VERSION ""

NS_ :

BS_:

BU_: TBox

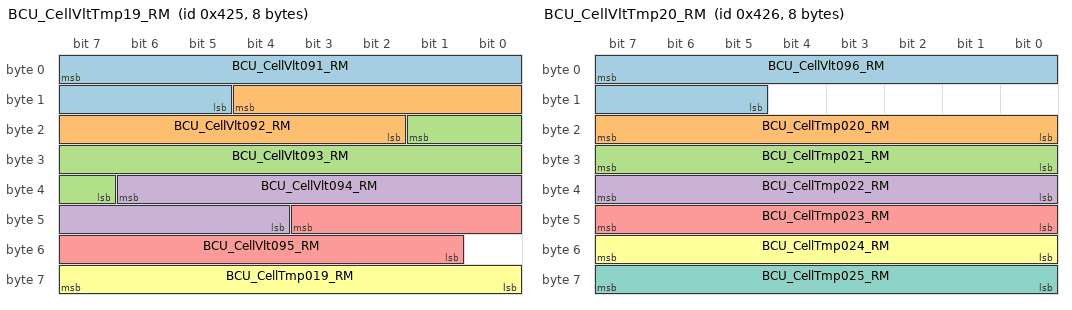
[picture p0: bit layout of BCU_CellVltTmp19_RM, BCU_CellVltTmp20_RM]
BO_ 1061 BCU_CellVltTmp19_RM: 8 CGW
 SG_ BCU_CellVlt091_RM : 7|11@0+ (0.01,0) [0|18] "V" TBox
 SG_ BCU_CellVlt092_RM : 12|11@0+ (0.01,0) [0|18] "V" TBox
 SG_ BCU_CellVlt093_RM : 17|11@0+ (0.01,0) [0|18] "V" TBox
 SG_ BCU_CellVlt094_RM : 38|11@0+ (0.01,0) [0|18] "V" TBox
 SG_ BCU_CellVlt095_RM : 43|11@0+ (0.01,0) [0|18] "V" TBox
 SG_ BCU_CellTmp019_RM : 63|8@0+ (1,-40) [-40|120] "℃" TBox

BO_ 1062 BCU_CellVltTmp20_RM: 8 CGW
 SG_ BCU_CellVlt096_RM : 7|11@0+ (0.01,0) [0|18] "V" TBox
 SG_ BCU_CellTmp020_RM : 23|8@0+ (1,-40) [-40|120] "℃" TBox
 SG_ BCU_CellTmp021_RM : 31|8@0+ (1,-40) [-40|120] "℃" TBox
 SG_ BCU_CellTmp022_RM : 39|8@0+ (1,-40) [-40|120] "℃" TBox
 SG_ BCU_CellTmp023_RM : 47|8@0+ (1,-40) [-40|120] "℃" TBox
 SG_ BCU_CellTmp024_RM : 55|8@0+ (1,-40) [-40|120] "℃" TBox
 SG_ BCU_CellTmp025_RM : 63|8@0+ (1,-40) [-40|120] "℃" TBox

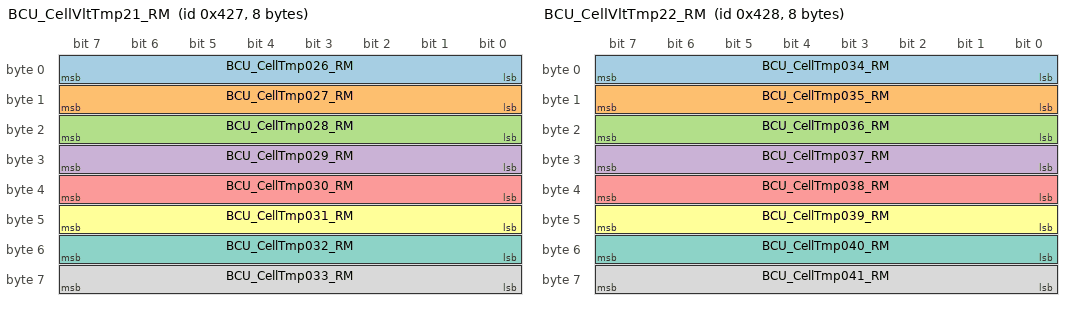
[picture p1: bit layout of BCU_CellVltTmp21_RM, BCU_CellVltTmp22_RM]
BO_ 1063 BCU_CellVltTmp21_RM: 8 CGW
 SG_ BCU_CellTmp026_RM : 7|8@0+ (1,-40) [-40|120] "℃" TBox
 SG_ BCU_CellTmp027_RM : 15|8@0+ (1,-40) [-40|120] "℃" TBox
 SG_ BCU_CellTmp028_RM : 23|8@0+ (1,-40) [-40|120] "℃" TBox
 SG_ BCU_CellTmp029_RM : 31|8@0+ (1,-40) [-40|120] "℃" TBox
 SG_ BCU_CellTmp030_RM : 39|8@0+ (1,-40) [-40|120] "℃" TBox
 SG_ BCU_CellTmp031_RM : 47|8@0+ (1,-40) [-40|120] "℃" TBox
 SG_ BCU_CellTmp032_RM : 55|8@0+ (1,-40) [-40|120] "℃" TBox
 SG_ BCU_CellTmp033_RM : 63|8@0+ (1,-40) [-40|120] "℃" TBox

BO_ 1064 BCU_CellVltTmp22_RM: 8 CGW
 SG_ BCU_CellTmp034_RM : 7|8@0+ (1,-40) [-40|120] "℃" TBox
 SG_ BCU_CellTmp035_RM : 15|8@0+ (1,-40) [-40|120] "℃" TBox
 SG_ BCU_CellTmp036_RM : 23|8@0+ (1,-40) [-40|120] "℃" TBox
 SG_ BCU_CellTmp037_RM : 31|8@0+ (1,-40) [-40|120] "℃" TBox
 SG_ BCU_CellTmp038_RM : 39|8@0+ (1,-40) [-40|120] "℃" TBox
 SG_ BCU_CellTmp039_RM : 47|8@0+ (1,-40) [-40|120] "℃" TBox
 SG_ BCU_CellTmp040_RM : 55|8@0+ (1,-40) [-40|120] "℃" TBox
 SG_ BCU_CellTmp041_RM : 63|8@0+ (1,-40) [-40|120] "℃" TBox

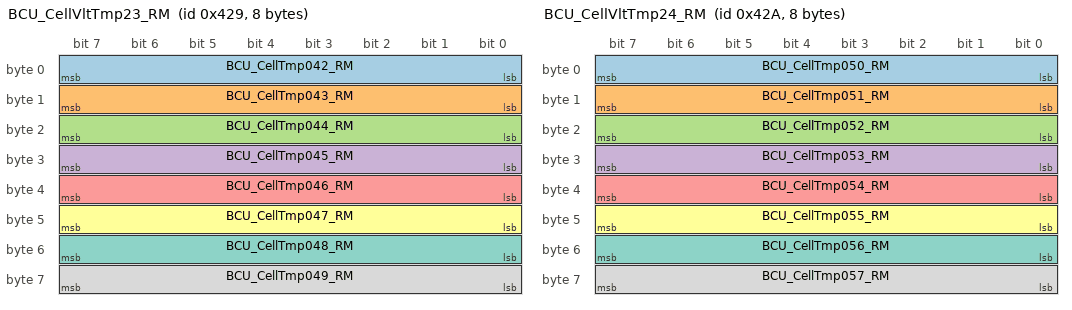
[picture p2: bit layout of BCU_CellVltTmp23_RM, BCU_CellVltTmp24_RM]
BO_ 1065 BCU_CellVltTmp23_RM: 8 CGW
 SG_ BCU_CellTmp042_RM : 7|8@0+ (1,-40) [-40|120] "℃" TBox
 SG_ BCU_CellTmp043_RM : 15|8@0+ (1,-40) [-40|120] "℃" TBox
 SG_ BCU_CellTmp044_RM : 23|8@0+ (1,-40) [-40|120] "℃" TBox
 SG_ BCU_CellTmp045_RM : 31|8@0+ (1,-40) [-40|120] "℃" TBox
 SG_ BCU_CellTmp046_RM : 39|8@0+ (1,-40) [-40|120] "℃" TBox
 SG_ BCU_CellTmp047_RM : 47|8@0+ (1,-40) [-40|120] "℃" TBox
 SG_ BCU_CellTmp048_RM : 55|8@0+ (1,-40) [-40|120] "℃" TBox
 SG_ BCU_CellTmp049_RM : 63|8@0+ (1,-40) [-40|120] "℃" TBox

BO_ 1066 BCU_CellVltTmp24_RM: 8 CGW
 SG_ BCU_CellTmp050_RM : 7|8@0+ (1,-40) [-40|120] "℃" TBox
 SG_ BCU_CellTmp051_RM : 15|8@0+ (1,-40) [-40|120] "℃" TBox
 SG_ BCU_CellTmp052_RM : 23|8@0+ (1,-40) [-40|120] "℃" TBox
 SG_ BCU_CellTmp053_RM : 31|8@0+ (1,-40) [-40|120] "℃" TBox
 SG_ BCU_CellTmp054_RM : 39|8@0+ (1,-40) [-40|120] "℃" TBox
 SG_ BCU_CellTmp055_RM : 47|8@0+ (1,-40) [-40|120] "℃" TBox
 SG_ BCU_CellTmp056_RM : 55|8@0+ (1,-40) [-40|120] "℃" TBox
 SG_ BCU_CellTmp057_RM : 63|8@0+ (1,-40) [-40|120] "℃" TBox

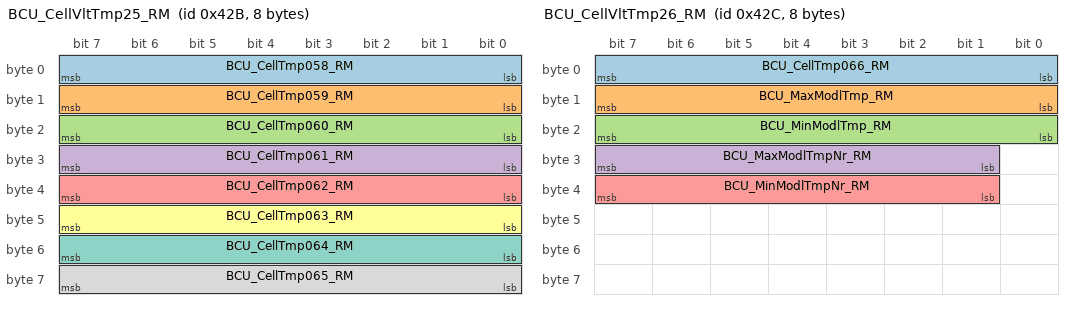
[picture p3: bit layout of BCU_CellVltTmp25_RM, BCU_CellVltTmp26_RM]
BO_ 1067 BCU_CellVltTmp25_RM: 8 CGW
 SG_ BCU_CellTmp058_RM : 7|8@0+ (1,-40) [-40|120] "℃" TBox
 SG_ BCU_CellTmp059_RM : 15|8@0+ (1,-40) [-40|120] "℃" TBox
 SG_ BCU_CellTmp060_RM : 23|8@0+ (1,-40) [-40|120] "℃" TBox
 SG_ BCU_CellTmp061_RM : 31|8@0+ (1,-40) [-40|120] "℃" TBox
 SG_ BCU_CellTmp062_RM : 39|8@0+ (1,-40) [-40|120] "℃" TBox
 SG_ BCU_CellTmp063_RM : 47|8@0+ (1,-40) [-40|120] "℃" TBox
 SG_ BCU_CellTmp064_RM : 55|8@0+ (1,-40) [-40|120] "℃" TBox
 SG_ BCU_CellTmp065_RM : 63|8@0+ (1,-40) [-40|120] "℃" TBox

BO_ 1068 BCU_CellVltTmp26_RM: 8 CGW
 SG_ BCU_CellTmp066_RM : 7|8@0+ (1,-40) [-40|120] "℃" TBox
 SG_ BCU_MaxModlTmp_RM : 15|8@0+ (1,-40) [-40|120] "℃" TBox
 SG_ BCU_MinModlTmp_RM : 23|8@0+ (1,-40) [-40|120] "℃" TBox
 SG_ BCU_MaxModlTmpNr_RM : 31|7@0+ (1,0) [0|120] "℃" TBox
 SG_ BCU_MinModlTmpNr_RM : 39|7@0+ (1,0) [0|120] "℃" TBox

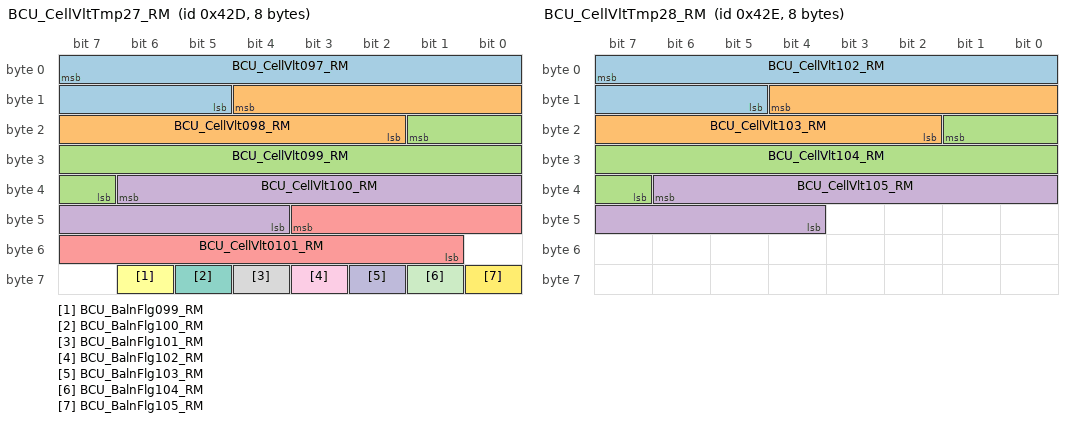
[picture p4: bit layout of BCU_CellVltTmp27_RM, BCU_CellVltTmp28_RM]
BO_ 1069 BCU_CellVltTmp27_RM: 8 CGW
 SG_ BCU_CellVlt097_RM : 7|11@0+ (0.01,0) [0|18] "V" TBox
 SG_ BCU_CellVlt098_RM : 12|11@0+ (0.01,0) [0|18] "V" TBox
 SG_ BCU_CellVlt099_RM : 17|11@0+ (0.01,0) [0|18] "V" TBox
 SG_ BCU_CellVlt100_RM : 38|11@0+ (0.01,0) [0|18] "V" TBox
 SG_ BCU_CellVlt0101_RM : 43|11@0+ (0.01,0) [0|18] "V" TBox
 SG_ BCU_BalnFlg099_RM : 62|1@0+ (1,0) [0|1] "" TBox
 SG_ BCU_BalnFlg100_RM : 61|1@0+ (1,0) [0|1] "" TBox
 SG_ BCU_BalnFlg101_RM : 60|1@0+ (1,0) [0|1] "" TBox
 SG_ BCU_BalnFlg102_RM : 59|1@0+ (1,0) [0|1] "" TBox
 SG_ BCU_BalnFlg103_RM : 58|1@0+ (1,0) [0|1] "" TBox
 SG_ BCU_BalnFlg104_RM : 57|1@0+ (1,0) [0|1] "" TBox
 SG_ BCU_BalnFlg105_RM : 56|1@0+ (1,0) [0|1] "" TBox

BO_ 1070 BCU_CellVltTmp28_RM: 8 CGW
 SG_ BCU_CellVlt102_RM : 7|11@0+ (0.01,0) [0|18] "V" TBox
 SG_ BCU_CellVlt103_RM : 12|11@0+ (0.01,0) [0|18] "V" TBox
 SG_ BCU_CellVlt104_RM : 17|11@0+ (0.01,0) [0|18] "V" TBox
 SG_ BCU_CellVlt105_RM : 38|11@0+ (0.01,0) [0|18] "V" TBox

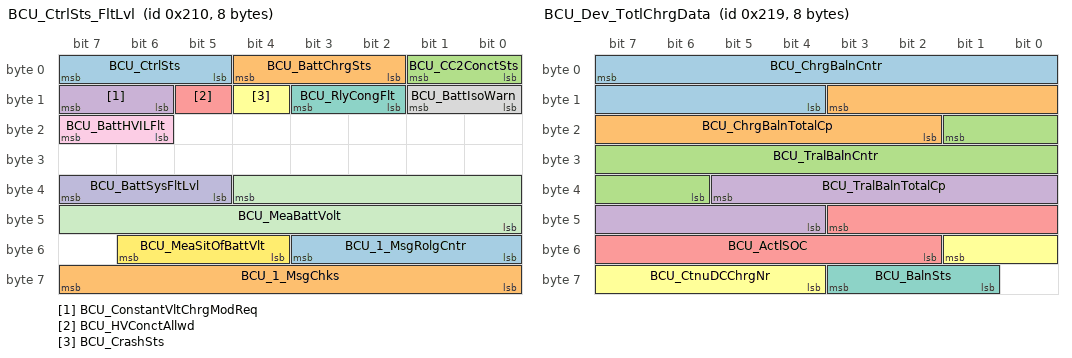
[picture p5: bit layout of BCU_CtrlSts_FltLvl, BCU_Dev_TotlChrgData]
BO_ 528 BCU_CtrlSts_FltLvl: 8 CGW
 SG_ BCU_CtrlSts : 7|3@0+ (1,0) [0|7] "" TBox
 SG_ BCU_BattChrgSts : 4|3@0+ (1,0) [0|7] "" TBox
 SG_ BCU_CC2ConctSts : 1|2@0+ (1,0) [0|3] "" TBox
 SG_ BCU_ConstantVltChrgModReq : 15|2@0+ (1,0) [0|3] "" TBox
 SG_ BCU_HVConctAllwd : 13|1@0+ (1,0) [0|1] "" TBox
 SG_ BCU_CrashSts : 12|1@0+ (1,0) [0|1] "" TBox
 SG_ BCU_RlyCongFlt : 11|2@0+ (1,0) [0|3] "" TBox
 SG_ BCU_BattIsoWarn : 9|2@0+ (1,0) [0|3] "" TBox
 SG_ BCU_BattHVILFlt : 23|2@0+ (1,0) [0|3] "" TBox
 SG_ BCU_BattSysFltLvl : 39|3@0+ (1,0) [0|7] "" TBox
 SG_ BCU_MeaBattVolt : 36|13@0+ (0.1,0) [0|500] "V" TBox
 SG_ BCU_MeaSitOfBattVlt : 54|3@0+ (1,0) [0|7] "" TBox
 SG_ BCU_1_MsgRolgCntr : 51|4@0+ (1,0) [0|15] "" TBox
 SG_ BCU_1_MsgChks : 63|8@0+ (1,0) [0|255] "" TBox

BO_ 537 BCU_Dev_TotlChrgData: 8 CGW
 SG_ BCU_ChrgBalnCntr : 7|12@0+ (1,0) [0|4000] "" TBox
 SG_ BCU_ChrgBalnTotalCp : 11|10@0+ (1,0) [0|1000] "" TBox
 SG_ BCU_TralBalnCntr : 17|12@0+ (1,0) [0|4000] "" TBox
 SG_ BCU_TralBalnTotalCp : 37|10@0+ (1,0) [0|1000] "" TBox
 SG_ BCU_ActlSOC : 43|10@0+ (0.1,0) [0|100] "" TBox
 SG_ BCU_CtnuDCChrgNr : 49|6@0+ (1,0) [0|60] "" TBox
 SG_ BCU_BalnSts : 59|3@0+ (1,0) [0|7] "" TBox

CM_ SG_ 528 BCU_CtrlSts "BCU control status 
BCU电池控制状态";
CM_ SG_ 528 BCU_BattChrgSts "Battery charge status
充电状态";
CM_ SG_ 528 BCU_CC2ConctSts "CC2 connected status
CC2连接状态";
CM_ SG_ 528 BCU_ConstantVltChrgModReq "Constant Voltage Charging Mode Request
充电恒压模式请求";
CM_ SG_ 528 BCU_HVConctAllwd "HV Connection Allowed
高压连接允许";
CM_ SG_ 528 BCU_CrashSts "BCU crash status
碰撞状态";
CM_ SG_ 528 BCU_RlyCongFlt "Relay Conglutite Fault 
继电器粘连故障";
CM_ SG_ 528 BCU_BattIsoWarn "Battery Isolation Warning 
绝缘报警";
CM_ SG_ 528 BCU_BattHVILFlt "Battery high voltage inter lock fault
电池高压互锁故障";
CM_ SG_ 528 BCU_BattSysFltLvl "Battery systerm falut level
电池系统故障等级";
CM_ SG_ 528 BCU_MeaBattVolt "Measure Battery Voltage
直采电池包电压";
CM_ SG_ 528 BCU_MeaSitOfBattVlt "Measure Sit Of Battery Voltage
直采电池包电压位置";
CM_ SG_ 528 BCU_1_MsgRolgCntr "MessageRollingCounter is from 0   
to 15 ,increase one unit on every message transmission
报文计数器";
CM_ SG_ 528 BCU_1_MsgChks "初始值0xFF
异或值0xFF
多项式0x2F
Function : calculate rule
crc = 0xFF;                            // initial value = 0xFF
for( byte_index=0; byte_index<cb_DATA_BYTE_SIZE;    ++byte_index )
{
crc ^= data_byte_array[byte_index];
for( bit_index=0; bit_index<8; ++bit_index )
{
if( (crc & 0x80) != 0 )
crc = (crc << 1) ^ cb_CRC_POLY;
else
crc = (crc << 1);
}
}
return crc= crc ^ 0FF;                            //return inverse value";
CM_ SG_ 537 BCU_ChrgBalnCntr "Charge Balance Counter
外插充电累计均衡次数";
CM_ SG_ 537 BCU_ChrgBalnTotalCp "Charge Balance Total Capacity
外插充电累计均衡容量";
CM_ SG_ 537 BCU_TralBalnCntr "Tral Balance Counter
整车工况累计均衡次数";
CM_ SG_ 537 BCU_TralBalnTotalCp "Tral Balance Total Capacity
整车工况累计均衡容量";
CM_ SG_ 537 BCU_ActlSOC "Actural SOC
电池实际SOC";
CM_ SG_ 537 BCU_CtnuDCChrgNr "Continuous DC Charge Number
连续快充次数";
CM_ SG_ 537 BCU_BalnSts "Battery Balance Status
电池均衡状态";
CM_ SG_ 1061 BCU_CellVlt091_RM "Cell voltage 091
单体电压091";
CM_ SG_ 1061 BCU_CellVlt092_RM "Cell voltage 092
单体电压092";
CM_ SG_ 1061 BCU_CellVlt093_RM "Cell voltage 093
单体电压093";
CM_ SG_ 1061 BCU_CellVlt094_RM "Cell voltage 094
单体电压094";
CM_ SG_ 1061 BCU_CellVlt095_RM "Cell voltage 095
单体电压095";
CM_ SG_ 1061 BCU_CellTmp019_RM "Cell temperature 019
单体温度019";
CM_ SG_ 1062 BCU_CellVlt096_RM "Cell voltage 096
单体电压096";
CM_ SG_ 1062 BCU_CellTmp020_RM "Cell temperature 020
单体温度020";
CM_ SG_ 1062 BCU_CellTmp021_RM "Cell temperature 021
单体温度021";
CM_ SG_ 1062 BCU_CellTmp022_RM "Cell temperature 022
单体温度022";
CM_ SG_ 1062 BCU_CellTmp023_RM "Cell temperature 023
单体温度023";
CM_ SG_ 1062 BCU_CellTmp024_RM "Cell temperature 024
单体温度024";
CM_ SG_ 1062 BCU_CellTmp025_RM "Cell temperature 025
单体温度025";
CM_ SG_ 1063 BCU_CellTmp026_RM "Cell temperature 026
单体温度026";
CM_ SG_ 1063 BCU_CellTmp027_RM "Cell temperature 027
单体温度027";
CM_ SG_ 1063 BCU_CellTmp028_RM "Cell temperature 028
单体温度028";
CM_ SG_ 1063 BCU_CellTmp029_RM "Cell temperature 029
单体温度029";
CM_ SG_ 1063 BCU_CellTmp030_RM "Cell temperature 030
单体温度030";
CM_ SG_ 1063 BCU_CellTmp031_RM "Cell temperature 031
单体温度031";
CM_ SG_ 1063 BCU_CellTmp032_RM "Cell temperature 032
单体温度032";
CM_ SG_ 1063 BCU_CellTmp033_RM "Cell temperature 033
单体温度033";
CM_ SG_ 1064 BCU_CellTmp034_RM "Cell temperature 034
单体温度034";
CM_ SG_ 1064 BCU_CellTmp035_RM "Cell temperature 035
单体温度035";
CM_ SG_ 1064 BCU_CellTmp036_RM "Cell temperature 036
单体温度036";
CM_ SG_ 1064 BCU_CellTmp037_RM "Cell temperature 037
单体温度037";
CM_ SG_ 1064 BCU_CellTmp038_RM "Cell temperature 038
单体温度038";
CM_ SG_ 1064 BCU_CellTmp039_RM "Cell temperature 039
单体温度039";
CM_ SG_ 1064 BCU_CellTmp040_RM "Cell temperature 040
单体温度040";
CM_ SG_ 1064 BCU_CellTmp041_RM "Cell temperature 041
单体温度041";
CM_ SG_ 1065 BCU_CellTmp042_RM "Cell temperature 042
单体温度042";
CM_ SG_ 1065 BCU_CellTmp043_RM "Cell temperature 043
单体温度043";
CM_ SG_ 1065 BCU_CellTmp044_RM "Cell temperature 044
单体温度044";
CM_ SG_ 1065 BCU_CellTmp045_RM "Cell temperature 045
单体温度045";
CM_ SG_ 1065 BCU_CellTmp046_RM "Cell temperature 046
单体温度046";
CM_ SG_ 1065 BCU_CellTmp047_RM "Cell temperature 047
单体温度047";
CM_ SG_ 1065 BCU_CellTmp048_RM "Cell temperature 048
单体温度048";
CM_ SG_ 1065 BCU_CellTmp049_RM "Cell temperature 049
单体温度049";
CM_ SG_ 1066 BCU_CellTmp050_RM "Cell temperature 050
单体温度050";
CM_ SG_ 1066 BCU_CellTmp051_RM "Cell temperature 051
单体温度051";
CM_ SG_ 1066 BCU_CellTmp052_RM "Cell temperature 052
单体温度052";
CM_ SG_ 1066 BCU_CellTmp053_RM "Cell temperature 053
单体温度053";
CM_ SG_ 1066 BCU_CellTmp054_RM "Cell temperature 054
单体温度054";
CM_ SG_ 1066 BCU_CellTmp055_RM "Cell temperature 055
单体温度055";
CM_ SG_ 1066 BCU_CellTmp056_RM "Cell temperature 056
单体温度056";
CM_ SG_ 1066 BCU_CellTmp057_RM "Cell temperature 057
单体温度057";
CM_ SG_ 1067 BCU_CellTmp058_RM "Cell temperature 058
单体温度058";
CM_ SG_ 1067 BCU_CellTmp059_RM "Cell temperature 059
单体温度059";
CM_ SG_ 1067 BCU_CellTmp060_RM "Cell temperature 060
单体温度060";
CM_ SG_ 1067 BCU_CellTmp061_RM "Cell temperature 061
单体温度061";
CM_ SG_ 1067 BCU_CellTmp062_RM "Cell temperature 062
单体温度062";
CM_ SG_ 1067 BCU_CellTmp063_RM "Cell temperature 063
单体温度063";
CM_ SG_ 1067 BCU_CellTmp064_RM "Cell temperature 064
单体温度064";
CM_ SG_ 1067 BCU_CellTmp065_RM "Cell temperature 065
单体温度065";
CM_ SG_ 1068 BCU_CellTmp066_RM "Cell temperature 066
单体温度066";
CM_ SG_ 1068 BCU_MaxModlTmp_RM "Module Max Tempeture_RM
模组最高温度";
CM_ SG_ 1068 BCU_MinModlTmp_RM "Module Min Tempeture_RM
模组最低温度";
CM_ SG_ 1068 BCU_MaxModlTmpNr_RM "Max module tempeture number_RM
模组最高温度对应的编号";
CM_ SG_ 1068 BCU_MinModlTmpNr_RM "Min module tempeture numberr_RM
模组最低温度对应的编号";
CM_ SG_ 1069 BCU_CellVlt097_RM "Cell voltage 097
单体电压097";
CM_ SG_ 1069 BCU_CellVlt098_RM "Cell voltage 098
单体电压098";
CM_ SG_ 1069 BCU_CellVlt099_RM "Cell voltage 099
单体电压099";
CM_ SG_ 1069 BCU_CellVlt100_RM "Cell voltage 100
单体电压100";
CM_ SG_ 1069 BCU_CellVlt0101_RM "Cell voltage 101
单体电压101";
CM_ SG_ 1069 BCU_BalnFlg099_RM "Cell Balance Flag
单体均衡标志位099";
CM_ SG_ 1069 BCU_BalnFlg100_RM "Cell Balance Flag
单体均衡标志位100";
CM_ SG_ 1069 BCU_BalnFlg101_RM "Cell Balance Flag
单体均衡标志位101";
CM_ SG_ 1069 BCU_BalnFlg102_RM "Cell Balance Flag
单体均衡标志位102";
CM_ SG_ 1069 BCU_BalnFlg103_RM "Cell Balance Flag
单体均衡标志位103";
CM_ SG_ 1069 BCU_BalnFlg104_RM "Cell Balance Flag
单体均衡标志位104";
CM_ SG_ 1069 BCU_BalnFlg105_RM "Cell Balance Flag
单体均衡标志位105";
CM_ SG_ 1070 BCU_CellVlt102_RM "Cell voltage 102
单体电压102";
CM_ SG_ 1070 BCU_CellVlt103_RM "Cell voltage 103
单体电压103";
CM_ SG_ 1070 BCU_CellVlt104_RM "Cell voltage 104
单体电压104";
CM_ SG_ 1070 BCU_CellVlt105_RM "Cell voltage 105
单体电压105";

BA_DEF_ BO_  "NmMessage" ENUM "No","Yes";
BA_DEF_ BO_  "GenMsgSendType" ENUM  "Cycle","CA","CE","Event","NotUsed","NotUsed","NotUsed","IfActive","NoMsgSendType","NotUsed";
BA_DEF_ BO_  "GenMsgCycleTime" INT 0 0;
BA_DEF_ SG_  "GenSigSendType" ENUM  "Cycle","OnChange","OnWrite","IfActive","OnChangeWithRepetition","OnWriteWithRepetition","IfActiveWithRepetition";
BA_DEF_ SG_  "GenSigStartValue" INT 0 0;
BA_DEF_ BO_  "GenMsgCycleTimeFast" INT 0 0;
BA_DEF_ BO_  "GenMsgNrOfRepetition" INT 0 0;
BA_DEF_ BO_  "GenMsgDelayTime" INT 0 0;
BA_DEF_ BO_  "VFrameFormat" ENUM  "StandardCAN","ExtendedCAN","reserved","reserved","reserved","reserved","reserved","reserved","reserved","reserved","reserved","reserved","reserved","reserved","StandardCAN_FD","ExtendedCAN_FD";
BA_DEF_ BO_  "GenMsgCycleTimeActive" INT 0 500;
BA_DEF_ BO_  "GenMsgStartDelayTime" INT 0 500;

BA_DEF_DEF_  "NmMessage" "No";
BA_DEF_DEF_  "GenMsgSendType" "Cycle";
BA_DEF_DEF_  "GenMsgCycleTime" 0;
BA_DEF_DEF_  "GenSigSendType" "Cycle";
BA_DEF_DEF_  "GenSigStartValue" 0;
BA_DEF_DEF_  "GenMsgCycleTimeFast" 0;
BA_DEF_DEF_  "GenMsgNrOfRepetition" 0;
BA_DEF_DEF_  "GenMsgDelayTime" 0;
BA_DEF_DEF_  "VFrameFormat" "StandardCAN";
BA_DEF_DEF_  "GenMsgCycleTimeActive" 100;
BA_DEF_DEF_  "GenMsgStartDelayTime" 200;
BA_ "GenMsgCycleTime" BO_ 1061 1000;
BA_ "GenSigStartValue" SG_ 1061 BCU_CellTmp019_RM 40;
BA_ "GenMsgCycleTime" BO_ 1062 1000;
BA_ "GenSigStartValue" SG_ 1062 BCU_CellTmp020_RM 40;
BA_ "GenSigStartValue" SG_ 1062 BCU_CellTmp021_RM 40;
BA_ "GenSigStartValue" SG_ 1062 BCU_CellTmp022_RM 40;
BA_ "GenSigStartValue" SG_ 1062 BCU_CellTmp023_RM 40;
BA_ "GenSigStartValue" SG_ 1062 BCU_CellTmp024_RM 40;
BA_ "GenSigStartValue" SG_ 1062 BCU_CellTmp025_RM 40;
BA_ "GenMsgCycleTime" BO_ 1063 1000;
BA_ "GenSigStartValue" SG_ 1063 BCU_CellTmp026_RM 40;
BA_ "GenSigStartValue" SG_ 1063 BCU_CellTmp027_RM 40;
BA_ "GenSigStartValue" SG_ 1063 BCU_CellTmp028_RM 40;
BA_ "GenSigStartValue" SG_ 1063 BCU_CellTmp029_RM 40;
BA_ "GenSigStartValue" SG_ 1063 BCU_CellTmp030_RM 40;
BA_ "GenSigStartValue" SG_ 1063 BCU_CellTmp031_RM 40;
BA_ "GenSigStartValue" SG_ 1063 BCU_CellTmp032_RM 40;
BA_ "GenSigStartValue" SG_ 1063 BCU_CellTmp033_RM 40;
BA_ "GenMsgCycleTime" BO_ 1064 1000;
BA_ "GenSigStartValue" SG_ 1064 BCU_CellTmp034_RM 40;
BA_ "GenSigStartValue" SG_ 1064 BCU_CellTmp035_RM 40;
BA_ "GenSigStartValue" SG_ 1064 BCU_CellTmp036_RM 40;
BA_ "GenSigStartValue" SG_ 1064 BCU_CellTmp037_RM 40;
BA_ "GenSigStartValue" SG_ 1064 BCU_CellTmp038_RM 40;
BA_ "GenSigStartValue" SG_ 1064 BCU_CellTmp039_RM 40;
BA_ "GenSigStartValue" SG_ 1064 BCU_CellTmp040_RM 40;
BA_ "GenSigStartValue" SG_ 1064 BCU_CellTmp041_RM 40;
BA_ "GenMsgCycleTime" BO_ 1065 1000;
BA_ "GenSigStartValue" SG_ 1065 BCU_CellTmp042_RM 40;
BA_ "GenSigStartValue" SG_ 1065 BCU_CellTmp043_RM 40;
BA_ "GenSigStartValue" SG_ 1065 BCU_CellTmp044_RM 40;
BA_ "GenSigStartValue" SG_ 1065 BCU_CellTmp045_RM 40;
BA_ "GenSigStartValue" SG_ 1065 BCU_CellTmp046_RM 40;
BA_ "GenSigStartValue" SG_ 1065 BCU_CellTmp047_RM 40;
BA_ "GenSigStartValue" SG_ 1065 BCU_CellTmp048_RM 40;
BA_ "GenSigStartValue" SG_ 1065 BCU_CellTmp049_RM 40;
BA_ "GenMsgCycleTime" BO_ 1066 1000;
BA_ "GenSigStartValue" SG_ 1066 BCU_CellTmp050_RM 40;
BA_ "GenSigStartValue" SG_ 1066 BCU_CellTmp051_RM 40;
BA_ "GenSigStartValue" SG_ 1066 BCU_CellTmp052_RM 40;
BA_ "GenSigStartValue" SG_ 1066 BCU_CellTmp053_RM 40;
BA_ "GenSigStartValue" SG_ 1066 BCU_CellTmp054_RM 40;
BA_ "GenSigStartValue" SG_ 1066 BCU_CellTmp055_RM 40;
BA_ "GenSigStartValue" SG_ 1066 BCU_CellTmp056_RM 40;
BA_ "GenSigStartValue" SG_ 1066 BCU_CellTmp057_RM 40;
BA_ "GenMsgCycleTime" BO_ 1067 1000;
BA_ "GenSigStartValue" SG_ 1067 BCU_CellTmp058_RM 40;
BA_ "GenSigStartValue" SG_ 1067 BCU_CellTmp059_RM 40;
BA_ "GenSigStartValue" SG_ 1067 BCU_CellTmp060_RM 40;
BA_ "GenSigStartValue" SG_ 1067 BCU_CellTmp061_RM 40;
BA_ "GenSigStartValue" SG_ 1067 BCU_CellTmp062_RM 40;
BA_ "GenSigStartValue" SG_ 1067 BCU_CellTmp063_RM 40;
BA_ "GenSigStartValue" SG_ 1067 BCU_CellTmp064_RM 40;
BA_ "GenSigStartValue" SG_ 1067 BCU_CellTmp065_RM 40;
BA_ "GenMsgCycleTime" BO_ 1068 1000;
BA_ "GenSigStartValue" SG_ 1068 BCU_CellTmp066_RM 40;
BA_ "GenSigStartValue" SG_ 1068 BCU_MaxModlTmp_RM 40;
BA_ "GenSigStartValue" SG_ 1068 BCU_MinModlTmp_RM 40;
BA_ "GenMsgCycleTime" BO_ 1069 1000;
BA_ "GenMsgCycleTime" BO_ 1070 1000;
BA_ "GenMsgCycleTime" BO_ 528 10;
BA_ "GenMsgCycleTime" BO_ 537 1000;
VAL_ 528 BCU_CtrlSts 7 "Shutdown" 6 "Failure" 5 "Powerdown" 4 "Normal/HVActive" 3 "PreChargeOK" 2 "PreCharge" 1 "Standby" 0 "Initializing" ;
VAL_ 528 BCU_BattChrgSts 7 "Reserved" 6 "Reserved" 5 "Charging normally stop" 4 "Chag stop because charg fault" 3 "Chrg stop because charg full" 2 "DC Charging" 1 "AC Charging" 0 "No Charging" ;
VAL_ 528 BCU_CC2ConctSts 3 "Reserved" 2 "Error" 1 "Connected" 0 "Not Connect" ;
VAL_ 528 BCU_ConstantVltChrgModReq 3 "Reserved" 2 "ReqExit ConstantVltMod" 1 "ReqEnter ConstantVltMod" 0 "No Req" ;
VAL_ 528 BCU_HVConctAllwd 1 "Allowed" 0 "Not Allowed" ;
VAL_ 528 BCU_CrashSts 1 "Crashed" 0 "No crash" ;
VAL_ 528 BCU_RlyCongFlt 3 "Reserved" 2 "Error" 1 "Fault" 0 "No fault" ;
VAL_ 528 BCU_BattIsoWarn 3 "Reserved" 2 "Error" 1 "Fault" 0 "No fault" ;
VAL_ 528 BCU_BattHVILFlt 3 "Reserved" 2 "Error" 1 "Fault" 0 "No fault" ;
VAL_ 528 BCU_BattSysFltLvl 7 "Reserved" 6 "Level VI" 5 "Level V" 4 "Level Ⅳ" 3 "Level III(SecondarySeriousFlt)" 2 "Level II(Normal fault)" 1 "Level I(Mirro fault, no action)" 0 "Not Fault" ;
VAL_ 528 BCU_MeaBattVolt 8191 "Invalid" 8190 "Invalid" 8189 "Invalid" 8188 "Invalid" 8187 "Invalid" 8186 "Invalid" 8185 "Invalid" 8184 "Invalid" 8183 "Invalid" 8182 "Invalid" 8181 "Invalid" 8180 "Invalid" 8179 "Invalid" 8178 "Invalid" 8177 "Invalid" 8176 "Invalid" 8175 "Invalid" 8174 "Invalid" 8173 "Invalid" 8172 "Invalid" 8171 "Invalid" 8170 "Invalid" 8169 "Invalid" 8168 "Invalid" 8167 "Invalid" 8166 "Invalid" 8165 "Invalid" 8164 "Invalid" 8163 "Invalid" 8162 "Invalid" 8161 "Invalid" 8160 "Invalid" 8159 "Invalid" 8158 "Invalid" 8157 "Invalid" 8156 "Invalid" 8155 "Invalid" 8154 "Invalid" 8153 "Invalid" 8152 "Invalid" 8151 "Invalid" 8150 "Invalid" 8149 "Invalid" 8148 "Invalid" 8147 "Invalid" 8146 "Invalid" 8145 "Invalid" 8144 "Invalid" 8143 "Invalid" 8142 "Invalid" 8141 "Invalid" 8140 "Invalid" 8139 "Invalid" 8138 "Invalid" 8137 "Invalid" 8136 "Invalid" 8135 "Invalid" 8134 "Invalid" 8133 "Invalid" 8132 "Invalid" 8131 "Invalid" 8130 "Invalid" 8129 "Invalid" 8128 "Invalid" 8127 "Invalid" 8126 "Invalid" 8125 "Invalid" 8124 "Invalid" 8123 "Invalid" 8122 "Invalid" 8121 "Invalid" 8120 "Invalid" 8119 "Invalid" 8118 "Invalid" 8117 "Invalid" 8116 "Invalid" 8115 "Invalid" 8114 "Invalid" 8113 "Invalid" 8112 "Invalid" 8111 "Invalid" 8110 "Invalid" 8109 "Invalid" 8108 "Invalid" 8107 "Invalid" 8106 "Invalid" 8105 "Invalid" 8104 "Invalid" 8103 "Invalid" 8102 "Invalid" 8101 "Invalid" 8100 "Invalid" 8099 "Invalid" 8098 "Invalid" 8097 "Invalid" 8096 "Invalid" 8095 "Invalid" 8094 "Invalid" 8093 "Invalid" 8092 "Invalid" 8091 "Invalid" 8090 "Invalid" 8089 "Invalid" 8088 "Invalid" 8087 "Invalid" 8086 "Invalid" 8085 "Invalid" 8084 "Invalid" 8083 "Invalid" 8082 "Invalid" 8081 "Invalid" 8080 "Invalid" 8079 "Invalid" 8078 "Invalid" 8077 "Invalid" 8076 "Invalid" 8075 "Invalid" 8074 "Invalid" 8073 "Invalid" 8072 "Invalid" 8071 "Invalid" 8070 "Invalid" 8069 "Invalid" 8068 "Invalid" 8067 "Invalid" 8066 "Invalid" 8065 "Invalid" 8064 "Invalid" 8063 "Invalid" 8062 "Invalid" 8061 "Invalid" 8060 "Invalid" 8059 "Invalid" 8058 "Invalid" 8057 "Invalid" 8056 "Invalid" 8055 "Invalid" 8054 "Invalid" 8053 "Invalid" 8052 "Invalid" 8051 "Invalid" 8050 "Invalid" 8049 "Invalid" 8048 "Invalid" 8047 "Invalid" 8046 "Invalid" 8045 "Invalid" 8044 "Invalid" 8043 "Invalid" 8042 "Invalid" 8041 "Invalid" 8040 "Invalid" 8039 "Invalid" 8038 "Invalid" 8037 "Invalid" 8036 "Invalid" 8035 "Invalid" 8034 "Invalid" 8033 "Invalid" 8032 "Invalid" 8031 "Invalid" 8030 "Invalid" 8029 "Invalid" 8028 "Invalid" 8027 "Invalid" 8026 "Invalid" 8025 "Invalid" 8024 "Invalid" 8023 "Invalid" 8022 "Invalid" 8021 "Invalid" 8020 "Invalid" 8019 "Invalid" 8018 "Invalid" 8017 "Invalid" 8016 "Invalid" 8015 "Invalid" 8014 "Invalid" 8013 "Invalid" 8012 "Invalid" 8011 "Invalid" 8010 "Invalid" 8009 "Invalid" 8008 "Invalid" 8007 "Invalid" 8006 "Invalid" 8005 "Invalid" 8004 "Invalid" 8003 "Invalid" 8002 "Invalid" 8001 "Invalid" 8000 "Invalid" 7999 "Invalid" 7998 "Invalid" 7997 "Invalid" 7996 "Invalid" 7995 "Invalid" 7994 "Invalid" 7993 "Invalid" 7992 "Invalid" 7991 "Invalid" 7990 "Invalid" 7989 "Invalid" 7988 "Invalid" 7987 "Invalid" 7986 "Invalid" 7985 "Invalid" 7984 "Invalid" 7983 "Invalid" 7982 "Invalid" 7981 "Invalid" 7980 "Invalid" 7979 "Invalid" 7978 "Invalid" 7977 "Invalid" 7976 "Invalid" 7975 "Invalid" 7974 "Invalid" 7973 "Invalid" 7972 "Invalid" 7971 "Invalid" 7970 "Invalid" 7969 "Invalid" 7968 "Invalid" 7967 "Invalid" 7966 "Invalid" 7965 "Invalid" 7964 "Invalid" 7963 "Invalid" 7962 "Invalid" 7961 "Invalid" 7960 "Invalid" 7959 "Invalid" 7958 "Invalid" 7957 "Invalid" 7956 "Invalid" 7955 "Invalid" 7954 "Invalid" 7953 "Invalid" 7952 "Invalid" 7951 "Invalid" 7950 "Invalid" 7949 "Invalid" 7948 "Invalid" 7947 "Invalid" 7946 "Invalid" 7945 "Invalid" 7944 "Invalid" 7943 "Invalid" 7942 "Invalid" 7941 "Invalid" 7940 "Invalid" 7939 "Invalid" 7938 "Invalid" 7937 "Invalid" 7936 "Invalid" 7935 "Invalid" 7934 "Invalid" 7933 "Invalid" 7932 "Invalid" 7931 "Invalid" 7930 "Invalid" 7929 "Invalid" 7928 "Invalid" 7927 "Invalid" 7926 "Invalid" 7925 "Invalid" 7924 "Invalid" 7923 "Invalid" 7922 "Invalid" 7921 "Invalid" 7920 "Invalid" 7919 "Invalid" 7918 "Invalid" 7917 "Invalid" 7916 "Invalid" 7915 "Invalid" 7914 "Invalid" 7913 "Invalid" 7912 "Invalid" 7911 "Invalid" 7910 "Invalid" 7909 "Invalid" 7908 "Invalid" 7907 "Invalid" 7906 "Invalid" 7905 "Invalid" 7904 "Invalid" 7903 "Invalid" 7902 "Invalid" 7901 "Invalid" 7900 "Invalid" 7899 "Invalid" 7898 "Invalid" 7897 "Invalid" 7896 "Invalid" 7895 "Invalid" 7894 "Invalid" 7893 "Invalid" 7892 "Invalid" 7891 "Invalid" 7890 "Invalid" 7889 "Invalid" 7888 "Invalid" 7887 "Invalid" 7886 "Invalid" 7885 "Invalid" 7884 "Invalid" 7883 "Invalid" 7882 "Invalid" 7881 "Invalid" 7880 "Invalid" 7879 "Invalid" 7878 "Invalid" 7877 "Invalid" 7876 "Invalid" 7875 "Invalid" 7874 "Invalid" 7873 "Invalid" 7872 "Invalid" 7871 "Invalid" 7870 "Invalid" 7869 "Invalid" 7868 "Invalid" 7867 "Invalid" 7866 "Invalid" 7865 "Invalid" 7864 "Invalid" 7863 "Invalid" 7862 "Invalid" 7861 "Invalid" 7860 "Invalid" 7859 "Invalid" 7858 "Invalid" 7857 "Invalid" 7856 "Invalid" 7855 "Invalid" 7854 "Invalid" 7853 "Invalid" 7852 "Invalid" 7851 "Invalid" 7850 "Invalid" 7849 "Invalid" 7848 "Invalid" 7847 "Invalid" 7846 "Invalid" 7845 "Invalid" 7844 "Invalid" 7843 "Invalid" 7842 "Invalid" 7841 "Invalid" 7840 "Invalid" 7839 "Invalid" 7838 "Invalid" 7837 "Invalid" 7836 "Invalid" 7835 "Invalid" 7834 "Invalid" 7833 "Invalid" 7832 "Invalid" 7831 "Invalid" 7830 "Invalid" 7829 "Invalid" 7828 "Invalid" 7827 "Invalid" 7826 "Invalid" 7825 "Invalid" 7824 "Invalid" 7823 "Invalid" 7822 "Invalid" 7821 "Invalid" 7820 "Invalid" 7819 "Invalid" 7818 "Invalid" 7817 "Invalid" 7816 "Invalid" 7815 "Invalid" 7814 "Invalid" 7813 "Invalid" 7812 "Invalid" 7811 "Invalid" 7810 "Invalid" 7809 "Invalid" 7808 "Invalid" 7807 "Invalid" 7806 "Invalid" 7805 "Invalid" 7804 "Invalid" 7803 "Invalid" 7802 "Invalid" 7801 "Invalid" 7800 "Invalid" 7799 "Invalid" 7798 "Invalid" 7797 "Invalid" 7796 "Invalid" 7795 "Invalid" 7794 "Invalid" 7793 "Invalid" 7792 "Invalid" 7791 "Invalid" 7790 "Invalid" 7789 "Invalid" 7788 "Invalid" 7787 "Invalid" 7786 "Invalid" 7785 "Invalid" 7784 "Invalid" 7783 "Invalid" 7782 "Invalid" 7781 "Invalid" 7780 "Invalid" 7779 "Invalid" 7778 "Invalid" 7777 "Invalid" 7776 "Invalid" 7775 "Invalid" 7774 "Invalid" 7773 "Invalid" 7772 "Invalid" 7771 "Invalid" 7770 "Invalid" 7769 "Invalid" 7768 "Invalid" 7767 "Invalid" 7766 "Invalid" 7765 "Invalid" 7764 "Invalid" 7763 "Invalid" 7762 "Invalid" 7761 "Invalid" 7760 "Invalid" 7759 "Invalid" 7758 "Invalid" 7757 "Invalid" 7756 "Invalid" 7755 "Invalid" 7754 "Invalid" 7753 "Invalid" 7752 "Invalid" 7751 "Invalid" 7750 "Invalid" 7749 "Invalid" 7748 "Invalid" 7747 "Invalid" 7746 "Invalid" 7745 "Invalid" 7744 "Invalid" 7743 "Invalid" 7742 "Invalid" 7741 "Invalid" 7740 "Invalid" 7739 "Invalid" 7738 "Invalid" 7737 "Invalid" 7736 "Invalid" 7735 "Invalid" 7734 "Invalid" 7733 "Invalid" 7732 "Invalid" 7731 "Invalid" 7730 "Invalid" 7729 "Invalid" 7728 "Invalid" 7727 "Invalid" 7726 "Invalid" 7725 "Invalid" 7724 "Invalid" 7723 "Invalid" 7722 "Invalid" 7721 "Invalid" 7720 "Invalid" 7719 "Invalid" 7718 "Invalid" 7717 "Invalid" 7716 "Invalid" 7715 "Invalid" 7714 "Invalid" 7713 "Invalid" 7712 "Invalid" 7711 "Invalid" 7710 "Invalid" 7709 "Invalid" 7708 "Invalid" 7707 "Invalid" 7706 "Invalid" 7705 "Invalid" 7704 "Invalid" 7703 "Invalid" 7702 "Invalid" 7701 "Invalid" 7700 "Invalid" 7699 "Invalid" 7698 "Invalid" 7697 "Invalid" 7696 "Invalid" 7695 "Invalid" 7694 "Invalid" 7693 "Invalid" 7692 "Invalid" 7691 "Invalid" 7690 "Invalid" 7689 "Invalid" 7688 "Invalid" 7687 "Invalid" 7686 "Invalid" 7685 "Invalid" 7684 "Invalid" 7683 "Invalid" 7682 "Invalid" 7681 "Invalid" 7680 "Invalid" 7679 "Invalid" 7678 "Invalid" 7677 "Invalid" 7676 "Invalid" 7675 "Invalid" 7674 "Invalid" 7673 "Invalid" 7672 "Invalid" 7671 "Invalid" 7670 "Invalid" 7669 "Invalid" 7668 "Invalid" 7667 "Invalid" 7666 "Invalid" 7665 "Invalid" 7664 "Invalid" 7663 "Invalid" 7662 "Invalid" 7661 "Invalid" 7660 "Invalid" 7659 "Invalid" 7658 "Invalid" 7657 "Invalid" 7656 "Invalid" 7655 "Invalid" 7654 "Invalid" 7653 "Invalid" 7652 "Invalid" 7651 "Invalid" 7650 "Invalid" 7649 "Invalid" 7648 "Invalid" 7647 "Invalid" 7646 "Invalid" 7645 "Invalid" 7644 "Invalid" 7643 "Invalid" 7642 "Invalid" 7641 "Invalid" 7640 "Invalid" 7639 "Invalid" 7638 "Invalid" 7637 "Invalid" 7636 "Invalid" 7635 "Invalid" 7634 "Invalid" 7633 "Invalid" 7632 "Invalid" 7631 "Invalid" 7630 "Invalid" 7629 "Invalid" 7628 "Invalid" 7627 "Invalid" 7626 "Invalid" 7625 "Invalid" 7624 "Invalid" 7623 "Invalid" 7622 "Invalid" 7621 "Invalid" 7620 "Invalid" 7619 "Invalid" 7618 "Invalid" 7617 "Invalid" 7616 "Invalid" 7615 "Invalid" 7614 "Invalid" 7613 "Invalid" 7612 "Invalid" 7611 "Invalid" 7610 "Invalid" 7609 "Invalid" 7608 "Invalid" 7607 "Invalid" 7606 "Invalid" 7605 "Invalid" 7604 "Invalid" 7603 "Invalid" 7602 "Invalid" 7601 "Invalid" 7600 "Invalid" 7599 "Invalid" 7598 "Invalid" 7597 "Invalid" 7596 "Invalid" 7595 "Invalid" 7594 "Invalid" 7593 "Invalid" 7592 "Invalid" 7591 "Invalid" 7590 "Invalid" 7589 "Invalid" 7588 "Invalid" 7587 "Invalid" 7586 "Invalid" 7585 "Invalid" 7584 "Invalid" 7583 "Invalid" 7582 "Invalid" 7581 "Invalid" 7580 "Invalid" 7579 "Invalid" 7578 "Invalid" 7577 "Invalid" 7576 "Invalid" 7575 "Invalid" 7574 "Invalid" 7573 "Invalid" 7572 "Invalid" 7571 "Invalid" 7570 "Invalid" 7569 "Invalid" 7568 "Invalid" 7567 "Invalid" 7566 "Invalid" 7565 "Invalid" 7564 "Invalid" 7563 "Invalid" 7562 "Invalid" 7561 "Invalid" 7560 "Invalid" 7559 "Invalid" 7558 "Invalid" 7557 "Invalid" 7556 "Invalid" 7555 "Invalid" 7554 "Invalid" 7553 "Invalid" 7552 "Invalid" 7551 "Invalid" 7550 "Invalid" 7549 "Invalid" 7548 "Invalid" 7547 "Invalid" 7546 "Invalid" 7545 "Invalid" 7544 "Invalid" 7543 "Invalid" 7542 "Invalid" 7541 "Invalid" 7540 "Invalid" 7539 "Invalid" 7538 "Invalid" 7537 "Invalid" 7536 "Invalid" 7535 "Invalid" 7534 "Invalid" 7533 "Invalid" 7532 "Invalid" 7531 "Invalid" 7530 "Invalid" 7529 "Invalid" 7528 "Invalid" 7527 "Invalid" 7526 "Invalid" 7525 "Invalid" 7524 "Invalid" 7523 "Invalid" 7522 "Invalid" 7521 "Invalid" 7520 "Invalid" 7519 "Invalid" 7518 "Invalid" 7517 "Invalid" 7516 "Invalid" 7515 "Invalid" 7514 "Invalid" 7513 "Invalid" 7512 "Invalid" 7511 "Invalid" 7510 "Invalid" 7509 "Invalid" 7508 "Invalid" 7507 "Invalid" 7506 "Invalid" 7505 "Invalid" 7504 "Invalid" 7503 "Invalid" 7502 "Invalid" 7501 "Invalid" 7500 "Invalid" 7499 "Invalid" 7498 "Invalid" 7497 "Invalid" 7496 "Invalid" 7495 "Invalid" 7494 "Invalid" 7493 "Invalid" 7492 "Invalid" 7491 "Invalid" 7490 "Invalid" 7489 "Invalid" 7488 "Invalid" 7487 "Invalid" 7486 "Invalid" 7485 "Invalid" 7484 "Invalid" 7483 "Invalid" 7482 "Invalid" 7481 "Invalid" 7480 "Invalid" 7479 "Invalid" 7478 "Invalid" 7477 "Invalid" 7476 "Invalid" 7475 "Invalid" 7474 "Invalid" 7473 "Invalid" 7472 "Invalid" 7471 "Invalid" 7470 "Invalid" 7469 "Invalid" 7468 "Invalid" 7467 "Invalid" 7466 "Invalid" 7465 "Invalid" 7464 "Invalid" 7463 "Invalid" 7462 "Invalid" 7461 "Invalid" 7460 "Invalid" 7459 "Invalid" 7458 "Invalid" 7457 "Invalid" 7456 "Invalid" 7455 "Invalid" 7454 "Invalid" 7453 "Invalid" 7452 "Invalid" 7451 "Invalid" 7450 "Invalid" 7449 "Invalid" 7448 "Invalid" 7447 "Invalid" 7446 "Invalid" 7445 "Invalid" 7444 "Invalid" 7443 "Invalid" 7442 "Invalid" 7441 "Invalid" 7440 "Invalid" 7439 "Invalid" 7438 "Invalid" 7437 "Invalid" 7436 "Invalid" 7435 "Invalid" 7434 "Invalid" 7433 "Invalid" 7432 "Invalid" 7431 "Invalid" 7430 "Invalid" 7429 "Invalid" 7428 "Invalid" 7427 "Invalid" 7426 "Invalid" 7425 "Invalid" 7424 "Invalid" 7423 "Invalid" 7422 "Invalid" 7421 "Invalid" 7420 "Invalid" 7419 "Invalid" 7418 "Invalid" 7417 "Invalid" 7416 "Invalid" 7415 "Invalid" 7414 "Invalid" 7413 "Invalid" 7412 "Invalid" 7411 "Invalid" 7410 "Invalid" 7409 "Invalid" 7408 "Invalid" 7407 "Invalid" 7406 "Invalid" 7405 "Invalid" 7404 "Invalid" 7403 "Invalid" 7402 "Invalid" 7401 "Invalid" 7400 "Invalid" 7399 "Invalid" 7398 "Invalid" 7397 "Invalid" 7396 "Invalid" 7395 "Invalid" 7394 "Invalid" 7393 "Invalid" 7392 "Invalid" 7391 "Invalid" 7390 "Invalid" 7389 "Invalid" 7388 "Invalid" 7387 "Invalid" 7386 "Invalid" 7385 "Invalid" 7384 "Invalid" 7383 "Invalid" 7382 "Invalid" 7381 "Invalid" 7380 "Invalid" 7379 "Invalid" 7378 "Invalid" 7377 "Invalid" 7376 "Invalid" 7375 "Invalid" 7374 "Invalid" 7373 "Invalid" 7372 "Invalid" 7371 "Invalid" 7370 "Invalid" 7369 "Invalid" 7368 "Invalid" 7367 "Invalid" 7366 "Invalid" 7365 "Invalid" 7364 "Invalid" 7363 "Invalid" 7362 "Invalid" 7361 "Invalid" 7360 "Invalid" 7359 "Invalid" 7358 "Invalid" 7357 "Invalid" 7356 "Invalid" 7355 "Invalid" 7354 "Invalid" 7353 "Invalid" 7352 "Invalid" 7351 "Invalid" 7350 "Invalid" 7349 "Invalid" 7348 "Invalid" 7347 "Invalid" 7346 "Invalid" 7345 "Invalid" 7344 "Invalid" 7343 "Invalid" 7342 "Invalid" 7341 "Invalid" 7340 "Invalid" 7339 "Invalid" 7338 "Invalid" 7337 "Invalid" 7336 "Invalid" 7335 "Invalid" 7334 "Invalid" 7333 "Invalid" 7332 "Invalid" 7331 "Invalid" 7330 "Invalid" 7329 "Invalid" 7328 "Invalid" 7327 "Invalid" 7326 "Invalid" 7325 "Invalid" 7324 "Invalid" 7323 "Invalid" 7322 "Invalid" 7321 "Invalid" 7320 "Invalid" 7319 "Invalid" 7318 "Invalid" 7317 "Invalid" 7316 "Invalid" 7315 "Invalid" 7314 "Invalid" 7313 "Invalid" 7312 "Invalid" 7311 "Invalid" 7310 "Invalid" 7309 "Invalid" 7308 "Invalid" 7307 "Invalid" 7306 "Invalid" 7305 "Invalid" 7304 "Invalid" 7303 "Invalid" 7302 "Invalid" 7301 "Invalid" 7300 "Invalid" 7299 "Invalid" 7298 "Invalid" 7297 "Invalid" 7296 "Invalid" 7295 "Invalid" 7294 "Invalid" 7293 "Invalid" 7292 "Invalid" 7291 "Invalid" 7290 "Invalid" 7289 "Invalid" 7288 "Invalid" 7287 "Invalid" 7286 "Invalid" 7285 "Invalid" 7284 "Invalid" 7283 "Invalid" 7282 "Invalid" 7281 "Invalid" 7280 "Invalid" 7279 "Invalid" 7278 "Invalid" 7277 "Invalid" 7276 "Invalid" 7275 "Invalid" 7274 "Invalid" 7273 "Invalid" 7272 "Invalid" 7271 "Invalid" 7270 "Invalid" 7269 "Invalid" 7268 "Invalid" 7267 "Invalid" 7266 "Invalid" 7265 "Invalid" 7264 "Invalid" 7263 "Invalid" 7262 "Invalid" 7261 "Invalid" 7260 "Invalid" 7259 "Invalid" 7258 "Invalid" 7257 "Invalid" 7256 "Invalid" 7255 "Invalid" 7254 "Invalid" 7253 "Invalid" 7252 "Invalid" 7251 "Invalid" 7250 "Invalid" 7249 "Invalid" 7248 "Invalid" 7247 "Invalid" 7246 "Invalid" 7245 "Invalid" 7244 "Invalid" 7243 "Invalid" 7242 "Invalid" 7241 "Invalid" 7240 "Invalid" 7239 "Invalid" 7238 "Invalid" 7237 "Invalid" 7236 "Invalid" 7235 "Invalid" 7234 "Invalid" 7233 "Invalid" 7232 "Invalid" 7231 "Invalid" 7230 "Invalid" 7229 "Invalid" 7228 "Invalid" 7227 "Invalid" 7226 "Invalid" 7225 "Invalid" 7224 "Invalid" 7223 "Invalid" 7222 "Invalid" 7221 "Invalid" 7220 "Invalid" 7219 "Invalid" 7218 "Invalid" 7217 "Invalid" 7216 "Invalid" 7215 "Invalid" 7214 "Invalid" 7213 "Invalid" 7212 "Invalid" 7211 "Invalid" 7210 "Invalid" 7209 "Invalid" 7208 "Invalid" 7207 "Invalid" 7206 "Invalid" 7205 "Invalid" 7204 "Invalid" 7203 "Invalid" 7202 "Invalid" 7201 "Invalid" 7200 "Invalid" 7199 "Invalid" 7198 "Invalid" 7197 "Invalid" 7196 "Invalid" 7195 "Invalid" 7194 "Invalid" 7193 "Invalid" 7192 "Invalid" 7191 "Invalid" 7190 "Invalid" 7189 "Invalid" 7188 "Invalid" 7187 "Invalid" 7186 "Invalid" 7185 "Invalid" 7184 "Invalid" 7183 "Invalid" 7182 "Invalid" 7181 "Invalid" 7180 "Invalid" 7179 "Invalid" 7178 "Invalid" 7177 "Invalid" 7176 "Invalid" 7175 "Invalid" 7174 "Invalid" 7173 "Invalid" 7172 "Invalid" 7171 "Invalid" 7170 "Invalid" 7169 "Invalid" 7168 "Invalid" 7167 "Invalid" 7166 "Invalid" 7165 "Invalid" 7164 "Invalid" 7163 "Invalid" 7162 "Invalid" 7161 "Invalid" 7160 "Invalid" 7159 "Invalid" 7158 "Invalid" 7157 "Invalid" 7156 "Invalid" 7155 "Invalid" 7154 "Invalid" 7153 "Invalid" 7152 "Invalid" 7151 "Invalid" 7150 "Invalid" 7149 "Invalid" 7148 "Invalid" 7147 "Invalid" 7146 "Invalid" 7145 "Invalid" 7144 "Invalid" 7143 "Invalid" 7142 "Invalid" 7141 "Invalid" 7140 "Invalid" 7139 "Invalid" 7138 "Invalid" 7137 "Invalid" 7136 "Invalid" 7135 "Invalid" 7134 "Invalid" 7133 "Invalid" 7132 "Invalid" 7131 "Invalid" 7130 "Invalid" 7129 "Invalid" 7128 "Invalid" 7127 "Invalid" 7126 "Invalid" 7125 "Invalid" 7124 "Invalid" 7123 "Invalid" 7122 "Invalid" 7121 "Invalid" 7120 "Invalid" 7119 "Invalid" 7118 "Invalid" 7117 "Invalid" 7116 "Invalid" 7115 "Invalid" 7114 "Invalid" 7113 "Invalid" 7112 "Invalid" 7111 "Invalid" 7110 "Invalid" 7109 "Invalid" 7108 "Invalid" 7107 "Invalid" 7106 "Invalid" 7105 "Invalid" 7104 "Invalid" 7103 "Invalid" 7102 "Invalid" 7101 "Invalid" 7100 "Invalid" 7099 "Invalid" 7098 "Invalid" 7097 "Invalid" 7096 "Invalid" 7095 "Invalid" 7094 "Invalid" 7093 "Invalid" 7092 "Invalid" 7091 "Invalid" 7090 "Invalid" 7089 "Invalid" 7088 "Invalid" 7087 "Invalid" 7086 "Invalid" 7085 "Invalid" 7084 "Invalid" 7083 "Invalid" 7082 "Invalid" 7081 "Invalid" 7080 "Invalid" 7079 "Invalid" 7078 "Invalid" 7077 "Invalid" 7076 "Invalid" 7075 "Invalid" 7074 "Invalid" 7073 "Invalid" 7072 "Invalid" 7071 "Invalid" 7070 "Invalid" 7069 "Invalid" 7068 "Invalid" 7067 "Invalid" 7066 "Invalid" 7065 "Invalid" 7064 "Invalid" 7063 "Invalid" 7062 "Invalid" 7061 "Invalid" 7060 "Invalid" 7059 "Invalid" 7058 "Invalid" 7057 "Invalid" 7056 "Invalid" 7055 "Invalid" 7054 "Invalid" 7053 "Invalid" 7052 "Invalid" 7051 "Invalid" 7050 "Invalid" 7049 "Invalid" 7048 "Invalid" 7047 "Invalid" 7046 "Invalid" 7045 "Invalid" 7044 "Invalid" 7043 "Invalid" 7042 "Invalid" 7041 "Invalid" 7040 "Invalid" 7039 "Invalid" 7038 "Invalid" 7037 "Invalid" 7036 "Invalid" 7035 "Invalid" 7034 "Invalid" 7033 "Invalid" 7032 "Invalid" 7031 "Invalid" 7030 "Invalid" 7029 "Invalid" 7028 "Invalid" 7027 "Invalid" 7026 "Invalid" 7025 "Invalid" 7024 "Invalid" 7023 "Invalid" 7022 "Invalid" 7021 "Invalid" 7020 "Invalid" 7019 "Invalid" 7018 "Invalid" 7017 "Invalid" 7016 "Invalid" 7015 "Invalid" 7014 "Invalid" 7013 "Invalid" 7012 "Invalid" 7011 "Invalid" 7010 "Invalid" 7009 "Invalid" 7008 "Invalid" 7007 "Invalid" 7006 "Invalid" 7005 "Invalid" 7004 "Invalid" 7003 "Invalid" 7002 "Invalid" 7001 "Invalid" 7000 "Invalid" 6999 "Invalid" 6998 "Invalid" 6997 "Invalid" 6996 "Invalid" 6995 "Invalid" 6994 "Invalid" 6993 "Invalid" 6992 "Invalid" 6991 "Invalid" 6990 "Invalid" 6989 "Invalid" 6988 "Invalid" 6987 "Invalid" 6986 "Invalid" 6985 "Invalid" 6984 "Invalid" 6983 "Invalid" 6982 "Invalid" 6981 "Invalid" 6980 "Invalid" 6979 "Invalid" 6978 "Invalid" 6977 "Invalid" 6976 "Invalid" 6975 "Invalid" 6974 "Invalid" 6973 "Invalid" 6972 "Invalid" 6971 "Invalid" 6970 "Invalid" 6969 "Invalid" 6968 "Invalid" 6967 "Invalid" 6966 "Invalid" 6965 "Invalid" 6964 "Invalid" 6963 "Invalid" 6962 "Invalid" 6961 "Invalid" 6960 "Invalid" 6959 "Invalid" 6958 "Invalid" 6957 "Invalid" 6956 "Invalid" 6955 "Invalid" 6954 "Invalid" 6953 "Invalid" 6952 "Invalid" 6951 "Invalid" 6950 "Invalid" 6949 "Invalid" 6948 "Invalid" 6947 "Invalid" 6946 "Invalid" 6945 "Invalid" 6944 "Invalid" 6943 "Invalid" 6942 "Invalid" 6941 "Invalid" 6940 "Invalid" 6939 "Invalid" 6938 "Invalid" 6937 "Invalid" 6936 "Invalid" 6935 "Invalid" 6934 "Invalid" 6933 "Invalid" 6932 "Invalid" 6931 "Invalid" 6930 "Invalid" 6929 "Invalid" 6928 "Invalid" 6927 "Invalid" 6926 "Invalid" 6925 "Invalid" 6924 "Invalid" 6923 "Invalid" 6922 "Invalid" 6921 "Invalid" 6920 "Invalid" 6919 "Invalid" 6918 "Invalid" 6917 "Invalid" 6916 "Invalid" 6915 "Invalid" 6914 "Invalid" 6913 "Invalid" 6912 "Invalid" 6911 "Invalid" 6910 "Invalid" 6909 "Invalid" 6908 "Invalid" 6907 "Invalid" 6906 "Invalid" 6905 "Invalid" 6904 "Invalid" 6903 "Invalid" 6902 "Invalid" 6901 "Invalid" 6900 "Invalid" 6899 "Invalid" 6898 "Invalid" 6897 "Invalid" 6896 "Invalid" 6895 "Invalid" 6894 "Invalid" 6893 "Invalid" 6892 "Invalid" 6891 "Invalid" 6890 "Invalid" 6889 "Invalid" 6888 "Invalid" 6887 "Invalid" 6886 "Invalid" 6885 "Invalid" 6884 "Invalid" 6883 "Invalid" 6882 "Invalid" 6881 "Invalid" 6880 "Invalid" 6879 "Invalid" 6878 "Invalid" 6877 "Invalid" 6876 "Invalid" 6875 "Invalid" 6874 "Invalid" 6873 "Invalid" 6872 "Invalid" 6871 "Invalid" 6870 "Invalid" 6869 "Invalid" 6868 "Invalid" 6867 "Invalid" 6866 "Invalid" 6865 "Invalid" 6864 "Invalid" 6863 "Invalid" 6862 "Invalid" 6861 "Invalid" 6860 "Invalid" 6859 "Invalid" 6858 "Invalid" 6857 "Invalid" 6856 "Invalid" 6855 "Invalid" 6854 "Invalid" 6853 "Invalid" 6852 "Invalid" 6851 "Invalid" 6850 "Invalid" 6849 "Invalid" 6848 "Invalid" 6847 "Invalid" 6846 "Invalid" 6845 "Invalid" 6844 "Invalid" 6843 "Invalid" 6842 "Invalid" 6841 "Invalid" 6840 "Invalid" 6839 "Invalid" 6838 "Invalid" 6837 "Invalid" 6836 "Invalid" 6835 "Invalid" 6834 "Invalid" 6833 "Invalid" 6832 "Invalid" 6831 "Invalid" 6830 "Invalid" 6829 "Invalid" 6828 "Invalid" 6827 "Invalid" 6826 "Invalid" 6825 "Invalid" 6824 "Invalid" 6823 "Invalid" 6822 "Invalid" 6821 "Invalid" 6820 "Invalid" 6819 "Invalid" 6818 "Invalid" 6817 "Invalid" 6816 "Invalid" 6815 "Invalid" 6814 "Invalid" 6813 "Invalid" 6812 "Invalid" 6811 "Invalid" 6810 "Invalid" 6809 "Invalid" 6808 "Invalid" 6807 "Invalid" 6806 "Invalid" 6805 "Invalid" 6804 "Invalid" 6803 "Invalid" 6802 "Invalid" 6801 "Invalid" 6800 "Invalid" 6799 "Invalid" 6798 "Invalid" 6797 "Invalid" 6796 "Invalid" 6795 "Invalid" 6794 "Invalid" 6793 "Invalid" 6792 "Invalid" 6791 "Invalid" 6790 "Invalid" 6789 "Invalid" 6788 "Invalid" 6787 "Invalid" 6786 "Invalid" 6785 "Invalid" 6784 "Invalid" 6783 "Invalid" 6782 "Invalid" 6781 "Invalid" 6780 "Invalid" 6779 "Invalid" 6778 "Invalid" 6777 "Invalid" 6776 "Invalid" 6775 "Invalid" 6774 "Invalid" 6773 "Invalid" 6772 "Invalid" 6771 "Invalid" 6770 "Invalid" 6769 "Invalid" 6768 "Invalid" 6767 "Invalid" 6766 "Invalid" 6765 "Invalid" 6764 "Invalid" 6763 "Invalid" 6762 "Invalid" 6761 "Invalid" 6760 "Invalid" 6759 "Invalid" 6758 "Invalid" 6757 "Invalid" 6756 "Invalid" 6755 "Invalid" 6754 "Invalid" 6753 "Invalid" 6752 "Invalid" 6751 "Invalid" 6750 "Invalid" 6749 "Invalid" 6748 "Invalid" 6747 "Invalid" 6746 "Invalid" 6745 "Invalid" 6744 "Invalid" 6743 "Invalid" 6742 "Invalid" 6741 "Invalid" 6740 "Invalid" 6739 "Invalid" 6738 "Invalid" 6737 "Invalid" 6736 "Invalid" 6735 "Invalid" 6734 "Invalid" 6733 "Invalid" 6732 "Invalid" 6731 "Invalid" 6730 "Invalid" 6729 "Invalid" 6728 "Invalid" 6727 "Invalid" 6726 "Invalid" 6725 "Invalid" 6724 "Invalid" 6723 "Invalid" 6722 "Invalid" 6721 "Invalid" 6720 "Invalid" 6719 "Invalid" 6718 "Invalid" 6717 "Invalid" 6716 "Invalid" 6715 "Invalid" 6714 "Invalid" 6713 "Invalid" 6712 "Invalid" 6711 "Invalid" 6710 "Invalid" 6709 "Invalid" 6708 "Invalid" 6707 "Invalid" 6706 "Invalid" 6705 "Invalid" 6704 "Invalid" 6703 "Invalid" 6702 "Invalid" 6701 "Invalid" 6700 "Invalid" 6699 "Invalid" 6698 "Invalid" 6697 "Invalid" 6696 "Invalid" 6695 "Invalid" 6694 "Invalid" 6693 "Invalid" 6692 "Invalid" 6691 "Invalid" 6690 "Invalid" 6689 "Invalid" 6688 "Invalid" 6687 "Invalid" 6686 "Invalid" 6685 "Invalid" 6684 "Invalid" 6683 "Invalid" 6682 "Invalid" 6681 "Invalid" 6680 "Invalid" 6679 "Invalid" 6678 "Invalid" 6677 "Invalid" 6676 "Invalid" 6675 "Invalid" 6674 "Invalid" 6673 "Invalid" 6672 "Invalid" 6671 "Invalid" 6670 "Invalid" 6669 "Invalid" 6668 "Invalid" 6667 "Invalid" 6666 "Invalid" 6665 "Invalid" 6664 "Invalid" 6663 "Invalid" 6662 "Invalid" 6661 "Invalid" 6660 "Invalid" 6659 "Invalid" 6658 "Invalid" 6657 "Invalid" 6656 "Invalid" 6655 "Invalid" 6654 "Invalid" 6653 "Invalid" 6652 "Invalid" 6651 "Invalid" 6650 "Invalid" 6649 "Invalid" 6648 "Invalid" 6647 "Invalid" 6646 "Invalid" 6645 "Invalid" 6644 "Invalid" 6643 "Invalid" 6642 "Invalid" 6641 "Invalid" 6640 "Invalid" 6639 "Invalid" 6638 "Invalid" 6637 "Invalid" 6636 "Invalid" 6635 "Invalid" 6634 "Invalid" 6633 "Invalid" 6632 "Invalid" 6631 "Invalid" 6630 "Invalid" 6629 "Invalid" 6628 "Invalid" 6627 "Invalid" 6626 "Invalid" 6625 "Invalid" 6624 "Invalid" 6623 "Invalid" 6622 "Invalid" 6621 "Invalid" 6620 "Invalid" 6619 "Invalid" 6618 "Invalid" 6617 "Invalid" 6616 "Invalid" 6615 "Invalid" 6614 "Invalid" 6613 "Invalid" 6612 "Invalid" 6611 "Invalid" 6610 "Invalid" 6609 "Invalid" 6608 "Invalid" 6607 "Invalid" 6606 "Invalid" 6605 "Invalid" 6604 "Invalid" 6603 "Invalid" 6602 "Invalid" 6601 "Invalid" 6600 "Invalid" 6599 "Invalid" 6598 "Invalid" 6597 "Invalid" 6596 "Invalid" 6595 "Invalid" 6594 "Invalid" 6593 "Invalid" 6592 "Invalid" 6591 "Invalid" 6590 "Invalid" 6589 "Invalid" 6588 "Invalid" 6587 "Invalid" 6586 "Invalid" 6585 "Invalid" 6584 "Invalid" 6583 "Invalid" 6582 "Invalid" 6581 "Invalid" 6580 "Invalid" 6579 "Invalid" 6578 "Invalid" 6577 "Invalid" 6576 "Invalid" 6575 "Invalid" 6574 "Invalid" 6573 "Invalid" 6572 "Invalid" 6571 "Invalid" 6570 "Invalid" 6569 "Invalid" 6568 "Invalid" 6567 "Invalid" 6566 "Invalid" 6565 "Invalid" 6564 "Invalid" 6563 "Invalid" 6562 "Invalid" 6561 "Invalid" 6560 "Invalid" 6559 "Invalid" 6558 "Invalid" 6557 "Invalid" 6556 "Invalid" 6555 "Invalid" 6554 "Invalid" 6553 "Invalid" 6552 "Invalid" 6551 "Invalid" 6550 "Invalid" 6549 "Invalid" 6548 "Invalid" 6547 "Invalid" 6546 "Invalid" 6545 "Invalid" 6544 "Invalid" 6543 "Invalid" 6542 "Invalid" 6541 "Invalid" 6540 "Invalid" 6539 "Invalid" 6538 "Invalid" 6537 "Invalid" 6536 "Invalid" 6535 "Invalid" 6534 "Invalid" 6533 "Invalid" 6532 "Invalid" 6531 "Invalid" 6530 "Invalid" 6529 "Invalid" 6528 "Invalid" 6527 "Invalid" 6526 "Invalid" 6525 "Invalid" 6524 "Invalid" 6523 "Invalid" 6522 "Invalid" 6521 "Invalid" 6520 "Invalid" 6519 "Invalid" 6518 "Invalid" 6517 "Invalid" 6516 "Invalid" 6515 "Invalid" 6514 "Invalid" 6513 "Invalid" 6512 "Invalid" 6511 "Invalid" 6510 "Invalid" 6509 "Invalid" 6508 "Invalid" 6507 "Invalid" 6506 "Invalid" 6505 "Invalid" 6504 "Invalid" 6503 "Invalid" 6502 "Invalid" 6501 "Invalid" 6500 "Invalid" 6499 "Invalid" 6498 "Invalid" 6497 "Invalid" 6496 "Invalid" 6495 "Invalid" 6494 "Invalid" 6493 "Invalid" 6492 "Invalid" 6491 "Invalid" 6490 "Invalid" 6489 "Invalid" 6488 "Invalid" 6487 "Invalid" 6486 "Invalid" 6485 "Invalid" 6484 "Invalid" 6483 "Invalid" 6482 "Invalid" 6481 "Invalid" 6480 "Invalid" 6479 "Invalid" 6478 "Invalid" 6477 "Invalid" 6476 "Invalid" 6475 "Invalid" 6474 "Invalid" 6473 "Invalid" 6472 "Invalid" 6471 "Invalid" 6470 "Invalid" 6469 "Invalid" 6468 "Invalid" 6467 "Invalid" 6466 "Invalid" 6465 "Invalid" 6464 "Invalid" 6463 "Invalid" 6462 "Invalid" 6461 "Invalid" 6460 "Invalid" 6459 "Invalid" 6458 "Invalid" 6457 "Invalid" 6456 "Invalid" 6455 "Invalid" 6454 "Invalid" 6453 "Invalid" 6452 "Invalid" 6451 "Invalid" 6450 "Invalid" 6449 "Invalid" 6448 "Invalid" 6447 "Invalid" 6446 "Invalid" 6445 "Invalid" 6444 "Invalid" 6443 "Invalid" 6442 "Invalid" 6441 "Invalid" 6440 "Invalid" 6439 "Invalid" 6438 "Invalid" 6437 "Invalid" 6436 "Invalid" 6435 "Invalid" 6434 "Invalid" 6433 "Invalid" 6432 "Invalid" 6431 "Invalid" 6430 "Invalid" 6429 "Invalid" 6428 "Invalid" 6427 "Invalid" 6426 "Invalid" 6425 "Invalid" 6424 "Invalid" 6423 "Invalid" 6422 "Invalid" 6421 "Invalid" 6420 "Invalid" 6419 "Invalid" 6418 "Invalid" 6417 "Invalid" 6416 "Invalid" 6415 "Invalid" 6414 "Invalid" 6413 "Invalid" 6412 "Invalid" 6411 "Invalid" 6410 "Invalid" 6409 "Invalid" 6408 "Invalid" 6407 "Invalid" 6406 "Invalid" 6405 "Invalid" 6404 "Invalid" 6403 "Invalid" 6402 "Invalid" 6401 "Invalid" 6400 "Invalid" 6399 "Invalid" 6398 "Invalid" 6397 "Invalid" 6396 "Invalid" 6395 "Invalid" 6394 "Invalid" 6393 "Invalid" 6392 "Invalid" 6391 "Invalid" 6390 "Invalid" 6389 "Invalid" 6388 "Invalid" 6387 "Invalid" 6386 "Invalid" 6385 "Invalid" 6384 "Invalid" 6383 "Invalid" 6382 "Invalid" 6381 "Invalid" 6380 "Invalid" 6379 "Invalid" 6378 "Invalid" 6377 "Invalid" 6376 "Invalid" 6375 "Invalid" 6374 "Invalid" 6373 "Invalid" 6372 "Invalid" 6371 "Invalid" 6370 "Invalid" 6369 "Invalid" 6368 "Invalid" 6367 "Invalid" 6366 "Invalid" 6365 "Invalid" 6364 "Invalid" 6363 "Invalid" 6362 "Invalid" 6361 "Invalid" 6360 "Invalid" 6359 "Invalid" 6358 "Invalid" 6357 "Invalid" 6356 "Invalid" 6355 "Invalid" 6354 "Invalid" 6353 "Invalid" 6352 "Invalid" 6351 "Invalid" 6350 "Invalid" 6349 "Invalid" 6348 "Invalid" 6347 "Invalid" 6346 "Invalid" 6345 "Invalid" 6344 "Invalid" 6343 "Invalid" 6342 "Invalid" 6341 "Invalid" 6340 "Invalid" 6339 "Invalid" 6338 "Invalid" 6337 "Invalid" 6336 "Invalid" 6335 "Invalid" 6334 "Invalid" 6333 "Invalid" 6332 "Invalid" 6331 "Invalid" 6330 "Invalid" 6329 "Invalid" 6328 "Invalid" 6327 "Invalid" 6326 "Invalid" 6325 "Invalid" 6324 "Invalid" 6323 "Invalid" 6322 "Invalid" 6321 "Invalid" 6320 "Invalid" 6319 "Invalid" 6318 "Invalid" 6317 "Invalid" 6316 "Invalid" 6315 "Invalid" 6314 "Invalid" 6313 "Invalid" 6312 "Invalid" 6311 "Invalid" 6310 "Invalid" 6309 "Invalid" 6308 "Invalid" 6307 "Invalid" 6306 "Invalid" 6305 "Invalid" 6304 "Invalid" 6303 "Invalid" 6302 "Invalid" 6301 "Invalid" 6300 "Invalid" 6299 "Invalid" 6298 "Invalid" 6297 "Invalid" 6296 "Invalid" 6295 "Invalid" 6294 "Invalid" 6293 "Invalid" 6292 "Invalid" 6291 "Invalid" 6290 "Invalid" 6289 "Invalid" 6288 "Invalid" 6287 "Invalid" 6286 "Invalid" 6285 "Invalid" 6284 "Invalid" 6283 "Invalid" 6282 "Invalid" 6281 "Invalid" 6280 "Invalid" 6279 "Invalid" 6278 "Invalid" 6277 "Invalid" 6276 "Invalid" 6275 "Invalid" 6274 "Invalid" 6273 "Invalid" 6272 "Invalid" 6271 "Invalid" 6270 "Invalid" 6269 "Invalid" 6268 "Invalid" 6267 "Invalid" 6266 "Invalid" 6265 "Invalid" 6264 "Invalid" 6263 "Invalid" 6262 "Invalid" 6261 "Invalid" 6260 "Invalid" 6259 "Invalid" 6258 "Invalid" 6257 "Invalid" 6256 "Invalid" 6255 "Invalid" 6254 "Invalid" 6253 "Invalid" 6252 "Invalid" 6251 "Invalid" 6250 "Invalid" 6249 "Invalid" 6248 "Invalid" 6247 "Invalid" 6246 "Invalid" 6245 "Invalid" 6244 "Invalid" 6243 "Invalid" 6242 "Invalid" 6241 "Invalid" 6240 "Invalid" 6239 "Invalid" 6238 "Invalid" 6237 "Invalid" 6236 "Invalid" 6235 "Invalid" 6234 "Invalid" 6233 "Invalid" 6232 "Invalid" 6231 "Invalid" 6230 "Invalid" 6229 "Invalid" 6228 "Invalid" 6227 "Invalid" 6226 "Invalid" 6225 "Invalid" 6224 "Invalid" 6223 "Invalid" 6222 "Invalid" 6221 "Invalid" 6220 "Invalid" 6219 "Invalid" 6218 "Invalid" 6217 "Invalid" 6216 "Invalid" 6215 "Invalid" 6214 "Invalid" 6213 "Invalid" 6212 "Invalid" 6211 "Invalid" 6210 "Invalid" 6209 "Invalid" 6208 "Invalid" 6207 "Invalid" 6206 "Invalid" 6205 "Invalid" 6204 "Invalid" 6203 "Invalid" 6202 "Invalid" 6201 "Invalid" 6200 "Invalid" 6199 "Invalid" 6198 "Invalid" 6197 "Invalid" 6196 "Invalid" 6195 "Invalid" 6194 "Invalid" 6193 "Invalid" 6192 "Invalid" 6191 "Invalid" 6190 "Invalid" 6189 "Invalid" 6188 "Invalid" 6187 "Invalid" 6186 "Invalid" 6185 "Invalid" 6184 "Invalid" 6183 "Invalid" 6182 "Invalid" 6181 "Invalid" 6180 "Invalid" 6179 "Invalid" 6178 "Invalid" 6177 "Invalid" 6176 "Invalid" 6175 "Invalid" 6174 "Invalid" 6173 "Invalid" 6172 "Invalid" 6171 "Invalid" 6170 "Invalid" 6169 "Invalid" 6168 "Invalid" 6167 "Invalid" 6166 "Invalid" 6165 "Invalid" 6164 "Invalid" 6163 "Invalid" 6162 "Invalid" 6161 "Invalid" 6160 "Invalid" 6159 "Invalid" 6158 "Invalid" 6157 "Invalid" 6156 "Invalid" 6155 "Invalid" 6154 "Invalid" 6153 "Invalid" 6152 "Invalid" 6151 "Invalid" 6150 "Invalid" 6149 "Invalid" 6148 "Invalid" 6147 "Invalid" 6146 "Invalid" 6145 "Invalid" 6144 "Invalid" 6143 "Invalid" 6142 "Invalid" 6141 "Invalid" 6140 "Invalid" 6139 "Invalid" 6138 "Invalid" 6137 "Invalid" 6136 "Invalid" 6135 "Invalid" 6134 "Invalid" 6133 "Invalid" 6132 "Invalid" 6131 "Invalid" 6130 "Invalid" 6129 "Invalid" 6128 "Invalid" 6127 "Invalid" 6126 "Invalid" 6125 "Invalid" 6124 "Invalid" 6123 "Invalid" 6122 "Invalid" 6121 "Invalid" 6120 "Invalid" 6119 "Invalid" 6118 "Invalid" 6117 "Invalid" 6116 "Invalid" 6115 "Invalid" 6114 "Invalid" 6113 "Invalid" 6112 "Invalid" 6111 "Invalid" 6110 "Invalid" 6109 "Invalid" 6108 "Invalid" 6107 "Invalid" 6106 "Invalid" 6105 "Invalid" 6104 "Invalid" 6103 "Invalid" 6102 "Invalid" 6101 "Invalid" 6100 "Invalid" 6099 "Invalid" 6098 "Invalid" 6097 "Invalid" 6096 "Invalid" 6095 "Invalid" 6094 "Invalid" 6093 "Invalid" 6092 "Invalid" 6091 "Invalid" 6090 "Invalid" 6089 "Invalid" 6088 "Invalid" 6087 "Invalid" 6086 "Invalid" 6085 "Invalid" 6084 "Invalid" 6083 "Invalid" 6082 "Invalid" 6081 "Invalid" 6080 "Invalid" 6079 "Invalid" 6078 "Invalid" 6077 "Invalid" 6076 "Invalid" 6075 "Invalid" 6074 "Invalid" 6073 "Invalid" 6072 "Invalid" 6071 "Invalid" 6070 "Invalid" 6069 "Invalid" 6068 "Invalid" 6067 "Invalid" 6066 "Invalid" 6065 "Invalid" 6064 "Invalid" 6063 "Invalid" 6062 "Invalid" 6061 "Invalid" 6060 "Invalid" 6059 "Invalid" 6058 "Invalid" 6057 "Invalid" 6056 "Invalid" 6055 "Invalid" 6054 "Invalid" 6053 "Invalid" 6052 "Invalid" 6051 "Invalid" 6050 "Invalid" 6049 "Invalid" 6048 "Invalid" 6047 "Invalid" 6046 "Invalid" 6045 "Invalid" 6044 "Invalid" 6043 "Invalid" 6042 "Invalid" 6041 "Invalid" 6040 "Invalid" 6039 "Invalid" 6038 "Invalid" 6037 "Invalid" 6036 "Invalid" 6035 "Invalid" 6034 "Invalid" 6033 "Invalid" 6032 "Invalid" 6031 "Invalid" 6030 "Invalid" 6029 "Invalid" 6028 "Invalid" 6027 "Invalid" 6026 "Invalid" 6025 "Invalid" 6024 "Invalid" 6023 "Invalid" 6022 "Invalid" 6021 "Invalid" 6020 "Invalid" 6019 "Invalid" 6018 "Invalid" 6017 "Invalid" 6016 "Invalid" 6015 "Invalid" 6014 "Invalid" 6013 "Invalid" 6012 "Invalid" 6011 "Invalid" 6010 "Invalid" 6009 "Invalid" 6008 "Invalid" 6007 "Invalid" 6006 "Invalid" 6005 "Invalid" 6004 "Invalid" 6003 "Invalid" 6002 "Invalid" 6001 "Invalid" 6000 "Invalid" 5999 "Invalid" 5998 "Invalid" 5997 "Invalid" 5996 "Invalid" 5995 "Invalid" 5994 "Invalid" 5993 "Invalid" 5992 "Invalid" 5991 "Invalid" 5990 "Invalid" 5989 "Invalid" 5988 "Invalid" 5987 "Invalid" 5986 "Invalid" 5985 "Invalid" 5984 "Invalid" 5983 "Invalid" 5982 "Invalid" 5981 "Invalid" 5980 "Invalid" 5979 "Invalid" 5978 "Invalid" 5977 "Invalid" 5976 "Invalid" 5975 "Invalid" 5974 "Invalid" 5973 "Invalid" 5972 "Invalid" 5971 "Invalid" 5970 "Invalid" 5969 "Invalid" 5968 "Invalid" 5967 "Invalid" 5966 "Invalid" 5965 "Invalid" 5964 "Invalid" 5963 "Invalid" 5962 "Invalid" 5961 "Invalid" 5960 "Invalid" 5959 "Invalid" 5958 "Invalid" 5957 "Invalid" 5956 "Invalid" 5955 "Invalid" 5954 "Invalid" 5953 "Invalid" 5952 "Invalid" 5951 "Invalid" 5950 "Invalid" 5949 "Invalid" 5948 "Invalid" 5947 "Invalid" 5946 "Invalid" 5945 "Invalid" 5944 "Invalid" 5943 "Invalid" 5942 "Invalid" 5941 "Invalid" 5940 "Invalid" 5939 "Invalid" 5938 "Invalid" 5937 "Invalid" 5936 "Invalid" 5935 "Invalid" 5934 "Invalid" 5933 "Invalid" 5932 "Invalid" 5931 "Invalid" 5930 "Invalid" 5929 "Invalid" 5928 "Invalid" 5927 "Invalid" 5926 "Invalid" 5925 "Invalid" 5924 "Invalid" 5923 "Invalid" 5922 "Invalid" 5921 "Invalid" 5920 "Invalid" 5919 "Invalid" 5918 "Invalid" 5917 "Invalid" 5916 "Invalid" 5915 "Invalid" 5914 "Invalid" 5913 "Invalid" 5912 "Invalid" 5911 "Invalid" 5910 "Invalid" 5909 "Invalid" 5908 "Invalid" 5907 "Invalid" 5906 "Invalid" 5905 "Invalid" 5904 "Invalid" 5903 "Invalid" 5902 "Invalid" 5901 "Invalid" 5900 "Invalid" 5899 "Invalid" 5898 "Invalid" 5897 "Invalid" 5896 "Invalid" 5895 "Invalid" 5894 "Invalid" 5893 "Invalid" 5892 "Invalid" 5891 "Invalid" 5890 "Invalid" 5889 "Invalid" 5888 "Invalid" 5887 "Invalid" 5886 "Invalid" 5885 "Invalid" 5884 "Invalid" 5883 "Invalid" 5882 "Invalid" 5881 "Invalid" 5880 "Invalid" 5879 "Invalid" 5878 "Invalid" 5877 "Invalid" 5876 "Invalid" 5875 "Invalid" 5874 "Invalid" 5873 "Invalid" 5872 "Invalid" 5871 "Invalid" 5870 "Invalid" 5869 "Invalid" 5868 "Invalid" 5867 "Invalid" 5866 "Invalid" 5865 "Invalid" 5864 "Invalid" 5863 "Invalid" 5862 "Invalid" 5861 "Invalid" 5860 "Invalid" 5859 "Invalid" 5858 "Invalid" 5857 "Invalid" 5856 "Invalid" 5855 "Invalid" 5854 "Invalid" 5853 "Invalid" 5852 "Invalid" 5851 "Invalid" 5850 "Invalid" 5849 "Invalid" 5848 "Invalid" 5847 "Invalid" 5846 "Invalid" 5845 "Invalid" 5844 "Invalid" 5843 "Invalid" 5842 "Invalid" 5841 "Invalid" 5840 "Invalid" 5839 "Invalid" 5838 "Invalid" 5837 "Invalid" 5836 "Invalid" 5835 "Invalid" 5834 "Invalid" 5833 "Invalid" 5832 "Invalid" 5831 "Invalid" 5830 "Invalid" 5829 "Invalid" 5828 "Invalid" 5827 "Invalid" 5826 "Invalid" 5825 "Invalid" 5824 "Invalid" 5823 "Invalid" 5822 "Invalid" 5821 "Invalid" 5820 "Invalid" 5819 "Invalid" 5818 "Invalid" 5817 "Invalid" 5816 "Invalid" 5815 "Invalid" 5814 "Invalid" 5813 "Invalid" 5812 "Invalid" 5811 "Invalid" 5810 "Invalid" 5809 "Invalid" 5808 "Invalid" 5807 "Invalid" 5806 "Invalid" 5805 "Invalid" 5804 "Invalid" 5803 "Invalid" 5802 "Invalid" 5801 "Invalid" 5800 "Invalid" 5799 "Invalid" 5798 "Invalid" 5797 "Invalid" 5796 "Invalid" 5795 "Invalid" 5794 "Invalid" 5793 "Invalid" 5792 "Invalid" 5791 "Invalid" 5790 "Invalid" 5789 "Invalid" 5788 "Invalid" 5787 "Invalid" 5786 "Invalid" 5785 "Invalid" 5784 "Invalid" 5783 "Invalid" 5782 "Invalid" 5781 "Invalid" 5780 "Invalid" 5779 "Invalid" 5778 "Invalid" 5777 "Invalid" 5776 "Invalid" 5775 "Invalid" 5774 "Invalid" 5773 "Invalid" 5772 "Invalid" 5771 "Invalid" 5770 "Invalid" 5769 "Invalid" 5768 "Invalid" 5767 "Invalid" 5766 "Invalid" 5765 "Invalid" 5764 "Invalid" 5763 "Invalid" 5762 "Invalid" 5761 "Invalid" 5760 "Invalid" 5759 "Invalid" 5758 "Invalid" 5757 "Invalid" 5756 "Invalid" 5755 "Invalid" 5754 "Invalid" 5753 "Invalid" 5752 "Invalid" 5751 "Invalid" 5750 "Invalid" 5749 "Invalid" 5748 "Invalid" 5747 "Invalid" 5746 "Invalid" 5745 "Invalid" 5744 "Invalid" 5743 "Invalid" 5742 "Invalid" 5741 "Invalid" 5740 "Invalid" 5739 "Invalid" 5738 "Invalid" 5737 "Invalid" 5736 "Invalid" 5735 "Invalid" 5734 "Invalid" 5733 "Invalid" 5732 "Invalid" 5731 "Invalid" 5730 "Invalid" 5729 "Invalid" 5728 "Invalid" 5727 "Invalid" 5726 "Invalid" 5725 "Invalid" 5724 "Invalid" 5723 "Invalid" 5722 "Invalid" 5721 "Invalid" 5720 "Invalid" 5719 "Invalid" 5718 "Invalid" 5717 "Invalid" 5716 "Invalid" 5715 "Invalid" 5714 "Invalid" 5713 "Invalid" 5712 "Invalid" 5711 "Invalid" 5710 "Invalid" 5709 "Invalid" 5708 "Invalid" 5707 "Invalid" 5706 "Invalid" 5705 "Invalid" 5704 "Invalid" 5703 "Invalid" 5702 "Invalid" 5701 "Invalid" 5700 "Invalid" 5699 "Invalid" 5698 "Invalid" 5697 "Invalid" 5696 "Invalid" 5695 "Invalid" 5694 "Invalid" 5693 "Invalid" 5692 "Invalid" 5691 "Invalid" 5690 "Invalid" 5689 "Invalid" 5688 "Invalid" 5687 "Invalid" 5686 "Invalid" 5685 "Invalid" 5684 "Invalid" 5683 "Invalid" 5682 "Invalid" 5681 "Invalid" 5680 "Invalid" 5679 "Invalid" 5678 "Invalid" 5677 "Invalid" 5676 "Invalid" 5675 "Invalid" 5674 "Invalid" 5673 "Invalid" 5672 "Invalid" 5671 "Invalid" 5670 "Invalid" 5669 "Invalid" 5668 "Invalid" 5667 "Invalid" 5666 "Invalid" 5665 "Invalid" 5664 "Invalid" 5663 "Invalid" 5662 "Invalid" 5661 "Invalid" 5660 "Invalid" 5659 "Invalid" 5658 "Invalid" 5657 "Invalid" 5656 "Invalid" 5655 "Invalid" 5654 "Invalid" 5653 "Invalid" 5652 "Invalid" 5651 "Invalid" 5650 "Invalid" 5649 "Invalid" 5648 "Invalid" 5647 "Invalid" 5646 "Invalid" 5645 "Invalid" 5644 "Invalid" 5643 "Invalid" 5642 "Invalid" 5641 "Invalid" 5640 "Invalid" 5639 "Invalid" 5638 "Invalid" 5637 "Invalid" 5636 "Invalid" 5635 "Invalid" 5634 "Invalid" 5633 "Invalid" 5632 "Invalid" 5631 "Invalid" 5630 "Invalid" 5629 "Invalid" 5628 "Invalid" 5627 "Invalid" 5626 "Invalid" 5625 "Invalid" 5624 "Invalid" 5623 "Invalid" 5622 "Invalid" 5621 "Invalid" 5620 "Invalid" 5619 "Invalid" 5618 "Invalid" 5617 "Invalid" 5616 "Invalid" 5615 "Invalid" 5614 "Invalid" 5613 "Invalid" 5612 "Invalid" 5611 "Invalid" 5610 "Invalid" 5609 "Invalid" 5608 "Invalid" 5607 "Invalid" 5606 "Invalid" 5605 "Invalid" 5604 "Invalid" 5603 "Invalid" 5602 "Invalid" 5601 "Invalid" 5600 "Invalid" 5599 "Invalid" 5598 "Invalid" 5597 "Invalid" 5596 "Invalid" 5595 "Invalid" 5594 "Invalid" 5593 "Invalid" 5592 "Invalid" 5591 "Invalid" 5590 "Invalid" 5589 "Invalid" 5588 "Invalid" 5587 "Invalid" 5586 "Invalid" 5585 "Invalid" 5584 "Invalid" 5583 "Invalid" 5582 "Invalid" 5581 "Invalid" 5580 "Invalid" 5579 "Invalid" 5578 "Invalid" 5577 "Invalid" 5576 "Invalid" 5575 "Invalid" 5574 "Invalid" 5573 "Invalid" 5572 "Invalid" 5571 "Invalid" 5570 "Invalid" 5569 "Invalid" 5568 "Invalid" 5567 "Invalid" 5566 "Invalid" 5565 "Invalid" 5564 "Invalid" 5563 "Invalid" 5562 "Invalid" 5561 "Invalid" 5560 "Invalid" 5559 "Invalid" 5558 "Invalid" 5557 "Invalid" 5556 "Invalid" 5555 "Invalid" 5554 "Invalid" 5553 "Invalid" 5552 "Invalid" 5551 "Invalid" 5550 "Invalid" 5549 "Invalid" 5548 "Invalid" 5547 "Invalid" 5546 "Invalid" 5545 "Invalid" 5544 "Invalid" 5543 "Invalid" 5542 "Invalid" 5541 "Invalid" 5540 "Invalid" 5539 "Invalid" 5538 "Invalid" 5537 "Invalid" 5536 "Invalid" 5535 "Invalid" 5534 "Invalid" 5533 "Invalid" 5532 "Invalid" 5531 "Invalid" 5530 "Invalid" 5529 "Invalid" 5528 "Invalid" 5527 "Invalid" 5526 "Invalid" 5525 "Invalid" 5524 "Invalid" 5523 "Invalid" 5522 "Invalid" 5521 "Invalid" 5520 "Invalid" 5519 "Invalid" 5518 "Invalid" 5517 "Invalid" 5516 "Invalid" 5515 "Invalid" 5514 "Invalid" 5513 "Invalid" 5512 "Invalid" 5511 "Invalid" 5510 "Invalid" 5509 "Invalid" 5508 "Invalid" 5507 "Invalid" 5506 "Invalid" 5505 "Invalid" 5504 "Invalid" 5503 "Invalid" 5502 "Invalid" 5501 "Invalid" 5500 "Invalid" 5499 "Invalid" 5498 "Invalid" 5497 "Invalid" 5496 "Invalid" 5495 "Invalid" 5494 "Invalid" 5493 "Invalid" 5492 "Invalid" 5491 "Invalid" 5490 "Invalid" 5489 "Invalid" 5488 "Invalid" 5487 "Invalid" 5486 "Invalid" 5485 "Invalid" 5484 "Invalid" 5483 "Invalid" 5482 "Invalid" 5481 "Invalid" 5480 "Invalid" 5479 "Invalid" 5478 "Invalid" 5477 "Invalid" 5476 "Invalid" 5475 "Invalid" 5474 "Invalid" 5473 "Invalid" 5472 "Invalid" 5471 "Invalid" 5470 "Invalid" 5469 "Invalid" 5468 "Invalid" 5467 "Invalid" 5466 "Invalid" 5465 "Invalid" 5464 "Invalid" 5463 "Invalid" 5462 "Invalid" 5461 "Invalid" 5460 "Invalid" 5459 "Invalid" 5458 "Invalid" 5457 "Invalid" 5456 "Invalid" 5455 "Invalid" 5454 "Invalid" 5453 "Invalid" 5452 "Invalid" 5451 "Invalid" 5450 "Invalid" 5449 "Invalid" 5448 "Invalid" 5447 "Invalid" 5446 "Invalid" 5445 "Invalid" 5444 "Invalid" 5443 "Invalid" 5442 "Invalid" 5441 "Invalid" 5440 "Invalid" 5439 "Invalid" 5438 "Invalid" 5437 "Invalid" 5436 "Invalid" 5435 "Invalid" 5434 "Invalid" 5433 "Invalid" 5432 "Invalid" 5431 "Invalid" 5430 "Invalid" 5429 "Invalid" 5428 "Invalid" 5427 "Invalid" 5426 "Invalid" 5425 "Invalid" 5424 "Invalid" 5423 "Invalid" 5422 "Invalid" 5421 "Invalid" 5420 "Invalid" 5419 "Invalid" 5418 "Invalid" 5417 "Invalid" 5416 "Invalid" 5415 "Invalid" 5414 "Invalid" 5413 "Invalid" 5412 "Invalid" 5411 "Invalid" 5410 "Invalid" 5409 "Invalid" 5408 "Invalid" 5407 "Invalid" 5406 "Invalid" 5405 "Invalid" 5404 "Invalid" 5403 "Invalid" 5402 "Invalid" 5401 "Invalid" 5400 "Invalid" 5399 "Invalid" 5398 "Invalid" 5397 "Invalid" 5396 "Invalid" 5395 "Invalid" 5394 "Invalid" 5393 "Invalid" 5392 "Invalid" 5391 "Invalid" 5390 "Invalid" 5389 "Invalid" 5388 "Invalid" 5387 "Invalid" 5386 "Invalid" 5385 "Invalid" 5384 "Invalid" 5383 "Invalid" 5382 "Invalid" 5381 "Invalid" 5380 "Invalid" 5379 "Invalid" 5378 "Invalid" 5377 "Invalid" 5376 "Invalid" 5375 "Invalid" 5374 "Invalid" 5373 "Invalid" 5372 "Invalid" 5371 "Invalid" 5370 "Invalid" 5369 "Invalid" 5368 "Invalid" 5367 "Invalid" 5366 "Invalid" 5365 "Invalid" 5364 "Invalid" 5363 "Invalid" 5362 "Invalid" 5361 "Invalid" 5360 "Invalid" 5359 "Invalid" 5358 "Invalid" 5357 "Invalid" 5356 "Invalid" 5355 "Invalid" 5354 "Invalid" 5353 "Invalid" 5352 "Invalid" 5351 "Invalid" 5350 "Invalid" 5349 "Invalid" 5348 "Invalid" 5347 "Invalid" 5346 "Invalid" 5345 "Invalid" 5344 "Invalid" 5343 "Invalid" 5342 "Invalid" 5341 "Invalid" 5340 "Invalid" 5339 "Invalid" 5338 "Invalid" 5337 "Invalid" 5336 "Invalid" 5335 "Invalid" 5334 "Invalid" 5333 "Invalid" 5332 "Invalid" 5331 "Invalid" 5330 "Invalid" 5329 "Invalid" 5328 "Invalid" 5327 "Invalid" 5326 "Invalid" 5325 "Invalid" 5324 "Invalid" 5323 "Invalid" 5322 "Invalid" 5321 "Invalid" 5320 "Invalid" 5319 "Invalid" 5318 "Invalid" 5317 "Invalid" 5316 "Invalid" 5315 "Invalid" 5314 "Invalid" 5313 "Invalid" 5312 "Invalid" 5311 "Invalid" 5310 "Invalid" 5309 "Invalid" 5308 "Invalid" 5307 "Invalid" 5306 "Invalid" 5305 "Invalid" 5304 "Invalid" 5303 "Invalid" 5302 "Invalid" 5301 "Invalid" 5300 "Invalid" 5299 "Invalid" 5298 "Invalid" 5297 "Invalid" 5296 "Invalid" 5295 "Invalid" 5294 "Invalid" 5293 "Invalid" 5292 "Invalid" 5291 "Invalid" 5290 "Invalid" 5289 "Invalid" 5288 "Invalid" 5287 "Invalid" 5286 "Invalid" 5285 "Invalid" 5284 "Invalid" 5283 "Invalid" 5282 "Invalid" 5281 "Invalid" 5280 "Invalid" 5279 "Invalid" 5278 "Invalid" 5277 "Invalid" 5276 "Invalid" 5275 "Invalid" 5274 "Invalid" 5273 "Invalid" 5272 "Invalid" 5271 "Invalid" 5270 "Invalid" 5269 "Invalid" 5268 "Invalid" 5267 "Invalid" 5266 "Invalid" 5265 "Invalid" 5264 "Invalid" 5263 "Invalid" 5262 "Invalid" 5261 "Invalid" 5260 "Invalid" 5259 "Invalid" 5258 "Invalid" 5257 "Invalid" 5256 "Invalid" 5255 "Invalid" 5254 "Invalid" 5253 "Invalid" 5252 "Invalid" 5251 "Invalid" 5250 "Invalid" 5249 "Invalid" 5248 "Invalid" 5247 "Invalid" 5246 "Invalid" 5245 "Invalid" 5244 "Invalid" 5243 "Invalid" 5242 "Invalid" 5241 "Invalid" 5240 "Invalid" 5239 "Invalid" 5238 "Invalid" 5237 "Invalid" 5236 "Invalid" 5235 "Invalid" 5234 "Invalid" 5233 "Invalid" 5232 "Invalid" 5231 "Invalid" 5230 "Invalid" 5229 "Invalid" 5228 "Invalid" 5227 "Invalid" 5226 "Invalid" 5225 "Invalid" 5224 "Invalid" 5223 "Invalid" 5222 "Invalid" 5221 "Invalid" 5220 "Invalid" 5219 "Invalid" 5218 "Invalid" 5217 "Invalid" 5216 "Invalid" 5215 "Invalid" 5214 "Invalid" 5213 "Invalid" 5212 "Invalid" 5211 "Invalid" 5210 "Invalid" 5209 "Invalid" 5208 "Invalid" 5207 "Invalid" 5206 "Invalid" 5205 "Invalid" 5204 "Invalid" 5203 "Invalid" 5202 "Invalid" 5201 "Invalid" 5200 "Invalid" 5199 "Invalid" 5198 "Invalid" 5197 "Invalid" 5196 "Invalid" 5195 "Invalid" 5194 "Invalid" 5193 "Invalid" 5192 "Invalid" 5191 "Invalid" 5190 "Invalid" 5189 "Invalid" 5188 "Invalid" 5187 "Invalid" 5186 "Invalid" 5185 "Invalid" 5184 "Invalid" 5183 "Invalid" 5182 "Invalid" 5181 "Invalid" 5180 "Invalid" 5179 "Invalid" 5178 "Invalid" 5177 "Invalid" 5176 "Invalid" 5175 "Invalid" 5174 "Invalid" 5173 "Invalid" 5172 "Invalid" 5171 "Invalid" 5170 "Invalid" 5169 "Invalid" 5168 "Invalid" 5167 "Invalid" 5166 "Invalid" 5165 "Invalid" 5164 "Invalid" 5163 "Invalid" 5162 "Invalid" 5161 "Invalid" 5160 "Invalid" 5159 "Invalid" 5158 "Invalid" 5157 "Invalid" 5156 "Invalid" 5155 "Invalid" 5154 "Invalid" 5153 "Invalid" 5152 "Invalid" 5151 "Invalid" 5150 "Invalid" 5149 "Invalid" 5148 "Invalid" 5147 "Invalid" 5146 "Invalid" 5145 "Invalid" 5144 "Invalid" 5143 "Invalid" 5142 "Invalid" 5141 "Invalid" 5140 "Invalid" 5139 "Invalid" 5138 "Invalid" 5137 "Invalid" 5136 "Invalid" 5135 "Invalid" 5134 "Invalid" 5133 "Invalid" 5132 "Invalid" 5131 "Invalid" 5130 "Invalid" 5129 "Invalid" 5128 "Invalid" 5127 "Invalid" 5126 "Invalid" 5125 "Invalid" 5124 "Invalid" 5123 "Invalid" 5122 "Invalid" 5121 "Invalid" 5120 "Invalid" 5119 "Invalid" 5118 "Invalid" 5117 "Invalid" 5116 "Invalid" 5115 "Invalid" 5114 "Invalid" 5113 "Invalid" 5112 "Invalid" 5111 "Invalid" 5110 "Invalid" 5109 "Invalid" 5108 "Invalid" 5107 "Invalid" 5106 "Invalid" 5105 "Invalid" 5104 "Invalid" 5103 "Invalid" 5102 "Invalid" 5101 "Invalid" 5100 "Invalid" 5099 "Invalid" 5098 "Invalid" 5097 "Invalid" 5096 "Invalid" 5095 "Invalid" 5094 "Invalid" 5093 "Invalid" 5092 "Invalid" 5091 "Invalid" 5090 "Invalid" 5089 "Invalid" 5088 "Invalid" 5087 "Invalid" 5086 "Invalid" 5085 "Invalid" 5084 "Invalid" 5083 "Invalid" 5082 "Invalid" 5081 "Invalid" 5080 "Invalid" 5079 "Invalid" 5078 "Invalid" 5077 "Invalid" 5076 "Invalid" 5075 "Invalid" 5074 "Invalid" 5073 "Invalid" 5072 "Invalid" 5071 "Invalid" 5070 "Invalid" 5069 "Invalid" 5068 "Invalid" 5067 "Invalid" 5066 "Invalid" 5065 "Invalid" 5064 "Invalid" 5063 "Invalid" 5062 "Invalid" 5061 "Invalid" 5060 "Invalid" 5059 "Invalid" 5058 "Invalid" 5057 "Invalid" 5056 "Invalid" 5055 "Invalid" 5054 "Invalid" 5053 "Invalid" 5052 "Invalid" 5051 "Invalid" 5050 "Invalid" 5049 "Invalid" 5048 "Invalid" 5047 "Invalid" 5046 "Invalid" 5045 "Invalid" 5044 "Invalid" 5043 "Invalid" 5042 "Invalid" 5041 "Invalid" 5040 "Invalid" 5039 "Invalid" 5038 "Invalid" 5037 "Invalid" 5036 "Invalid" 5035 "Invalid" 5034 "Invalid" 5033 "Invalid" 5032 "Invalid" 5031 "Invalid" 5030 "Invalid" 5029 "Invalid" 5028 "Invalid" 5027 "Invalid" 5026 "Invalid" 5025 "Invalid" 5024 "Invalid" 5023 "Invalid" 5022 "Invalid" 5021 "Invalid" 5020 "Invalid" 5019 "Invalid" 5018 "Invalid" 5017 "Invalid" 5016 "Invalid" 5015 "Invalid" 5014 "Invalid" 5013 "Invalid" 5012 "Invalid" 5011 "Invalid" 5010 "Invalid" 5009 "Invalid" 5008 "Invalid" 5007 "Invalid" 5006 "Invalid" 5005 "Invalid" 5004 "Invalid" 5003 "Invalid" 5002 "Invalid" 5001 "Invalid" ;
VAL_ 528 BCU_MeaSitOfBattVlt 7 "Outside chargerelay" 6 "Outside dischargerelay" 5 "Outside DC negativerelay" 4 "Outside DC positiverelay" 3 "Outside main negativerelay" 2 "Inside main negativerelay" 1 "Outside main positiverelay" 0 "Inside main positive relay" ;
VAL_ 537 BCU_ChrgBalnCntr 4095 "Invalid" 4094 "Invalid" 4093 "Invalid" 4092 "Invalid" 4091 "Invalid" 4090 "Invalid" 4089 "Invalid" 4088 "Invalid" 4087 "Invalid" 4086 "Invalid" 4085 "Invalid" 4084 "Invalid" 4083 "Invalid" 4082 "Invalid" 4081 "Invalid" 4080 "Invalid" 4079 "Invalid" 4078 "Invalid" 4077 "Invalid" 4076 "Invalid" 4075 "Invalid" 4074 "Invalid" 4073 "Invalid" 4072 "Invalid" 4071 "Invalid" 4070 "Invalid" 4069 "Invalid" 4068 "Invalid" 4067 "Invalid" 4066 "Invalid" 4065 "Invalid" 4064 "Invalid" 4063 "Invalid" 4062 "Invalid" 4061 "Invalid" 4060 "Invalid" 4059 "Invalid" 4058 "Invalid" 4057 "Invalid" 4056 "Invalid" 4055 "Invalid" 4054 "Invalid" 4053 "Invalid" 4052 "Invalid" 4051 "Invalid" 4050 "Invalid" 4049 "Invalid" 4048 "Invalid" 4047 "Invalid" 4046 "Invalid" 4045 "Invalid" 4044 "Invalid" 4043 "Invalid" 4042 "Invalid" 4041 "Invalid" 4040 "Invalid" 4039 "Invalid" 4038 "Invalid" 4037 "Invalid" 4036 "Invalid" 4035 "Invalid" 4034 "Invalid" 4033 "Invalid" 4032 "Invalid" 4031 "Invalid" 4030 "Invalid" 4029 "Invalid" 4028 "Invalid" 4027 "Invalid" 4026 "Invalid" 4025 "Invalid" 4024 "Invalid" 4023 "Invalid" 4022 "Invalid" 4021 "Invalid" 4020 "Invalid" 4019 "Invalid" 4018 "Invalid" 4017 "Invalid" 4016 "Invalid" 4015 "Invalid" 4014 "Invalid" 4013 "Invalid" 4012 "Invalid" 4011 "Invalid" 4010 "Invalid" 4009 "Invalid" 4008 "Invalid" 4007 "Invalid" 4006 "Invalid" 4005 "Invalid" 4004 "Invalid" 4003 "Invalid" 4002 "Invalid" 4001 "Invalid" ;
VAL_ 537 BCU_ChrgBalnTotalCp 1023 "Invalid" 1022 "Invalid" 1021 "Invalid" 1020 "Invalid" 1019 "Invalid" 1018 "Invalid" 1017 "Invalid" 1016 "Invalid" 1015 "Invalid" 1014 "Invalid" 1013 "Invalid" 1012 "Invalid" 1011 "Invalid" 1010 "Invalid" 1009 "Invalid" 1008 "Invalid" 1007 "Invalid" 1006 "Invalid" 1005 "Invalid" 1004 "Invalid" 1003 "Invalid" 1002 "Invalid" 1001 "Invalid" ;
VAL_ 537 BCU_TralBalnCntr 4095 "Invalid" 4094 "Invalid" 4093 "Invalid" 4092 "Invalid" 4091 "Invalid" 4090 "Invalid" 4089 "Invalid" 4088 "Invalid" 4087 "Invalid" 4086 "Invalid" 4085 "Invalid" 4084 "Invalid" 4083 "Invalid" 4082 "Invalid" 4081 "Invalid" 4080 "Invalid" 4079 "Invalid" 4078 "Invalid" 4077 "Invalid" 4076 "Invalid" 4075 "Invalid" 4074 "Invalid" 4073 "Invalid" 4072 "Invalid" 4071 "Invalid" 4070 "Invalid" 4069 "Invalid" 4068 "Invalid" 4067 "Invalid" 4066 "Invalid" 4065 "Invalid" 4064 "Invalid" 4063 "Invalid" 4062 "Invalid" 4061 "Invalid" 4060 "Invalid" 4059 "Invalid" 4058 "Invalid" 4057 "Invalid" 4056 "Invalid" 4055 "Invalid" 4054 "Invalid" 4053 "Invalid" 4052 "Invalid" 4051 "Invalid" 4050 "Invalid" 4049 "Invalid" 4048 "Invalid" 4047 "Invalid" 4046 "Invalid" 4045 "Invalid" 4044 "Invalid" 4043 "Invalid" 4042 "Invalid" 4041 "Invalid" 4040 "Invalid" 4039 "Invalid" 4038 "Invalid" 4037 "Invalid" 4036 "Invalid" 4035 "Invalid" 4034 "Invalid" 4033 "Invalid" 4032 "Invalid" 4031 "Invalid" 4030 "Invalid" 4029 "Invalid" 4028 "Invalid" 4027 "Invalid" 4026 "Invalid" 4025 "Invalid" 4024 "Invalid" 4023 "Invalid" 4022 "Invalid" 4021 "Invalid" 4020 "Invalid" 4019 "Invalid" 4018 "Invalid" 4017 "Invalid" 4016 "Invalid" 4015 "Invalid" 4014 "Invalid" 4013 "Invalid" 4012 "Invalid" 4011 "Invalid" 4010 "Invalid" 4009 "Invalid" 4008 "Invalid" 4007 "Invalid" 4006 "Invalid" 4005 "Invalid" 4004 "Invalid" 4003 "Invalid" 4002 "Invalid" 4001 "Invalid" ;
VAL_ 537 BCU_TralBalnTotalCp 1023 "Invalid" 1022 "Invalid" 1021 "Invalid" 1020 "Invalid" 1019 "Invalid" 1018 "Invalid" 1017 "Invalid" 1016 "Invalid" 1015 "Invalid" 1014 "Invalid" 1013 "Invalid" 1012 "Invalid" 1011 "Invalid" 1010 "Invalid" 1009 "Invalid" 1008 "Invalid" 1007 "Invalid" 1006 "Invalid" 1005 "Invalid" 1004 "Invalid" 1003 "Invalid" 1002 "Invalid" 1001 "Invalid" ;
VAL_ 537 BCU_ActlSOC 1023 "Invalid" 1022 "Invalid" 1021 "Invalid" 1020 "Invalid" 1019 "Invalid" 1018 "Invalid" 1017 "Invalid" 1016 "Invalid" 1015 "Invalid" 1014 "Invalid" 1013 "Invalid" 1012 "Invalid" 1011 "Invalid" 1010 "Invalid" 1009 "Invalid" 1008 "Invalid" 1007 "Invalid" 1006 "Invalid" 1005 "Invalid" 1004 "Invalid" 1003 "Invalid" 1002 "Invalid" 1001 "Invalid" ;
VAL_ 537 BCU_CtnuDCChrgNr 63 "Invalid" 62 "Invalid" 61 "Invalid" ;
VAL_ 537 BCU_BalnSts 7 "Reserved" 6 "Reserved" 5 "Reserved" 4 "Reserved" 3 "Reserved" 2 "Stop balance" 1 "Start balance" 0 "No balance" ;
VAL_ 1061 BCU_CellVlt091_RM 2047 "Invalid" 2046 "Invalid" 2045 "Invalid" 2044 "Invalid" 2043 "Invalid" 2042 "Invalid" 2041 "Invalid" 2040 "Invalid" 2039 "Invalid" 2038 "Invalid" 2037 "Invalid" 2036 "Invalid" 2035 "Invalid" 2034 "Invalid" 2033 "Invalid" 2032 "Invalid" 2031 "Invalid" 2030 "Invalid" 2029 "Invalid" 2028 "Invalid" 2027 "Invalid" 2026 "Invalid" 2025 "Invalid" 2024 "Invalid" 2023 "Invalid" 2022 "Invalid" 2021 "Invalid" 2020 "Invalid" 2019 "Invalid" 2018 "Invalid" 2017 "Invalid" 2016 "Invalid" 2015 "Invalid" 2014 "Invalid" 2013 "Invalid" 2012 "Invalid" 2011 "Invalid" 2010 "Invalid" 2009 "Invalid" 2008 "Invalid" 2007 "Invalid" 2006 "Invalid" 2005 "Invalid" 2004 "Invalid" 2003 "Invalid" 2002 "Invalid" 2001 "Invalid" 2000 "Invalid" 1999 "Invalid" 1998 "Invalid" 1997 "Invalid" 1996 "Invalid" 1995 "Invalid" 1994 "Invalid" 1993 "Invalid" 1992 "Invalid" 1991 "Invalid" 1990 "Invalid" 1989 "Invalid" 1988 "Invalid" 1987 "Invalid" 1986 "Invalid" 1985 "Invalid" 1984 "Invalid" 1983 "Invalid" 1982 "Invalid" 1981 "Invalid" 1980 "Invalid" 1979 "Invalid" 1978 "Invalid" 1977 "Invalid" 1976 "Invalid" 1975 "Invalid" 1974 "Invalid" 1973 "Invalid" 1972 "Invalid" 1971 "Invalid" 1970 "Invalid" 1969 "Invalid" 1968 "Invalid" 1967 "Invalid" 1966 "Invalid" 1965 "Invalid" 1964 "Invalid" 1963 "Invalid" 1962 "Invalid" 1961 "Invalid" 1960 "Invalid" 1959 "Invalid" 1958 "Invalid" 1957 "Invalid" 1956 "Invalid" 1955 "Invalid" 1954 "Invalid" 1953 "Invalid" 1952 "Invalid" 1951 "Invalid" 1950 "Invalid" 1949 "Invalid" 1948 "Invalid" 1947 "Invalid" 1946 "Invalid" 1945 "Invalid" 1944 "Invalid" 1943 "Invalid" 1942 "Invalid" 1941 "Invalid" 1940 "Invalid" 1939 "Invalid" 1938 "Invalid" 1937 "Invalid" 1936 "Invalid" 1935 "Invalid" 1934 "Invalid" 1933 "Invalid" 1932 "Invalid" 1931 "Invalid" 1930 "Invalid" 1929 "Invalid" 1928 "Invalid" 1927 "Invalid" 1926 "Invalid" 1925 "Invalid" 1924 "Invalid" 1923 "Invalid" 1922 "Invalid" 1921 "Invalid" 1920 "Invalid" 1919 "Invalid" 1918 "Invalid" 1917 "Invalid" 1916 "Invalid" 1915 "Invalid" 1914 "Invalid" 1913 "Invalid" 1912 "Invalid" 1911 "Invalid" 1910 "Invalid" 1909 "Invalid" 1908 "Invalid" 1907 "Invalid" 1906 "Invalid" 1905 "Invalid" 1904 "Invalid" 1903 "Invalid" 1902 "Invalid" 1901 "Invalid" 1900 "Invalid" 1899 "Invalid" 1898 "Invalid" 1897 "Invalid" 1896 "Invalid" 1895 "Invalid" 1894 "Invalid" 1893 "Invalid" 1892 "Invalid" 1891 "Invalid" 1890 "Invalid" 1889 "Invalid" 1888 "Invalid" 1887 "Invalid" 1886 "Invalid" 1885 "Invalid" 1884 "Invalid" 1883 "Invalid" 1882 "Invalid" 1881 "Invalid" 1880 "Invalid" 1879 "Invalid" 1878 "Invalid" 1877 "Invalid" 1876 "Invalid" 1875 "Invalid" 1874 "Invalid" 1873 "Invalid" 1872 "Invalid" 1871 "Invalid" 1870 "Invalid" 1869 "Invalid" 1868 "Invalid" 1867 "Invalid" 1866 "Invalid" 1865 "Invalid" 1864 "Invalid" 1863 "Invalid" 1862 "Invalid" 1861 "Invalid" 1860 "Invalid" 1859 "Invalid" 1858 "Invalid" 1857 "Invalid" 1856 "Invalid" 1855 "Invalid" 1854 "Invalid" 1853 "Invalid" 1852 "Invalid" 1851 "Invalid" 1850 "Invalid" 1849 "Invalid" 1848 "Invalid" 1847 "Invalid" 1846 "Invalid" 1845 "Invalid" 1844 "Invalid" 1843 "Invalid" 1842 "Invalid" 1841 "Invalid" 1840 "Invalid" 1839 "Invalid" 1838 "Invalid" 1837 "Invalid" 1836 "Invalid" 1835 "Invalid" 1834 "Invalid" 1833 "Invalid" 1832 "Invalid" 1831 "Invalid" 1830 "Invalid" 1829 "Invalid" 1828 "Invalid" 1827 "Invalid" 1826 "Invalid" 1825 "Invalid" 1824 "Invalid" 1823 "Invalid" 1822 "Invalid" 1821 "Invalid" 1820 "Invalid" 1819 "Invalid" 1818 "Invalid" 1817 "Invalid" 1816 "Invalid" 1815 "Invalid" 1814 "Invalid" 1813 "Invalid" 1812 "Invalid" 1811 "Invalid" 1810 "Invalid" 1809 "Invalid" 1808 "Invalid" 1807 "Invalid" 1806 "Invalid" 1805 "Invalid" 1804 "Invalid" 1803 "Invalid" 1802 "Invalid" 1801 "Invalid" ;
VAL_ 1061 BCU_CellVlt092_RM 2047 "Invalid" 2046 "Invalid" 2045 "Invalid" 2044 "Invalid" 2043 "Invalid" 2042 "Invalid" 2041 "Invalid" 2040 "Invalid" 2039 "Invalid" 2038 "Invalid" 2037 "Invalid" 2036 "Invalid" 2035 "Invalid" 2034 "Invalid" 2033 "Invalid" 2032 "Invalid" 2031 "Invalid" 2030 "Invalid" 2029 "Invalid" 2028 "Invalid" 2027 "Invalid" 2026 "Invalid" 2025 "Invalid" 2024 "Invalid" 2023 "Invalid" 2022 "Invalid" 2021 "Invalid" 2020 "Invalid" 2019 "Invalid" 2018 "Invalid" 2017 "Invalid" 2016 "Invalid" 2015 "Invalid" 2014 "Invalid" 2013 "Invalid" 2012 "Invalid" 2011 "Invalid" 2010 "Invalid" 2009 "Invalid" 2008 "Invalid" 2007 "Invalid" 2006 "Invalid" 2005 "Invalid" 2004 "Invalid" 2003 "Invalid" 2002 "Invalid" 2001 "Invalid" 2000 "Invalid" 1999 "Invalid" 1998 "Invalid" 1997 "Invalid" 1996 "Invalid" 1995 "Invalid" 1994 "Invalid" 1993 "Invalid" 1992 "Invalid" 1991 "Invalid" 1990 "Invalid" 1989 "Invalid" 1988 "Invalid" 1987 "Invalid" 1986 "Invalid" 1985 "Invalid" 1984 "Invalid" 1983 "Invalid" 1982 "Invalid" 1981 "Invalid" 1980 "Invalid" 1979 "Invalid" 1978 "Invalid" 1977 "Invalid" 1976 "Invalid" 1975 "Invalid" 1974 "Invalid" 1973 "Invalid" 1972 "Invalid" 1971 "Invalid" 1970 "Invalid" 1969 "Invalid" 1968 "Invalid" 1967 "Invalid" 1966 "Invalid" 1965 "Invalid" 1964 "Invalid" 1963 "Invalid" 1962 "Invalid" 1961 "Invalid" 1960 "Invalid" 1959 "Invalid" 1958 "Invalid" 1957 "Invalid" 1956 "Invalid" 1955 "Invalid" 1954 "Invalid" 1953 "Invalid" 1952 "Invalid" 1951 "Invalid" 1950 "Invalid" 1949 "Invalid" 1948 "Invalid" 1947 "Invalid" 1946 "Invalid" 1945 "Invalid" 1944 "Invalid" 1943 "Invalid" 1942 "Invalid" 1941 "Invalid" 1940 "Invalid" 1939 "Invalid" 1938 "Invalid" 1937 "Invalid" 1936 "Invalid" 1935 "Invalid" 1934 "Invalid" 1933 "Invalid" 1932 "Invalid" 1931 "Invalid" 1930 "Invalid" 1929 "Invalid" 1928 "Invalid" 1927 "Invalid" 1926 "Invalid" 1925 "Invalid" 1924 "Invalid" 1923 "Invalid" 1922 "Invalid" 1921 "Invalid" 1920 "Invalid" 1919 "Invalid" 1918 "Invalid" 1917 "Invalid" 1916 "Invalid" 1915 "Invalid" 1914 "Invalid" 1913 "Invalid" 1912 "Invalid" 1911 "Invalid" 1910 "Invalid" 1909 "Invalid" 1908 "Invalid" 1907 "Invalid" 1906 "Invalid" 1905 "Invalid" 1904 "Invalid" 1903 "Invalid" 1902 "Invalid" 1901 "Invalid" 1900 "Invalid" 1899 "Invalid" 1898 "Invalid" 1897 "Invalid" 1896 "Invalid" 1895 "Invalid" 1894 "Invalid" 1893 "Invalid" 1892 "Invalid" 1891 "Invalid" 1890 "Invalid" 1889 "Invalid" 1888 "Invalid" 1887 "Invalid" 1886 "Invalid" 1885 "Invalid" 1884 "Invalid" 1883 "Invalid" 1882 "Invalid" 1881 "Invalid" 1880 "Invalid" 1879 "Invalid" 1878 "Invalid" 1877 "Invalid" 1876 "Invalid" 1875 "Invalid" 1874 "Invalid" 1873 "Invalid" 1872 "Invalid" 1871 "Invalid" 1870 "Invalid" 1869 "Invalid" 1868 "Invalid" 1867 "Invalid" 1866 "Invalid" 1865 "Invalid" 1864 "Invalid" 1863 "Invalid" 1862 "Invalid" 1861 "Invalid" 1860 "Invalid" 1859 "Invalid" 1858 "Invalid" 1857 "Invalid" 1856 "Invalid" 1855 "Invalid" 1854 "Invalid" 1853 "Invalid" 1852 "Invalid" 1851 "Invalid" 1850 "Invalid" 1849 "Invalid" 1848 "Invalid" 1847 "Invalid" 1846 "Invalid" 1845 "Invalid" 1844 "Invalid" 1843 "Invalid" 1842 "Invalid" 1841 "Invalid" 1840 "Invalid" 1839 "Invalid" 1838 "Invalid" 1837 "Invalid" 1836 "Invalid" 1835 "Invalid" 1834 "Invalid" 1833 "Invalid" 1832 "Invalid" 1831 "Invalid" 1830 "Invalid" 1829 "Invalid" 1828 "Invalid" 1827 "Invalid" 1826 "Invalid" 1825 "Invalid" 1824 "Invalid" 1823 "Invalid" 1822 "Invalid" 1821 "Invalid" 1820 "Invalid" 1819 "Invalid" 1818 "Invalid" 1817 "Invalid" 1816 "Invalid" 1815 "Invalid" 1814 "Invalid" 1813 "Invalid" 1812 "Invalid" 1811 "Invalid" 1810 "Invalid" 1809 "Invalid" 1808 "Invalid" 1807 "Invalid" 1806 "Invalid" 1805 "Invalid" 1804 "Invalid" 1803 "Invalid" 1802 "Invalid" 1801 "Invalid" ;
VAL_ 1061 BCU_CellVlt093_RM 2047 "Invalid" 2046 "Invalid" 2045 "Invalid" 2044 "Invalid" 2043 "Invalid" 2042 "Invalid" 2041 "Invalid" 2040 "Invalid" 2039 "Invalid" 2038 "Invalid" 2037 "Invalid" 2036 "Invalid" 2035 "Invalid" 2034 "Invalid" 2033 "Invalid" 2032 "Invalid" 2031 "Invalid" 2030 "Invalid" 2029 "Invalid" 2028 "Invalid" 2027 "Invalid" 2026 "Invalid" 2025 "Invalid" 2024 "Invalid" 2023 "Invalid" 2022 "Invalid" 2021 "Invalid" 2020 "Invalid" 2019 "Invalid" 2018 "Invalid" 2017 "Invalid" 2016 "Invalid" 2015 "Invalid" 2014 "Invalid" 2013 "Invalid" 2012 "Invalid" 2011 "Invalid" 2010 "Invalid" 2009 "Invalid" 2008 "Invalid" 2007 "Invalid" 2006 "Invalid" 2005 "Invalid" 2004 "Invalid" 2003 "Invalid" 2002 "Invalid" 2001 "Invalid" 2000 "Invalid" 1999 "Invalid" 1998 "Invalid" 1997 "Invalid" 1996 "Invalid" 1995 "Invalid" 1994 "Invalid" 1993 "Invalid" 1992 "Invalid" 1991 "Invalid" 1990 "Invalid" 1989 "Invalid" 1988 "Invalid" 1987 "Invalid" 1986 "Invalid" 1985 "Invalid" 1984 "Invalid" 1983 "Invalid" 1982 "Invalid" 1981 "Invalid" 1980 "Invalid" 1979 "Invalid" 1978 "Invalid" 1977 "Invalid" 1976 "Invalid" 1975 "Invalid" 1974 "Invalid" 1973 "Invalid" 1972 "Invalid" 1971 "Invalid" 1970 "Invalid" 1969 "Invalid" 1968 "Invalid" 1967 "Invalid" 1966 "Invalid" 1965 "Invalid" 1964 "Invalid" 1963 "Invalid" 1962 "Invalid" 1961 "Invalid" 1960 "Invalid" 1959 "Invalid" 1958 "Invalid" 1957 "Invalid" 1956 "Invalid" 1955 "Invalid" 1954 "Invalid" 1953 "Invalid" 1952 "Invalid" 1951 "Invalid" 1950 "Invalid" 1949 "Invalid" 1948 "Invalid" 1947 "Invalid" 1946 "Invalid" 1945 "Invalid" 1944 "Invalid" 1943 "Invalid" 1942 "Invalid" 1941 "Invalid" 1940 "Invalid" 1939 "Invalid" 1938 "Invalid" 1937 "Invalid" 1936 "Invalid" 1935 "Invalid" 1934 "Invalid" 1933 "Invalid" 1932 "Invalid" 1931 "Invalid" 1930 "Invalid" 1929 "Invalid" 1928 "Invalid" 1927 "Invalid" 1926 "Invalid" 1925 "Invalid" 1924 "Invalid" 1923 "Invalid" 1922 "Invalid" 1921 "Invalid" 1920 "Invalid" 1919 "Invalid" 1918 "Invalid" 1917 "Invalid" 1916 "Invalid" 1915 "Invalid" 1914 "Invalid" 1913 "Invalid" 1912 "Invalid" 1911 "Invalid" 1910 "Invalid" 1909 "Invalid" 1908 "Invalid" 1907 "Invalid" 1906 "Invalid" 1905 "Invalid" 1904 "Invalid" 1903 "Invalid" 1902 "Invalid" 1901 "Invalid" 1900 "Invalid" 1899 "Invalid" 1898 "Invalid" 1897 "Invalid" 1896 "Invalid" 1895 "Invalid" 1894 "Invalid" 1893 "Invalid" 1892 "Invalid" 1891 "Invalid" 1890 "Invalid" 1889 "Invalid" 1888 "Invalid" 1887 "Invalid" 1886 "Invalid" 1885 "Invalid" 1884 "Invalid" 1883 "Invalid" 1882 "Invalid" 1881 "Invalid" 1880 "Invalid" 1879 "Invalid" 1878 "Invalid" 1877 "Invalid" 1876 "Invalid" 1875 "Invalid" 1874 "Invalid" 1873 "Invalid" 1872 "Invalid" 1871 "Invalid" 1870 "Invalid" 1869 "Invalid" 1868 "Invalid" 1867 "Invalid" 1866 "Invalid" 1865 "Invalid" 1864 "Invalid" 1863 "Invalid" 1862 "Invalid" 1861 "Invalid" 1860 "Invalid" 1859 "Invalid" 1858 "Invalid" 1857 "Invalid" 1856 "Invalid" 1855 "Invalid" 1854 "Invalid" 1853 "Invalid" 1852 "Invalid" 1851 "Invalid" 1850 "Invalid" 1849 "Invalid" 1848 "Invalid" 1847 "Invalid" 1846 "Invalid" 1845 "Invalid" 1844 "Invalid" 1843 "Invalid" 1842 "Invalid" 1841 "Invalid" 1840 "Invalid" 1839 "Invalid" 1838 "Invalid" 1837 "Invalid" 1836 "Invalid" 1835 "Invalid" 1834 "Invalid" 1833 "Invalid" 1832 "Invalid" 1831 "Invalid" 1830 "Invalid" 1829 "Invalid" 1828 "Invalid" 1827 "Invalid" 1826 "Invalid" 1825 "Invalid" 1824 "Invalid" 1823 "Invalid" 1822 "Invalid" 1821 "Invalid" 1820 "Invalid" 1819 "Invalid" 1818 "Invalid" 1817 "Invalid" 1816 "Invalid" 1815 "Invalid" 1814 "Invalid" 1813 "Invalid" 1812 "Invalid" 1811 "Invalid" 1810 "Invalid" 1809 "Invalid" 1808 "Invalid" 1807 "Invalid" 1806 "Invalid" 1805 "Invalid" 1804 "Invalid" 1803 "Invalid" 1802 "Invalid" 1801 "Invalid" ;
VAL_ 1061 BCU_CellVlt094_RM 2047 "Invalid" 2046 "Invalid" 2045 "Invalid" 2044 "Invalid" 2043 "Invalid" 2042 "Invalid" 2041 "Invalid" 2040 "Invalid" 2039 "Invalid" 2038 "Invalid" 2037 "Invalid" 2036 "Invalid" 2035 "Invalid" 2034 "Invalid" 2033 "Invalid" 2032 "Invalid" 2031 "Invalid" 2030 "Invalid" 2029 "Invalid" 2028 "Invalid" 2027 "Invalid" 2026 "Invalid" 2025 "Invalid" 2024 "Invalid" 2023 "Invalid" 2022 "Invalid" 2021 "Invalid" 2020 "Invalid" 2019 "Invalid" 2018 "Invalid" 2017 "Invalid" 2016 "Invalid" 2015 "Invalid" 2014 "Invalid" 2013 "Invalid" 2012 "Invalid" 2011 "Invalid" 2010 "Invalid" 2009 "Invalid" 2008 "Invalid" 2007 "Invalid" 2006 "Invalid" 2005 "Invalid" 2004 "Invalid" 2003 "Invalid" 2002 "Invalid" 2001 "Invalid" 2000 "Invalid" 1999 "Invalid" 1998 "Invalid" 1997 "Invalid" 1996 "Invalid" 1995 "Invalid" 1994 "Invalid" 1993 "Invalid" 1992 "Invalid" 1991 "Invalid" 1990 "Invalid" 1989 "Invalid" 1988 "Invalid" 1987 "Invalid" 1986 "Invalid" 1985 "Invalid" 1984 "Invalid" 1983 "Invalid" 1982 "Invalid" 1981 "Invalid" 1980 "Invalid" 1979 "Invalid" 1978 "Invalid" 1977 "Invalid" 1976 "Invalid" 1975 "Invalid" 1974 "Invalid" 1973 "Invalid" 1972 "Invalid" 1971 "Invalid" 1970 "Invalid" 1969 "Invalid" 1968 "Invalid" 1967 "Invalid" 1966 "Invalid" 1965 "Invalid" 1964 "Invalid" 1963 "Invalid" 1962 "Invalid" 1961 "Invalid" 1960 "Invalid" 1959 "Invalid" 1958 "Invalid" 1957 "Invalid" 1956 "Invalid" 1955 "Invalid" 1954 "Invalid" 1953 "Invalid" 1952 "Invalid" 1951 "Invalid" 1950 "Invalid" 1949 "Invalid" 1948 "Invalid" 1947 "Invalid" 1946 "Invalid" 1945 "Invalid" 1944 "Invalid" 1943 "Invalid" 1942 "Invalid" 1941 "Invalid" 1940 "Invalid" 1939 "Invalid" 1938 "Invalid" 1937 "Invalid" 1936 "Invalid" 1935 "Invalid" 1934 "Invalid" 1933 "Invalid" 1932 "Invalid" 1931 "Invalid" 1930 "Invalid" 1929 "Invalid" 1928 "Invalid" 1927 "Invalid" 1926 "Invalid" 1925 "Invalid" 1924 "Invalid" 1923 "Invalid" 1922 "Invalid" 1921 "Invalid" 1920 "Invalid" 1919 "Invalid" 1918 "Invalid" 1917 "Invalid" 1916 "Invalid" 1915 "Invalid" 1914 "Invalid" 1913 "Invalid" 1912 "Invalid" 1911 "Invalid" 1910 "Invalid" 1909 "Invalid" 1908 "Invalid" 1907 "Invalid" 1906 "Invalid" 1905 "Invalid" 1904 "Invalid" 1903 "Invalid" 1902 "Invalid" 1901 "Invalid" 1900 "Invalid" 1899 "Invalid" 1898 "Invalid" 1897 "Invalid" 1896 "Invalid" 1895 "Invalid" 1894 "Invalid" 1893 "Invalid" 1892 "Invalid" 1891 "Invalid" 1890 "Invalid" 1889 "Invalid" 1888 "Invalid" 1887 "Invalid" 1886 "Invalid" 1885 "Invalid" 1884 "Invalid" 1883 "Invalid" 1882 "Invalid" 1881 "Invalid" 1880 "Invalid" 1879 "Invalid" 1878 "Invalid" 1877 "Invalid" 1876 "Invalid" 1875 "Invalid" 1874 "Invalid" 1873 "Invalid" 1872 "Invalid" 1871 "Invalid" 1870 "Invalid" 1869 "Invalid" 1868 "Invalid" 1867 "Invalid" 1866 "Invalid" 1865 "Invalid" 1864 "Invalid" 1863 "Invalid" 1862 "Invalid" 1861 "Invalid" 1860 "Invalid" 1859 "Invalid" 1858 "Invalid" 1857 "Invalid" 1856 "Invalid" 1855 "Invalid" 1854 "Invalid" 1853 "Invalid" 1852 "Invalid" 1851 "Invalid" 1850 "Invalid" 1849 "Invalid" 1848 "Invalid" 1847 "Invalid" 1846 "Invalid" 1845 "Invalid" 1844 "Invalid" 1843 "Invalid" 1842 "Invalid" 1841 "Invalid" 1840 "Invalid" 1839 "Invalid" 1838 "Invalid" 1837 "Invalid" 1836 "Invalid" 1835 "Invalid" 1834 "Invalid" 1833 "Invalid" 1832 "Invalid" 1831 "Invalid" 1830 "Invalid" 1829 "Invalid" 1828 "Invalid" 1827 "Invalid" 1826 "Invalid" 1825 "Invalid" 1824 "Invalid" 1823 "Invalid" 1822 "Invalid" 1821 "Invalid" 1820 "Invalid" 1819 "Invalid" 1818 "Invalid" 1817 "Invalid" 1816 "Invalid" 1815 "Invalid" 1814 "Invalid" 1813 "Invalid" 1812 "Invalid" 1811 "Invalid" 1810 "Invalid" 1809 "Invalid" 1808 "Invalid" 1807 "Invalid" 1806 "Invalid" 1805 "Invalid" 1804 "Invalid" 1803 "Invalid" 1802 "Invalid" 1801 "Invalid" ;
VAL_ 1061 BCU_CellVlt095_RM 2047 "Invalid" 2046 "Invalid" 2045 "Invalid" 2044 "Invalid" 2043 "Invalid" 2042 "Invalid" 2041 "Invalid" 2040 "Invalid" 2039 "Invalid" 2038 "Invalid" 2037 "Invalid" 2036 "Invalid" 2035 "Invalid" 2034 "Invalid" 2033 "Invalid" 2032 "Invalid" 2031 "Invalid" 2030 "Invalid" 2029 "Invalid" 2028 "Invalid" 2027 "Invalid" 2026 "Invalid" 2025 "Invalid" 2024 "Invalid" 2023 "Invalid" 2022 "Invalid" 2021 "Invalid" 2020 "Invalid" 2019 "Invalid" 2018 "Invalid" 2017 "Invalid" 2016 "Invalid" 2015 "Invalid" 2014 "Invalid" 2013 "Invalid" 2012 "Invalid" 2011 "Invalid" 2010 "Invalid" 2009 "Invalid" 2008 "Invalid" 2007 "Invalid" 2006 "Invalid" 2005 "Invalid" 2004 "Invalid" 2003 "Invalid" 2002 "Invalid" 2001 "Invalid" 2000 "Invalid" 1999 "Invalid" 1998 "Invalid" 1997 "Invalid" 1996 "Invalid" 1995 "Invalid" 1994 "Invalid" 1993 "Invalid" 1992 "Invalid" 1991 "Invalid" 1990 "Invalid" 1989 "Invalid" 1988 "Invalid" 1987 "Invalid" 1986 "Invalid" 1985 "Invalid" 1984 "Invalid" 1983 "Invalid" 1982 "Invalid" 1981 "Invalid" 1980 "Invalid" 1979 "Invalid" 1978 "Invalid" 1977 "Invalid" 1976 "Invalid" 1975 "Invalid" 1974 "Invalid" 1973 "Invalid" 1972 "Invalid" 1971 "Invalid" 1970 "Invalid" 1969 "Invalid" 1968 "Invalid" 1967 "Invalid" 1966 "Invalid" 1965 "Invalid" 1964 "Invalid" 1963 "Invalid" 1962 "Invalid" 1961 "Invalid" 1960 "Invalid" 1959 "Invalid" 1958 "Invalid" 1957 "Invalid" 1956 "Invalid" 1955 "Invalid" 1954 "Invalid" 1953 "Invalid" 1952 "Invalid" 1951 "Invalid" 1950 "Invalid" 1949 "Invalid" 1948 "Invalid" 1947 "Invalid" 1946 "Invalid" 1945 "Invalid" 1944 "Invalid" 1943 "Invalid" 1942 "Invalid" 1941 "Invalid" 1940 "Invalid" 1939 "Invalid" 1938 "Invalid" 1937 "Invalid" 1936 "Invalid" 1935 "Invalid" 1934 "Invalid" 1933 "Invalid" 1932 "Invalid" 1931 "Invalid" 1930 "Invalid" 1929 "Invalid" 1928 "Invalid" 1927 "Invalid" 1926 "Invalid" 1925 "Invalid" 1924 "Invalid" 1923 "Invalid" 1922 "Invalid" 1921 "Invalid" 1920 "Invalid" 1919 "Invalid" 1918 "Invalid" 1917 "Invalid" 1916 "Invalid" 1915 "Invalid" 1914 "Invalid" 1913 "Invalid" 1912 "Invalid" 1911 "Invalid" 1910 "Invalid" 1909 "Invalid" 1908 "Invalid" 1907 "Invalid" 1906 "Invalid" 1905 "Invalid" 1904 "Invalid" 1903 "Invalid" 1902 "Invalid" 1901 "Invalid" 1900 "Invalid" 1899 "Invalid" 1898 "Invalid" 1897 "Invalid" 1896 "Invalid" 1895 "Invalid" 1894 "Invalid" 1893 "Invalid" 1892 "Invalid" 1891 "Invalid" 1890 "Invalid" 1889 "Invalid" 1888 "Invalid" 1887 "Invalid" 1886 "Invalid" 1885 "Invalid" 1884 "Invalid" 1883 "Invalid" 1882 "Invalid" 1881 "Invalid" 1880 "Invalid" 1879 "Invalid" 1878 "Invalid" 1877 "Invalid" 1876 "Invalid" 1875 "Invalid" 1874 "Invalid" 1873 "Invalid" 1872 "Invalid" 1871 "Invalid" 1870 "Invalid" 1869 "Invalid" 1868 "Invalid" 1867 "Invalid" 1866 "Invalid" 1865 "Invalid" 1864 "Invalid" 1863 "Invalid" 1862 "Invalid" 1861 "Invalid" 1860 "Invalid" 1859 "Invalid" 1858 "Invalid" 1857 "Invalid" 1856 "Invalid" 1855 "Invalid" 1854 "Invalid" 1853 "Invalid" 1852 "Invalid" 1851 "Invalid" 1850 "Invalid" 1849 "Invalid" 1848 "Invalid" 1847 "Invalid" 1846 "Invalid" 1845 "Invalid" 1844 "Invalid" 1843 "Invalid" 1842 "Invalid" 1841 "Invalid" 1840 "Invalid" 1839 "Invalid" 1838 "Invalid" 1837 "Invalid" 1836 "Invalid" 1835 "Invalid" 1834 "Invalid" 1833 "Invalid" 1832 "Invalid" 1831 "Invalid" 1830 "Invalid" 1829 "Invalid" 1828 "Invalid" 1827 "Invalid" 1826 "Invalid" 1825 "Invalid" 1824 "Invalid" 1823 "Invalid" 1822 "Invalid" 1821 "Invalid" 1820 "Invalid" 1819 "Invalid" 1818 "Invalid" 1817 "Invalid" 1816 "Invalid" 1815 "Invalid" 1814 "Invalid" 1813 "Invalid" 1812 "Invalid" 1811 "Invalid" 1810 "Invalid" 1809 "Invalid" 1808 "Invalid" 1807 "Invalid" 1806 "Invalid" 1805 "Invalid" 1804 "Invalid" 1803 "Invalid" 1802 "Invalid" 1801 "Invalid" ;
VAL_ 1061 BCU_CellTmp019_RM 255 "Invalid" 254 "Invalid" 253 "Invalid" 252 "Invalid" 251 "Invalid" 250 "Invalid" 249 "Invalid" 248 "Invalid" 247 "Invalid" 246 "Invalid" 245 "Invalid" 244 "Invalid" 243 "Invalid" 242 "Invalid" 241 "Invalid" 240 "Invalid" 239 "Invalid" 238 "Invalid" 237 "Invalid" 236 "Invalid" 235 "Invalid" 234 "Invalid" 233 "Invalid" 232 "Invalid" 231 "Invalid" 230 "Invalid" 229 "Invalid" 228 "Invalid" 227 "Invalid" 226 "Invalid" 225 "Invalid" 224 "Invalid" 223 "Invalid" 222 "Invalid" 221 "Invalid" 220 "Invalid" 219 "Invalid" 218 "Invalid" 217 "Invalid" 216 "Invalid" 215 "Invalid" 214 "Invalid" 213 "Invalid" 212 "Invalid" 211 "Invalid" 210 "Invalid" 209 "Invalid" 208 "Invalid" 207 "Invalid" 206 "Invalid" 205 "Invalid" 204 "Invalid" 203 "Invalid" 202 "Invalid" 201 "Invalid" 200 "Invalid" 199 "Invalid" 198 "Invalid" 197 "Invalid" 196 "Invalid" 195 "Invalid" 194 "Invalid" 193 "Invalid" 192 "Invalid" 191 "Invalid" 190 "Invalid" 189 "Invalid" 188 "Invalid" 187 "Invalid" 186 "Invalid" 185 "Invalid" 184 "Invalid" 183 "Invalid" 182 "Invalid" 181 "Invalid" 180 "Invalid" 179 "Invalid" 178 "Invalid" 177 "Invalid" 176 "Invalid" 175 "Invalid" 174 "Invalid" 173 "Invalid" 172 "Invalid" 171 "Invalid" 170 "Invalid" 169 "Invalid" 168 "Invalid" 167 "Invalid" 166 "Invalid" 165 "Invalid" 164 "Invalid" 163 "Invalid" 162 "Invalid" 161 "Invalid" ;
VAL_ 1062 BCU_CellVlt096_RM 2047 "Invalid" 2046 "Invalid" 2045 "Invalid" 2044 "Invalid" 2043 "Invalid" 2042 "Invalid" 2041 "Invalid" 2040 "Invalid" 2039 "Invalid" 2038 "Invalid" 2037 "Invalid" 2036 "Invalid" 2035 "Invalid" 2034 "Invalid" 2033 "Invalid" 2032 "Invalid" 2031 "Invalid" 2030 "Invalid" 2029 "Invalid" 2028 "Invalid" 2027 "Invalid" 2026 "Invalid" 2025 "Invalid" 2024 "Invalid" 2023 "Invalid" 2022 "Invalid" 2021 "Invalid" 2020 "Invalid" 2019 "Invalid" 2018 "Invalid" 2017 "Invalid" 2016 "Invalid" 2015 "Invalid" 2014 "Invalid" 2013 "Invalid" 2012 "Invalid" 2011 "Invalid" 2010 "Invalid" 2009 "Invalid" 2008 "Invalid" 2007 "Invalid" 2006 "Invalid" 2005 "Invalid" 2004 "Invalid" 2003 "Invalid" 2002 "Invalid" 2001 "Invalid" 2000 "Invalid" 1999 "Invalid" 1998 "Invalid" 1997 "Invalid" 1996 "Invalid" 1995 "Invalid" 1994 "Invalid" 1993 "Invalid" 1992 "Invalid" 1991 "Invalid" 1990 "Invalid" 1989 "Invalid" 1988 "Invalid" 1987 "Invalid" 1986 "Invalid" 1985 "Invalid" 1984 "Invalid" 1983 "Invalid" 1982 "Invalid" 1981 "Invalid" 1980 "Invalid" 1979 "Invalid" 1978 "Invalid" 1977 "Invalid" 1976 "Invalid" 1975 "Invalid" 1974 "Invalid" 1973 "Invalid" 1972 "Invalid" 1971 "Invalid" 1970 "Invalid" 1969 "Invalid" 1968 "Invalid" 1967 "Invalid" 1966 "Invalid" 1965 "Invalid" 1964 "Invalid" 1963 "Invalid" 1962 "Invalid" 1961 "Invalid" 1960 "Invalid" 1959 "Invalid" 1958 "Invalid" 1957 "Invalid" 1956 "Invalid" 1955 "Invalid" 1954 "Invalid" 1953 "Invalid" 1952 "Invalid" 1951 "Invalid" 1950 "Invalid" 1949 "Invalid" 1948 "Invalid" 1947 "Invalid" 1946 "Invalid" 1945 "Invalid" 1944 "Invalid" 1943 "Invalid" 1942 "Invalid" 1941 "Invalid" 1940 "Invalid" 1939 "Invalid" 1938 "Invalid" 1937 "Invalid" 1936 "Invalid" 1935 "Invalid" 1934 "Invalid" 1933 "Invalid" 1932 "Invalid" 1931 "Invalid" 1930 "Invalid" 1929 "Invalid" 1928 "Invalid" 1927 "Invalid" 1926 "Invalid" 1925 "Invalid" 1924 "Invalid" 1923 "Invalid" 1922 "Invalid" 1921 "Invalid" 1920 "Invalid" 1919 "Invalid" 1918 "Invalid" 1917 "Invalid" 1916 "Invalid" 1915 "Invalid" 1914 "Invalid" 1913 "Invalid" 1912 "Invalid" 1911 "Invalid" 1910 "Invalid" 1909 "Invalid" 1908 "Invalid" 1907 "Invalid" 1906 "Invalid" 1905 "Invalid" 1904 "Invalid" 1903 "Invalid" 1902 "Invalid" 1901 "Invalid" 1900 "Invalid" 1899 "Invalid" 1898 "Invalid" 1897 "Invalid" 1896 "Invalid" 1895 "Invalid" 1894 "Invalid" 1893 "Invalid" 1892 "Invalid" 1891 "Invalid" 1890 "Invalid" 1889 "Invalid" 1888 "Invalid" 1887 "Invalid" 1886 "Invalid" 1885 "Invalid" 1884 "Invalid" 1883 "Invalid" 1882 "Invalid" 1881 "Invalid" 1880 "Invalid" 1879 "Invalid" 1878 "Invalid" 1877 "Invalid" 1876 "Invalid" 1875 "Invalid" 1874 "Invalid" 1873 "Invalid" 1872 "Invalid" 1871 "Invalid" 1870 "Invalid" 1869 "Invalid" 1868 "Invalid" 1867 "Invalid" 1866 "Invalid" 1865 "Invalid" 1864 "Invalid" 1863 "Invalid" 1862 "Invalid" 1861 "Invalid" 1860 "Invalid" 1859 "Invalid" 1858 "Invalid" 1857 "Invalid" 1856 "Invalid" 1855 "Invalid" 1854 "Invalid" 1853 "Invalid" 1852 "Invalid" 1851 "Invalid" 1850 "Invalid" 1849 "Invalid" 1848 "Invalid" 1847 "Invalid" 1846 "Invalid" 1845 "Invalid" 1844 "Invalid" 1843 "Invalid" 1842 "Invalid" 1841 "Invalid" 1840 "Invalid" 1839 "Invalid" 1838 "Invalid" 1837 "Invalid" 1836 "Invalid" 1835 "Invalid" 1834 "Invalid" 1833 "Invalid" 1832 "Invalid" 1831 "Invalid" 1830 "Invalid" 1829 "Invalid" 1828 "Invalid" 1827 "Invalid" 1826 "Invalid" 1825 "Invalid" 1824 "Invalid" 1823 "Invalid" 1822 "Invalid" 1821 "Invalid" 1820 "Invalid" 1819 "Invalid" 1818 "Invalid" 1817 "Invalid" 1816 "Invalid" 1815 "Invalid" 1814 "Invalid" 1813 "Invalid" 1812 "Invalid" 1811 "Invalid" 1810 "Invalid" 1809 "Invalid" 1808 "Invalid" 1807 "Invalid" 1806 "Invalid" 1805 "Invalid" 1804 "Invalid" 1803 "Invalid" 1802 "Invalid" 1801 "Invalid" ;
VAL_ 1062 BCU_CellTmp020_RM 255 "Invalid" 254 "Invalid" 253 "Invalid" 252 "Invalid" 251 "Invalid" 250 "Invalid" 249 "Invalid" 248 "Invalid" 247 "Invalid" 246 "Invalid" 245 "Invalid" 244 "Invalid" 243 "Invalid" 242 "Invalid" 241 "Invalid" 240 "Invalid" 239 "Invalid" 238 "Invalid" 237 "Invalid" 236 "Invalid" 235 "Invalid" 234 "Invalid" 233 "Invalid" 232 "Invalid" 231 "Invalid" 230 "Invalid" 229 "Invalid" 228 "Invalid" 227 "Invalid" 226 "Invalid" 225 "Invalid" 224 "Invalid" 223 "Invalid" 222 "Invalid" 221 "Invalid" 220 "Invalid" 219 "Invalid" 218 "Invalid" 217 "Invalid" 216 "Invalid" 215 "Invalid" 214 "Invalid" 213 "Invalid" 212 "Invalid" 211 "Invalid" 210 "Invalid" 209 "Invalid" 208 "Invalid" 207 "Invalid" 206 "Invalid" 205 "Invalid" 204 "Invalid" 203 "Invalid" 202 "Invalid" 201 "Invalid" 200 "Invalid" 199 "Invalid" 198 "Invalid" 197 "Invalid" 196 "Invalid" 195 "Invalid" 194 "Invalid" 193 "Invalid" 192 "Invalid" 191 "Invalid" 190 "Invalid" 189 "Invalid" 188 "Invalid" 187 "Invalid" 186 "Invalid" 185 "Invalid" 184 "Invalid" 183 "Invalid" 182 "Invalid" 181 "Invalid" 180 "Invalid" 179 "Invalid" 178 "Invalid" 177 "Invalid" 176 "Invalid" 175 "Invalid" 174 "Invalid" 173 "Invalid" 172 "Invalid" 171 "Invalid" 170 "Invalid" 169 "Invalid" 168 "Invalid" 167 "Invalid" 166 "Invalid" 165 "Invalid" 164 "Invalid" 163 "Invalid" 162 "Invalid" 161 "Invalid" ;
VAL_ 1062 BCU_CellTmp021_RM 255 "Invalid" 254 "Invalid" 253 "Invalid" 252 "Invalid" 251 "Invalid" 250 "Invalid" 249 "Invalid" 248 "Invalid" 247 "Invalid" 246 "Invalid" 245 "Invalid" 244 "Invalid" 243 "Invalid" 242 "Invalid" 241 "Invalid" 240 "Invalid" 239 "Invalid" 238 "Invalid" 237 "Invalid" 236 "Invalid" 235 "Invalid" 234 "Invalid" 233 "Invalid" 232 "Invalid" 231 "Invalid" 230 "Invalid" 229 "Invalid" 228 "Invalid" 227 "Invalid" 226 "Invalid" 225 "Invalid" 224 "Invalid" 223 "Invalid" 222 "Invalid" 221 "Invalid" 220 "Invalid" 219 "Invalid" 218 "Invalid" 217 "Invalid" 216 "Invalid" 215 "Invalid" 214 "Invalid" 213 "Invalid" 212 "Invalid" 211 "Invalid" 210 "Invalid" 209 "Invalid" 208 "Invalid" 207 "Invalid" 206 "Invalid" 205 "Invalid" 204 "Invalid" 203 "Invalid" 202 "Invalid" 201 "Invalid" 200 "Invalid" 199 "Invalid" 198 "Invalid" 197 "Invalid" 196 "Invalid" 195 "Invalid" 194 "Invalid" 193 "Invalid" 192 "Invalid" 191 "Invalid" 190 "Invalid" 189 "Invalid" 188 "Invalid" 187 "Invalid" 186 "Invalid" 185 "Invalid" 184 "Invalid" 183 "Invalid" 182 "Invalid" 181 "Invalid" 180 "Invalid" 179 "Invalid" 178 "Invalid" 177 "Invalid" 176 "Invalid" 175 "Invalid" 174 "Invalid" 173 "Invalid" 172 "Invalid" 171 "Invalid" 170 "Invalid" 169 "Invalid" 168 "Invalid" 167 "Invalid" 166 "Invalid" 165 "Invalid" 164 "Invalid" 163 "Invalid" 162 "Invalid" 161 "Invalid" ;
VAL_ 1062 BCU_CellTmp022_RM 255 "Invalid" 254 "Invalid" 253 "Invalid" 252 "Invalid" 251 "Invalid" 250 "Invalid" 249 "Invalid" 248 "Invalid" 247 "Invalid" 246 "Invalid" 245 "Invalid" 244 "Invalid" 243 "Invalid" 242 "Invalid" 241 "Invalid" 240 "Invalid" 239 "Invalid" 238 "Invalid" 237 "Invalid" 236 "Invalid" 235 "Invalid" 234 "Invalid" 233 "Invalid" 232 "Invalid" 231 "Invalid" 230 "Invalid" 229 "Invalid" 228 "Invalid" 227 "Invalid" 226 "Invalid" 225 "Invalid" 224 "Invalid" 223 "Invalid" 222 "Invalid" 221 "Invalid" 220 "Invalid" 219 "Invalid" 218 "Invalid" 217 "Invalid" 216 "Invalid" 215 "Invalid" 214 "Invalid" 213 "Invalid" 212 "Invalid" 211 "Invalid" 210 "Invalid" 209 "Invalid" 208 "Invalid" 207 "Invalid" 206 "Invalid" 205 "Invalid" 204 "Invalid" 203 "Invalid" 202 "Invalid" 201 "Invalid" 200 "Invalid" 199 "Invalid" 198 "Invalid" 197 "Invalid" 196 "Invalid" 195 "Invalid" 194 "Invalid" 193 "Invalid" 192 "Invalid" 191 "Invalid" 190 "Invalid" 189 "Invalid" 188 "Invalid" 187 "Invalid" 186 "Invalid" 185 "Invalid" 184 "Invalid" 183 "Invalid" 182 "Invalid" 181 "Invalid" 180 "Invalid" 179 "Invalid" 178 "Invalid" 177 "Invalid" 176 "Invalid" 175 "Invalid" 174 "Invalid" 173 "Invalid" 172 "Invalid" 171 "Invalid" 170 "Invalid" 169 "Invalid" 168 "Invalid" 167 "Invalid" 166 "Invalid" 165 "Invalid" 164 "Invalid" 163 "Invalid" 162 "Invalid" 161 "Invalid" ;
VAL_ 1062 BCU_CellTmp023_RM 255 "Invalid" 254 "Invalid" 253 "Invalid" 252 "Invalid" 251 "Invalid" 250 "Invalid" 249 "Invalid" 248 "Invalid" 247 "Invalid" 246 "Invalid" 245 "Invalid" 244 "Invalid" 243 "Invalid" 242 "Invalid" 241 "Invalid" 240 "Invalid" 239 "Invalid" 238 "Invalid" 237 "Invalid" 236 "Invalid" 235 "Invalid" 234 "Invalid" 233 "Invalid" 232 "Invalid" 231 "Invalid" 230 "Invalid" 229 "Invalid" 228 "Invalid" 227 "Invalid" 226 "Invalid" 225 "Invalid" 224 "Invalid" 223 "Invalid" 222 "Invalid" 221 "Invalid" 220 "Invalid" 219 "Invalid" 218 "Invalid" 217 "Invalid" 216 "Invalid" 215 "Invalid" 214 "Invalid" 213 "Invalid" 212 "Invalid" 211 "Invalid" 210 "Invalid" 209 "Invalid" 208 "Invalid" 207 "Invalid" 206 "Invalid" 205 "Invalid" 204 "Invalid" 203 "Invalid" 202 "Invalid" 201 "Invalid" 200 "Invalid" 199 "Invalid" 198 "Invalid" 197 "Invalid" 196 "Invalid" 195 "Invalid" 194 "Invalid" 193 "Invalid" 192 "Invalid" 191 "Invalid" 190 "Invalid" 189 "Invalid" 188 "Invalid" 187 "Invalid" 186 "Invalid" 185 "Invalid" 184 "Invalid" 183 "Invalid" 182 "Invalid" 181 "Invalid" 180 "Invalid" 179 "Invalid" 178 "Invalid" 177 "Invalid" 176 "Invalid" 175 "Invalid" 174 "Invalid" 173 "Invalid" 172 "Invalid" 171 "Invalid" 170 "Invalid" 169 "Invalid" 168 "Invalid" 167 "Invalid" 166 "Invalid" 165 "Invalid" 164 "Invalid" 163 "Invalid" 162 "Invalid" 161 "Invalid" ;
VAL_ 1062 BCU_CellTmp024_RM 255 "Invalid" 254 "Invalid" 253 "Invalid" 252 "Invalid" 251 "Invalid" 250 "Invalid" 249 "Invalid" 248 "Invalid" 247 "Invalid" 246 "Invalid" 245 "Invalid" 244 "Invalid" 243 "Invalid" 242 "Invalid" 241 "Invalid" 240 "Invalid" 239 "Invalid" 238 "Invalid" 237 "Invalid" 236 "Invalid" 235 "Invalid" 234 "Invalid" 233 "Invalid" 232 "Invalid" 231 "Invalid" 230 "Invalid" 229 "Invalid" 228 "Invalid" 227 "Invalid" 226 "Invalid" 225 "Invalid" 224 "Invalid" 223 "Invalid" 222 "Invalid" 221 "Invalid" 220 "Invalid" 219 "Invalid" 218 "Invalid" 217 "Invalid" 216 "Invalid" 215 "Invalid" 214 "Invalid" 213 "Invalid" 212 "Invalid" 211 "Invalid" 210 "Invalid" 209 "Invalid" 208 "Invalid" 207 "Invalid" 206 "Invalid" 205 "Invalid" 204 "Invalid" 203 "Invalid" 202 "Invalid" 201 "Invalid" 200 "Invalid" 199 "Invalid" 198 "Invalid" 197 "Invalid" 196 "Invalid" 195 "Invalid" 194 "Invalid" 193 "Invalid" 192 "Invalid" 191 "Invalid" 190 "Invalid" 189 "Invalid" 188 "Invalid" 187 "Invalid" 186 "Invalid" 185 "Invalid" 184 "Invalid" 183 "Invalid" 182 "Invalid" 181 "Invalid" 180 "Invalid" 179 "Invalid" 178 "Invalid" 177 "Invalid" 176 "Invalid" 175 "Invalid" 174 "Invalid" 173 "Invalid" 172 "Invalid" 171 "Invalid" 170 "Invalid" 169 "Invalid" 168 "Invalid" 167 "Invalid" 166 "Invalid" 165 "Invalid" 164 "Invalid" 163 "Invalid" 162 "Invalid" 161 "Invalid" ;
VAL_ 1062 BCU_CellTmp025_RM 255 "Invalid" 254 "Invalid" 253 "Invalid" 252 "Invalid" 251 "Invalid" 250 "Invalid" 249 "Invalid" 248 "Invalid" 247 "Invalid" 246 "Invalid" 245 "Invalid" 244 "Invalid" 243 "Invalid" 242 "Invalid" 241 "Invalid" 240 "Invalid" 239 "Invalid" 238 "Invalid" 237 "Invalid" 236 "Invalid" 235 "Invalid" 234 "Invalid" 233 "Invalid" 232 "Invalid" 231 "Invalid" 230 "Invalid" 229 "Invalid" 228 "Invalid" 227 "Invalid" 226 "Invalid" 225 "Invalid" 224 "Invalid" 223 "Invalid" 222 "Invalid" 221 "Invalid" 220 "Invalid" 219 "Invalid" 218 "Invalid" 217 "Invalid" 216 "Invalid" 215 "Invalid" 214 "Invalid" 213 "Invalid" 212 "Invalid" 211 "Invalid" 210 "Invalid" 209 "Invalid" 208 "Invalid" 207 "Invalid" 206 "Invalid" 205 "Invalid" 204 "Invalid" 203 "Invalid" 202 "Invalid" 201 "Invalid" 200 "Invalid" 199 "Invalid" 198 "Invalid" 197 "Invalid" 196 "Invalid" 195 "Invalid" 194 "Invalid" 193 "Invalid" 192 "Invalid" 191 "Invalid" 190 "Invalid" 189 "Invalid" 188 "Invalid" 187 "Invalid" 186 "Invalid" 185 "Invalid" 184 "Invalid" 183 "Invalid" 182 "Invalid" 181 "Invalid" 180 "Invalid" 179 "Invalid" 178 "Invalid" 177 "Invalid" 176 "Invalid" 175 "Invalid" 174 "Invalid" 173 "Invalid" 172 "Invalid" 171 "Invalid" 170 "Invalid" 169 "Invalid" 168 "Invalid" 167 "Invalid" 166 "Invalid" 165 "Invalid" 164 "Invalid" 163 "Invalid" 162 "Invalid" 161 "Invalid" ;
VAL_ 1063 BCU_CellTmp026_RM 255 "Invalid" 254 "Invalid" 253 "Invalid" 252 "Invalid" 251 "Invalid" 250 "Invalid" 249 "Invalid" 248 "Invalid" 247 "Invalid" 246 "Invalid" 245 "Invalid" 244 "Invalid" 243 "Invalid" 242 "Invalid" 241 "Invalid" 240 "Invalid" 239 "Invalid" 238 "Invalid" 237 "Invalid" 236 "Invalid" 235 "Invalid" 234 "Invalid" 233 "Invalid" 232 "Invalid" 231 "Invalid" 230 "Invalid" 229 "Invalid" 228 "Invalid" 227 "Invalid" 226 "Invalid" 225 "Invalid" 224 "Invalid" 223 "Invalid" 222 "Invalid" 221 "Invalid" 220 "Invalid" 219 "Invalid" 218 "Invalid" 217 "Invalid" 216 "Invalid" 215 "Invalid" 214 "Invalid" 213 "Invalid" 212 "Invalid" 211 "Invalid" 210 "Invalid" 209 "Invalid" 208 "Invalid" 207 "Invalid" 206 "Invalid" 205 "Invalid" 204 "Invalid" 203 "Invalid" 202 "Invalid" 201 "Invalid" 200 "Invalid" 199 "Invalid" 198 "Invalid" 197 "Invalid" 196 "Invalid" 195 "Invalid" 194 "Invalid" 193 "Invalid" 192 "Invalid" 191 "Invalid" 190 "Invalid" 189 "Invalid" 188 "Invalid" 187 "Invalid" 186 "Invalid" 185 "Invalid" 184 "Invalid" 183 "Invalid" 182 "Invalid" 181 "Invalid" 180 "Invalid" 179 "Invalid" 178 "Invalid" 177 "Invalid" 176 "Invalid" 175 "Invalid" 174 "Invalid" 173 "Invalid" 172 "Invalid" 171 "Invalid" 170 "Invalid" 169 "Invalid" 168 "Invalid" 167 "Invalid" 166 "Invalid" 165 "Invalid" 164 "Invalid" 163 "Invalid" 162 "Invalid" 161 "Invalid" ;
VAL_ 1063 BCU_CellTmp027_RM 255 "Invalid" 254 "Invalid" 253 "Invalid" 252 "Invalid" 251 "Invalid" 250 "Invalid" 249 "Invalid" 248 "Invalid" 247 "Invalid" 246 "Invalid" 245 "Invalid" 244 "Invalid" 243 "Invalid" 242 "Invalid" 241 "Invalid" 240 "Invalid" 239 "Invalid" 238 "Invalid" 237 "Invalid" 236 "Invalid" 235 "Invalid" 234 "Invalid" 233 "Invalid" 232 "Invalid" 231 "Invalid" 230 "Invalid" 229 "Invalid" 228 "Invalid" 227 "Invalid" 226 "Invalid" 225 "Invalid" 224 "Invalid" 223 "Invalid" 222 "Invalid" 221 "Invalid" 220 "Invalid" 219 "Invalid" 218 "Invalid" 217 "Invalid" 216 "Invalid" 215 "Invalid" 214 "Invalid" 213 "Invalid" 212 "Invalid" 211 "Invalid" 210 "Invalid" 209 "Invalid" 208 "Invalid" 207 "Invalid" 206 "Invalid" 205 "Invalid" 204 "Invalid" 203 "Invalid" 202 "Invalid" 201 "Invalid" 200 "Invalid" 199 "Invalid" 198 "Invalid" 197 "Invalid" 196 "Invalid" 195 "Invalid" 194 "Invalid" 193 "Invalid" 192 "Invalid" 191 "Invalid" 190 "Invalid" 189 "Invalid" 188 "Invalid" 187 "Invalid" 186 "Invalid" 185 "Invalid" 184 "Invalid" 183 "Invalid" 182 "Invalid" 181 "Invalid" 180 "Invalid" 179 "Invalid" 178 "Invalid" 177 "Invalid" 176 "Invalid" 175 "Invalid" 174 "Invalid" 173 "Invalid" 172 "Invalid" 171 "Invalid" 170 "Invalid" 169 "Invalid" 168 "Invalid" 167 "Invalid" 166 "Invalid" 165 "Invalid" 164 "Invalid" 163 "Invalid" 162 "Invalid" 161 "Invalid" ;
VAL_ 1063 BCU_CellTmp028_RM 255 "Invalid" 254 "Invalid" 253 "Invalid" 252 "Invalid" 251 "Invalid" 250 "Invalid" 249 "Invalid" 248 "Invalid" 247 "Invalid" 246 "Invalid" 245 "Invalid" 244 "Invalid" 243 "Invalid" 242 "Invalid" 241 "Invalid" 240 "Invalid" 239 "Invalid" 238 "Invalid" 237 "Invalid" 236 "Invalid" 235 "Invalid" 234 "Invalid" 233 "Invalid" 232 "Invalid" 231 "Invalid" 230 "Invalid" 229 "Invalid" 228 "Invalid" 227 "Invalid" 226 "Invalid" 225 "Invalid" 224 "Invalid" 223 "Invalid" 222 "Invalid" 221 "Invalid" 220 "Invalid" 219 "Invalid" 218 "Invalid" 217 "Invalid" 216 "Invalid" 215 "Invalid" 214 "Invalid" 213 "Invalid" 212 "Invalid" 211 "Invalid" 210 "Invalid" 209 "Invalid" 208 "Invalid" 207 "Invalid" 206 "Invalid" 205 "Invalid" 204 "Invalid" 203 "Invalid" 202 "Invalid" 201 "Invalid" 200 "Invalid" 199 "Invalid" 198 "Invalid" 197 "Invalid" 196 "Invalid" 195 "Invalid" 194 "Invalid" 193 "Invalid" 192 "Invalid" 191 "Invalid" 190 "Invalid" 189 "Invalid" 188 "Invalid" 187 "Invalid" 186 "Invalid" 185 "Invalid" 184 "Invalid" 183 "Invalid" 182 "Invalid" 181 "Invalid" 180 "Invalid" 179 "Invalid" 178 "Invalid" 177 "Invalid" 176 "Invalid" 175 "Invalid" 174 "Invalid" 173 "Invalid" 172 "Invalid" 171 "Invalid" 170 "Invalid" 169 "Invalid" 168 "Invalid" 167 "Invalid" 166 "Invalid" 165 "Invalid" 164 "Invalid" 163 "Invalid" 162 "Invalid" 161 "Invalid" ;
VAL_ 1063 BCU_CellTmp029_RM 255 "Invalid" 254 "Invalid" 253 "Invalid" 252 "Invalid" 251 "Invalid" 250 "Invalid" 249 "Invalid" 248 "Invalid" 247 "Invalid" 246 "Invalid" 245 "Invalid" 244 "Invalid" 243 "Invalid" 242 "Invalid" 241 "Invalid" 240 "Invalid" 239 "Invalid" 238 "Invalid" 237 "Invalid" 236 "Invalid" 235 "Invalid" 234 "Invalid" 233 "Invalid" 232 "Invalid" 231 "Invalid" 230 "Invalid" 229 "Invalid" 228 "Invalid" 227 "Invalid" 226 "Invalid" 225 "Invalid" 224 "Invalid" 223 "Invalid" 222 "Invalid" 221 "Invalid" 220 "Invalid" 219 "Invalid" 218 "Invalid" 217 "Invalid" 216 "Invalid" 215 "Invalid" 214 "Invalid" 213 "Invalid" 212 "Invalid" 211 "Invalid" 210 "Invalid" 209 "Invalid" 208 "Invalid" 207 "Invalid" 206 "Invalid" 205 "Invalid" 204 "Invalid" 203 "Invalid" 202 "Invalid" 201 "Invalid" 200 "Invalid" 199 "Invalid" 198 "Invalid" 197 "Invalid" 196 "Invalid" 195 "Invalid" 194 "Invalid" 193 "Invalid" 192 "Invalid" 191 "Invalid" 190 "Invalid" 189 "Invalid" 188 "Invalid" 187 "Invalid" 186 "Invalid" 185 "Invalid" 184 "Invalid" 183 "Invalid" 182 "Invalid" 181 "Invalid" 180 "Invalid" 179 "Invalid" 178 "Invalid" 177 "Invalid" 176 "Invalid" 175 "Invalid" 174 "Invalid" 173 "Invalid" 172 "Invalid" 171 "Invalid" 170 "Invalid" 169 "Invalid" 168 "Invalid" 167 "Invalid" 166 "Invalid" 165 "Invalid" 164 "Invalid" 163 "Invalid" 162 "Invalid" 161 "Invalid" ;
VAL_ 1063 BCU_CellTmp030_RM 255 "Invalid" 254 "Invalid" 253 "Invalid" 252 "Invalid" 251 "Invalid" 250 "Invalid" 249 "Invalid" 248 "Invalid" 247 "Invalid" 246 "Invalid" 245 "Invalid" 244 "Invalid" 243 "Invalid" 242 "Invalid" 241 "Invalid" 240 "Invalid" 239 "Invalid" 238 "Invalid" 237 "Invalid" 236 "Invalid" 235 "Invalid" 234 "Invalid" 233 "Invalid" 232 "Invalid" 231 "Invalid" 230 "Invalid" 229 "Invalid" 228 "Invalid" 227 "Invalid" 226 "Invalid" 225 "Invalid" 224 "Invalid" 223 "Invalid" 222 "Invalid" 221 "Invalid" 220 "Invalid" 219 "Invalid" 218 "Invalid" 217 "Invalid" 216 "Invalid" 215 "Invalid" 214 "Invalid" 213 "Invalid" 212 "Invalid" 211 "Invalid" 210 "Invalid" 209 "Invalid" 208 "Invalid" 207 "Invalid" 206 "Invalid" 205 "Invalid" 204 "Invalid" 203 "Invalid" 202 "Invalid" 201 "Invalid" 200 "Invalid" 199 "Invalid" 198 "Invalid" 197 "Invalid" 196 "Invalid" 195 "Invalid" 194 "Invalid" 193 "Invalid" 192 "Invalid" 191 "Invalid" 190 "Invalid" 189 "Invalid" 188 "Invalid" 187 "Invalid" 186 "Invalid" 185 "Invalid" 184 "Invalid" 183 "Invalid" 182 "Invalid" 181 "Invalid" 180 "Invalid" 179 "Invalid" 178 "Invalid" 177 "Invalid" 176 "Invalid" 175 "Invalid" 174 "Invalid" 173 "Invalid" 172 "Invalid" 171 "Invalid" 170 "Invalid" 169 "Invalid" 168 "Invalid" 167 "Invalid" 166 "Invalid" 165 "Invalid" 164 "Invalid" 163 "Invalid" 162 "Invalid" 161 "Invalid" ;
VAL_ 1063 BCU_CellTmp031_RM 255 "Invalid" 254 "Invalid" 253 "Invalid" 252 "Invalid" 251 "Invalid" 250 "Invalid" 249 "Invalid" 248 "Invalid" 247 "Invalid" 246 "Invalid" 245 "Invalid" 244 "Invalid" 243 "Invalid" 242 "Invalid" 241 "Invalid" 240 "Invalid" 239 "Invalid" 238 "Invalid" 237 "Invalid" 236 "Invalid" 235 "Invalid" 234 "Invalid" 233 "Invalid" 232 "Invalid" 231 "Invalid" 230 "Invalid" 229 "Invalid" 228 "Invalid" 227 "Invalid" 226 "Invalid" 225 "Invalid" 224 "Invalid" 223 "Invalid" 222 "Invalid" 221 "Invalid" 220 "Invalid" 219 "Invalid" 218 "Invalid" 217 "Invalid" 216 "Invalid" 215 "Invalid" 214 "Invalid" 213 "Invalid" 212 "Invalid" 211 "Invalid" 210 "Invalid" 209 "Invalid" 208 "Invalid" 207 "Invalid" 206 "Invalid" 205 "Invalid" 204 "Invalid" 203 "Invalid" 202 "Invalid" 201 "Invalid" 200 "Invalid" 199 "Invalid" 198 "Invalid" 197 "Invalid" 196 "Invalid" 195 "Invalid" 194 "Invalid" 193 "Invalid" 192 "Invalid" 191 "Invalid" 190 "Invalid" 189 "Invalid" 188 "Invalid" 187 "Invalid" 186 "Invalid" 185 "Invalid" 184 "Invalid" 183 "Invalid" 182 "Invalid" 181 "Invalid" 180 "Invalid" 179 "Invalid" 178 "Invalid" 177 "Invalid" 176 "Invalid" 175 "Invalid" 174 "Invalid" 173 "Invalid" 172 "Invalid" 171 "Invalid" 170 "Invalid" 169 "Invalid" 168 "Invalid" 167 "Invalid" 166 "Invalid" 165 "Invalid" 164 "Invalid" 163 "Invalid" 162 "Invalid" 161 "Invalid" ;
VAL_ 1063 BCU_CellTmp032_RM 255 "Invalid" 254 "Invalid" 253 "Invalid" 252 "Invalid" 251 "Invalid" 250 "Invalid" 249 "Invalid" 248 "Invalid" 247 "Invalid" 246 "Invalid" 245 "Invalid" 244 "Invalid" 243 "Invalid" 242 "Invalid" 241 "Invalid" 240 "Invalid" 239 "Invalid" 238 "Invalid" 237 "Invalid" 236 "Invalid" 235 "Invalid" 234 "Invalid" 233 "Invalid" 232 "Invalid" 231 "Invalid" 230 "Invalid" 229 "Invalid" 228 "Invalid" 227 "Invalid" 226 "Invalid" 225 "Invalid" 224 "Invalid" 223 "Invalid" 222 "Invalid" 221 "Invalid" 220 "Invalid" 219 "Invalid" 218 "Invalid" 217 "Invalid" 216 "Invalid" 215 "Invalid" 214 "Invalid" 213 "Invalid" 212 "Invalid" 211 "Invalid" 210 "Invalid" 209 "Invalid" 208 "Invalid" 207 "Invalid" 206 "Invalid" 205 "Invalid" 204 "Invalid" 203 "Invalid" 202 "Invalid" 201 "Invalid" 200 "Invalid" 199 "Invalid" 198 "Invalid" 197 "Invalid" 196 "Invalid" 195 "Invalid" 194 "Invalid" 193 "Invalid" 192 "Invalid" 191 "Invalid" 190 "Invalid" 189 "Invalid" 188 "Invalid" 187 "Invalid" 186 "Invalid" 185 "Invalid" 184 "Invalid" 183 "Invalid" 182 "Invalid" 181 "Invalid" 180 "Invalid" 179 "Invalid" 178 "Invalid" 177 "Invalid" 176 "Invalid" 175 "Invalid" 174 "Invalid" 173 "Invalid" 172 "Invalid" 171 "Invalid" 170 "Invalid" 169 "Invalid" 168 "Invalid" 167 "Invalid" 166 "Invalid" 165 "Invalid" 164 "Invalid" 163 "Invalid" 162 "Invalid" 161 "Invalid" ;
VAL_ 1063 BCU_CellTmp033_RM 255 "Invalid" 254 "Invalid" 253 "Invalid" 252 "Invalid" 251 "Invalid" 250 "Invalid" 249 "Invalid" 248 "Invalid" 247 "Invalid" 246 "Invalid" 245 "Invalid" 244 "Invalid" 243 "Invalid" 242 "Invalid" 241 "Invalid" 240 "Invalid" 239 "Invalid" 238 "Invalid" 237 "Invalid" 236 "Invalid" 235 "Invalid" 234 "Invalid" 233 "Invalid" 232 "Invalid" 231 "Invalid" 230 "Invalid" 229 "Invalid" 228 "Invalid" 227 "Invalid" 226 "Invalid" 225 "Invalid" 224 "Invalid" 223 "Invalid" 222 "Invalid" 221 "Invalid" 220 "Invalid" 219 "Invalid" 218 "Invalid" 217 "Invalid" 216 "Invalid" 215 "Invalid" 214 "Invalid" 213 "Invalid" 212 "Invalid" 211 "Invalid" 210 "Invalid" 209 "Invalid" 208 "Invalid" 207 "Invalid" 206 "Invalid" 205 "Invalid" 204 "Invalid" 203 "Invalid" 202 "Invalid" 201 "Invalid" 200 "Invalid" 199 "Invalid" 198 "Invalid" 197 "Invalid" 196 "Invalid" 195 "Invalid" 194 "Invalid" 193 "Invalid" 192 "Invalid" 191 "Invalid" 190 "Invalid" 189 "Invalid" 188 "Invalid" 187 "Invalid" 186 "Invalid" 185 "Invalid" 184 "Invalid" 183 "Invalid" 182 "Invalid" 181 "Invalid" 180 "Invalid" 179 "Invalid" 178 "Invalid" 177 "Invalid" 176 "Invalid" 175 "Invalid" 174 "Invalid" 173 "Invalid" 172 "Invalid" 171 "Invalid" 170 "Invalid" 169 "Invalid" 168 "Invalid" 167 "Invalid" 166 "Invalid" 165 "Invalid" 164 "Invalid" 163 "Invalid" 162 "Invalid" 161 "Invalid" ;
VAL_ 1064 BCU_CellTmp034_RM 255 "Invalid" 254 "Invalid" 253 "Invalid" 252 "Invalid" 251 "Invalid" 250 "Invalid" 249 "Invalid" 248 "Invalid" 247 "Invalid" 246 "Invalid" 245 "Invalid" 244 "Invalid" 243 "Invalid" 242 "Invalid" 241 "Invalid" 240 "Invalid" 239 "Invalid" 238 "Invalid" 237 "Invalid" 236 "Invalid" 235 "Invalid" 234 "Invalid" 233 "Invalid" 232 "Invalid" 231 "Invalid" 230 "Invalid" 229 "Invalid" 228 "Invalid" 227 "Invalid" 226 "Invalid" 225 "Invalid" 224 "Invalid" 223 "Invalid" 222 "Invalid" 221 "Invalid" 220 "Invalid" 219 "Invalid" 218 "Invalid" 217 "Invalid" 216 "Invalid" 215 "Invalid" 214 "Invalid" 213 "Invalid" 212 "Invalid" 211 "Invalid" 210 "Invalid" 209 "Invalid" 208 "Invalid" 207 "Invalid" 206 "Invalid" 205 "Invalid" 204 "Invalid" 203 "Invalid" 202 "Invalid" 201 "Invalid" 200 "Invalid" 199 "Invalid" 198 "Invalid" 197 "Invalid" 196 "Invalid" 195 "Invalid" 194 "Invalid" 193 "Invalid" 192 "Invalid" 191 "Invalid" 190 "Invalid" 189 "Invalid" 188 "Invalid" 187 "Invalid" 186 "Invalid" 185 "Invalid" 184 "Invalid" 183 "Invalid" 182 "Invalid" 181 "Invalid" 180 "Invalid" 179 "Invalid" 178 "Invalid" 177 "Invalid" 176 "Invalid" 175 "Invalid" 174 "Invalid" 173 "Invalid" 172 "Invalid" 171 "Invalid" 170 "Invalid" 169 "Invalid" 168 "Invalid" 167 "Invalid" 166 "Invalid" 165 "Invalid" 164 "Invalid" 163 "Invalid" 162 "Invalid" 161 "Invalid" ;
VAL_ 1064 BCU_CellTmp035_RM 255 "Invalid" 254 "Invalid" 253 "Invalid" 252 "Invalid" 251 "Invalid" 250 "Invalid" 249 "Invalid" 248 "Invalid" 247 "Invalid" 246 "Invalid" 245 "Invalid" 244 "Invalid" 243 "Invalid" 242 "Invalid" 241 "Invalid" 240 "Invalid" 239 "Invalid" 238 "Invalid" 237 "Invalid" 236 "Invalid" 235 "Invalid" 234 "Invalid" 233 "Invalid" 232 "Invalid" 231 "Invalid" 230 "Invalid" 229 "Invalid" 228 "Invalid" 227 "Invalid" 226 "Invalid" 225 "Invalid" 224 "Invalid" 223 "Invalid" 222 "Invalid" 221 "Invalid" 220 "Invalid" 219 "Invalid" 218 "Invalid" 217 "Invalid" 216 "Invalid" 215 "Invalid" 214 "Invalid" 213 "Invalid" 212 "Invalid" 211 "Invalid" 210 "Invalid" 209 "Invalid" 208 "Invalid" 207 "Invalid" 206 "Invalid" 205 "Invalid" 204 "Invalid" 203 "Invalid" 202 "Invalid" 201 "Invalid" 200 "Invalid" 199 "Invalid" 198 "Invalid" 197 "Invalid" 196 "Invalid" 195 "Invalid" 194 "Invalid" 193 "Invalid" 192 "Invalid" 191 "Invalid" 190 "Invalid" 189 "Invalid" 188 "Invalid" 187 "Invalid" 186 "Invalid" 185 "Invalid" 184 "Invalid" 183 "Invalid" 182 "Invalid" 181 "Invalid" 180 "Invalid" 179 "Invalid" 178 "Invalid" 177 "Invalid" 176 "Invalid" 175 "Invalid" 174 "Invalid" 173 "Invalid" 172 "Invalid" 171 "Invalid" 170 "Invalid" 169 "Invalid" 168 "Invalid" 167 "Invalid" 166 "Invalid" 165 "Invalid" 164 "Invalid" 163 "Invalid" 162 "Invalid" 161 "Invalid" ;
VAL_ 1064 BCU_CellTmp036_RM 255 "Invalid" 254 "Invalid" 253 "Invalid" 252 "Invalid" 251 "Invalid" 250 "Invalid" 249 "Invalid" 248 "Invalid" 247 "Invalid" 246 "Invalid" 245 "Invalid" 244 "Invalid" 243 "Invalid" 242 "Invalid" 241 "Invalid" 240 "Invalid" 239 "Invalid" 238 "Invalid" 237 "Invalid" 236 "Invalid" 235 "Invalid" 234 "Invalid" 233 "Invalid" 232 "Invalid" 231 "Invalid" 230 "Invalid" 229 "Invalid" 228 "Invalid" 227 "Invalid" 226 "Invalid" 225 "Invalid" 224 "Invalid" 223 "Invalid" 222 "Invalid" 221 "Invalid" 220 "Invalid" 219 "Invalid" 218 "Invalid" 217 "Invalid" 216 "Invalid" 215 "Invalid" 214 "Invalid" 213 "Invalid" 212 "Invalid" 211 "Invalid" 210 "Invalid" 209 "Invalid" 208 "Invalid" 207 "Invalid" 206 "Invalid" 205 "Invalid" 204 "Invalid" 203 "Invalid" 202 "Invalid" 201 "Invalid" 200 "Invalid" 199 "Invalid" 198 "Invalid" 197 "Invalid" 196 "Invalid" 195 "Invalid" 194 "Invalid" 193 "Invalid" 192 "Invalid" 191 "Invalid" 190 "Invalid" 189 "Invalid" 188 "Invalid" 187 "Invalid" 186 "Invalid" 185 "Invalid" 184 "Invalid" 183 "Invalid" 182 "Invalid" 181 "Invalid" 180 "Invalid" 179 "Invalid" 178 "Invalid" 177 "Invalid" 176 "Invalid" 175 "Invalid" 174 "Invalid" 173 "Invalid" 172 "Invalid" 171 "Invalid" 170 "Invalid" 169 "Invalid" 168 "Invalid" 167 "Invalid" 166 "Invalid" 165 "Invalid" 164 "Invalid" 163 "Invalid" 162 "Invalid" 161 "Invalid" ;
VAL_ 1064 BCU_CellTmp037_RM 255 "Invalid" 254 "Invalid" 253 "Invalid" 252 "Invalid" 251 "Invalid" 250 "Invalid" 249 "Invalid" 248 "Invalid" 247 "Invalid" 246 "Invalid" 245 "Invalid" 244 "Invalid" 243 "Invalid" 242 "Invalid" 241 "Invalid" 240 "Invalid" 239 "Invalid" 238 "Invalid" 237 "Invalid" 236 "Invalid" 235 "Invalid" 234 "Invalid" 233 "Invalid" 232 "Invalid" 231 "Invalid" 230 "Invalid" 229 "Invalid" 228 "Invalid" 227 "Invalid" 226 "Invalid" 225 "Invalid" 224 "Invalid" 223 "Invalid" 222 "Invalid" 221 "Invalid" 220 "Invalid" 219 "Invalid" 218 "Invalid" 217 "Invalid" 216 "Invalid" 215 "Invalid" 214 "Invalid" 213 "Invalid" 212 "Invalid" 211 "Invalid" 210 "Invalid" 209 "Invalid" 208 "Invalid" 207 "Invalid" 206 "Invalid" 205 "Invalid" 204 "Invalid" 203 "Invalid" 202 "Invalid" 201 "Invalid" 200 "Invalid" 199 "Invalid" 198 "Invalid" 197 "Invalid" 196 "Invalid" 195 "Invalid" 194 "Invalid" 193 "Invalid" 192 "Invalid" 191 "Invalid" 190 "Invalid" 189 "Invalid" 188 "Invalid" 187 "Invalid" 186 "Invalid" 185 "Invalid" 184 "Invalid" 183 "Invalid" 182 "Invalid" 181 "Invalid" 180 "Invalid" 179 "Invalid" 178 "Invalid" 177 "Invalid" 176 "Invalid" 175 "Invalid" 174 "Invalid" 173 "Invalid" 172 "Invalid" 171 "Invalid" 170 "Invalid" 169 "Invalid" 168 "Invalid" 167 "Invalid" 166 "Invalid" 165 "Invalid" 164 "Invalid" 163 "Invalid" 162 "Invalid" 161 "Invalid" ;
VAL_ 1064 BCU_CellTmp038_RM 255 "Invalid" 254 "Invalid" 253 "Invalid" 252 "Invalid" 251 "Invalid" 250 "Invalid" 249 "Invalid" 248 "Invalid" 247 "Invalid" 246 "Invalid" 245 "Invalid" 244 "Invalid" 243 "Invalid" 242 "Invalid" 241 "Invalid" 240 "Invalid" 239 "Invalid" 238 "Invalid" 237 "Invalid" 236 "Invalid" 235 "Invalid" 234 "Invalid" 233 "Invalid" 232 "Invalid" 231 "Invalid" 230 "Invalid" 229 "Invalid" 228 "Invalid" 227 "Invalid" 226 "Invalid" 225 "Invalid" 224 "Invalid" 223 "Invalid" 222 "Invalid" 221 "Invalid" 220 "Invalid" 219 "Invalid" 218 "Invalid" 217 "Invalid" 216 "Invalid" 215 "Invalid" 214 "Invalid" 213 "Invalid" 212 "Invalid" 211 "Invalid" 210 "Invalid" 209 "Invalid" 208 "Invalid" 207 "Invalid" 206 "Invalid" 205 "Invalid" 204 "Invalid" 203 "Invalid" 202 "Invalid" 201 "Invalid" 200 "Invalid" 199 "Invalid" 198 "Invalid" 197 "Invalid" 196 "Invalid" 195 "Invalid" 194 "Invalid" 193 "Invalid" 192 "Invalid" 191 "Invalid" 190 "Invalid" 189 "Invalid" 188 "Invalid" 187 "Invalid" 186 "Invalid" 185 "Invalid" 184 "Invalid" 183 "Invalid" 182 "Invalid" 181 "Invalid" 180 "Invalid" 179 "Invalid" 178 "Invalid" 177 "Invalid" 176 "Invalid" 175 "Invalid" 174 "Invalid" 173 "Invalid" 172 "Invalid" 171 "Invalid" 170 "Invalid" 169 "Invalid" 168 "Invalid" 167 "Invalid" 166 "Invalid" 165 "Invalid" 164 "Invalid" 163 "Invalid" 162 "Invalid" 161 "Invalid" ;
VAL_ 1064 BCU_CellTmp039_RM 255 "Invalid" 254 "Invalid" 253 "Invalid" 252 "Invalid" 251 "Invalid" 250 "Invalid" 249 "Invalid" 248 "Invalid" 247 "Invalid" 246 "Invalid" 245 "Invalid" 244 "Invalid" 243 "Invalid" 242 "Invalid" 241 "Invalid" 240 "Invalid" 239 "Invalid" 238 "Invalid" 237 "Invalid" 236 "Invalid" 235 "Invalid" 234 "Invalid" 233 "Invalid" 232 "Invalid" 231 "Invalid" 230 "Invalid" 229 "Invalid" 228 "Invalid" 227 "Invalid" 226 "Invalid" 225 "Invalid" 224 "Invalid" 223 "Invalid" 222 "Invalid" 221 "Invalid" 220 "Invalid" 219 "Invalid" 218 "Invalid" 217 "Invalid" 216 "Invalid" 215 "Invalid" 214 "Invalid" 213 "Invalid" 212 "Invalid" 211 "Invalid" 210 "Invalid" 209 "Invalid" 208 "Invalid" 207 "Invalid" 206 "Invalid" 205 "Invalid" 204 "Invalid" 203 "Invalid" 202 "Invalid" 201 "Invalid" 200 "Invalid" 199 "Invalid" 198 "Invalid" 197 "Invalid" 196 "Invalid" 195 "Invalid" 194 "Invalid" 193 "Invalid" 192 "Invalid" 191 "Invalid" 190 "Invalid" 189 "Invalid" 188 "Invalid" 187 "Invalid" 186 "Invalid" 185 "Invalid" 184 "Invalid" 183 "Invalid" 182 "Invalid" 181 "Invalid" 180 "Invalid" 179 "Invalid" 178 "Invalid" 177 "Invalid" 176 "Invalid" 175 "Invalid" 174 "Invalid" 173 "Invalid" 172 "Invalid" 171 "Invalid" 170 "Invalid" 169 "Invalid" 168 "Invalid" 167 "Invalid" 166 "Invalid" 165 "Invalid" 164 "Invalid" 163 "Invalid" 162 "Invalid" 161 "Invalid" ;
VAL_ 1064 BCU_CellTmp040_RM 255 "Invalid" 254 "Invalid" 253 "Invalid" 252 "Invalid" 251 "Invalid" 250 "Invalid" 249 "Invalid" 248 "Invalid" 247 "Invalid" 246 "Invalid" 245 "Invalid" 244 "Invalid" 243 "Invalid" 242 "Invalid" 241 "Invalid" 240 "Invalid" 239 "Invalid" 238 "Invalid" 237 "Invalid" 236 "Invalid" 235 "Invalid" 234 "Invalid" 233 "Invalid" 232 "Invalid" 231 "Invalid" 230 "Invalid" 229 "Invalid" 228 "Invalid" 227 "Invalid" 226 "Invalid" 225 "Invalid" 224 "Invalid" 223 "Invalid" 222 "Invalid" 221 "Invalid" 220 "Invalid" 219 "Invalid" 218 "Invalid" 217 "Invalid" 216 "Invalid" 215 "Invalid" 214 "Invalid" 213 "Invalid" 212 "Invalid" 211 "Invalid" 210 "Invalid" 209 "Invalid" 208 "Invalid" 207 "Invalid" 206 "Invalid" 205 "Invalid" 204 "Invalid" 203 "Invalid" 202 "Invalid" 201 "Invalid" 200 "Invalid" 199 "Invalid" 198 "Invalid" 197 "Invalid" 196 "Invalid" 195 "Invalid" 194 "Invalid" 193 "Invalid" 192 "Invalid" 191 "Invalid" 190 "Invalid" 189 "Invalid" 188 "Invalid" 187 "Invalid" 186 "Invalid" 185 "Invalid" 184 "Invalid" 183 "Invalid" 182 "Invalid" 181 "Invalid" 180 "Invalid" 179 "Invalid" 178 "Invalid" 177 "Invalid" 176 "Invalid" 175 "Invalid" 174 "Invalid" 173 "Invalid" 172 "Invalid" 171 "Invalid" 170 "Invalid" 169 "Invalid" 168 "Invalid" 167 "Invalid" 166 "Invalid" 165 "Invalid" 164 "Invalid" 163 "Invalid" 162 "Invalid" 161 "Invalid" ;
VAL_ 1064 BCU_CellTmp041_RM 255 "Invalid" 254 "Invalid" 253 "Invalid" 252 "Invalid" 251 "Invalid" 250 "Invalid" 249 "Invalid" 248 "Invalid" 247 "Invalid" 246 "Invalid" 245 "Invalid" 244 "Invalid" 243 "Invalid" 242 "Invalid" 241 "Invalid" 240 "Invalid" 239 "Invalid" 238 "Invalid" 237 "Invalid" 236 "Invalid" 235 "Invalid" 234 "Invalid" 233 "Invalid" 232 "Invalid" 231 "Invalid" 230 "Invalid" 229 "Invalid" 228 "Invalid" 227 "Invalid" 226 "Invalid" 225 "Invalid" 224 "Invalid" 223 "Invalid" 222 "Invalid" 221 "Invalid" 220 "Invalid" 219 "Invalid" 218 "Invalid" 217 "Invalid" 216 "Invalid" 215 "Invalid" 214 "Invalid" 213 "Invalid" 212 "Invalid" 211 "Invalid" 210 "Invalid" 209 "Invalid" 208 "Invalid" 207 "Invalid" 206 "Invalid" 205 "Invalid" 204 "Invalid" 203 "Invalid" 202 "Invalid" 201 "Invalid" 200 "Invalid" 199 "Invalid" 198 "Invalid" 197 "Invalid" 196 "Invalid" 195 "Invalid" 194 "Invalid" 193 "Invalid" 192 "Invalid" 191 "Invalid" 190 "Invalid" 189 "Invalid" 188 "Invalid" 187 "Invalid" 186 "Invalid" 185 "Invalid" 184 "Invalid" 183 "Invalid" 182 "Invalid" 181 "Invalid" 180 "Invalid" 179 "Invalid" 178 "Invalid" 177 "Invalid" 176 "Invalid" 175 "Invalid" 174 "Invalid" 173 "Invalid" 172 "Invalid" 171 "Invalid" 170 "Invalid" 169 "Invalid" 168 "Invalid" 167 "Invalid" 166 "Invalid" 165 "Invalid" 164 "Invalid" 163 "Invalid" 162 "Invalid" 161 "Invalid" ;
VAL_ 1065 BCU_CellTmp042_RM 255 "Invalid" 254 "Invalid" 253 "Invalid" 252 "Invalid" 251 "Invalid" 250 "Invalid" 249 "Invalid" 248 "Invalid" 247 "Invalid" 246 "Invalid" 245 "Invalid" 244 "Invalid" 243 "Invalid" 242 "Invalid" 241 "Invalid" 240 "Invalid" 239 "Invalid" 238 "Invalid" 237 "Invalid" 236 "Invalid" 235 "Invalid" 234 "Invalid" 233 "Invalid" 232 "Invalid" 231 "Invalid" 230 "Invalid" 229 "Invalid" 228 "Invalid" 227 "Invalid" 226 "Invalid" 225 "Invalid" 224 "Invalid" 223 "Invalid" 222 "Invalid" 221 "Invalid" 220 "Invalid" 219 "Invalid" 218 "Invalid" 217 "Invalid" 216 "Invalid" 215 "Invalid" 214 "Invalid" 213 "Invalid" 212 "Invalid" 211 "Invalid" 210 "Invalid" 209 "Invalid" 208 "Invalid" 207 "Invalid" 206 "Invalid" 205 "Invalid" 204 "Invalid" 203 "Invalid" 202 "Invalid" 201 "Invalid" 200 "Invalid" 199 "Invalid" 198 "Invalid" 197 "Invalid" 196 "Invalid" 195 "Invalid" 194 "Invalid" 193 "Invalid" 192 "Invalid" 191 "Invalid" 190 "Invalid" 189 "Invalid" 188 "Invalid" 187 "Invalid" 186 "Invalid" 185 "Invalid" 184 "Invalid" 183 "Invalid" 182 "Invalid" 181 "Invalid" 180 "Invalid" 179 "Invalid" 178 "Invalid" 177 "Invalid" 176 "Invalid" 175 "Invalid" 174 "Invalid" 173 "Invalid" 172 "Invalid" 171 "Invalid" 170 "Invalid" 169 "Invalid" 168 "Invalid" 167 "Invalid" 166 "Invalid" 165 "Invalid" 164 "Invalid" 163 "Invalid" 162 "Invalid" 161 "Invalid" ;
VAL_ 1065 BCU_CellTmp043_RM 255 "Invalid" 254 "Invalid" 253 "Invalid" 252 "Invalid" 251 "Invalid" 250 "Invalid" 249 "Invalid" 248 "Invalid" 247 "Invalid" 246 "Invalid" 245 "Invalid" 244 "Invalid" 243 "Invalid" 242 "Invalid" 241 "Invalid" 240 "Invalid" 239 "Invalid" 238 "Invalid" 237 "Invalid" 236 "Invalid" 235 "Invalid" 234 "Invalid" 233 "Invalid" 232 "Invalid" 231 "Invalid" 230 "Invalid" 229 "Invalid" 228 "Invalid" 227 "Invalid" 226 "Invalid" 225 "Invalid" 224 "Invalid" 223 "Invalid" 222 "Invalid" 221 "Invalid" 220 "Invalid" 219 "Invalid" 218 "Invalid" 217 "Invalid" 216 "Invalid" 215 "Invalid" 214 "Invalid" 213 "Invalid" 212 "Invalid" 211 "Invalid" 210 "Invalid" 209 "Invalid" 208 "Invalid" 207 "Invalid" 206 "Invalid" 205 "Invalid" 204 "Invalid" 203 "Invalid" 202 "Invalid" 201 "Invalid" 200 "Invalid" 199 "Invalid" 198 "Invalid" 197 "Invalid" 196 "Invalid" 195 "Invalid" 194 "Invalid" 193 "Invalid" 192 "Invalid" 191 "Invalid" 190 "Invalid" 189 "Invalid" 188 "Invalid" 187 "Invalid" 186 "Invalid" 185 "Invalid" 184 "Invalid" 183 "Invalid" 182 "Invalid" 181 "Invalid" 180 "Invalid" 179 "Invalid" 178 "Invalid" 177 "Invalid" 176 "Invalid" 175 "Invalid" 174 "Invalid" 173 "Invalid" 172 "Invalid" 171 "Invalid" 170 "Invalid" 169 "Invalid" 168 "Invalid" 167 "Invalid" 166 "Invalid" 165 "Invalid" 164 "Invalid" 163 "Invalid" 162 "Invalid" 161 "Invalid" ;
VAL_ 1065 BCU_CellTmp044_RM 255 "Invalid" 254 "Invalid" 253 "Invalid" 252 "Invalid" 251 "Invalid" 250 "Invalid" 249 "Invalid" 248 "Invalid" 247 "Invalid" 246 "Invalid" 245 "Invalid" 244 "Invalid" 243 "Invalid" 242 "Invalid" 241 "Invalid" 240 "Invalid" 239 "Invalid" 238 "Invalid" 237 "Invalid" 236 "Invalid" 235 "Invalid" 234 "Invalid" 233 "Invalid" 232 "Invalid" 231 "Invalid" 230 "Invalid" 229 "Invalid" 228 "Invalid" 227 "Invalid" 226 "Invalid" 225 "Invalid" 224 "Invalid" 223 "Invalid" 222 "Invalid" 221 "Invalid" 220 "Invalid" 219 "Invalid" 218 "Invalid" 217 "Invalid" 216 "Invalid" 215 "Invalid" 214 "Invalid" 213 "Invalid" 212 "Invalid" 211 "Invalid" 210 "Invalid" 209 "Invalid" 208 "Invalid" 207 "Invalid" 206 "Invalid" 205 "Invalid" 204 "Invalid" 203 "Invalid" 202 "Invalid" 201 "Invalid" 200 "Invalid" 199 "Invalid" 198 "Invalid" 197 "Invalid" 196 "Invalid" 195 "Invalid" 194 "Invalid" 193 "Invalid" 192 "Invalid" 191 "Invalid" 190 "Invalid" 189 "Invalid" 188 "Invalid" 187 "Invalid" 186 "Invalid" 185 "Invalid" 184 "Invalid" 183 "Invalid" 182 "Invalid" 181 "Invalid" 180 "Invalid" 179 "Invalid" 178 "Invalid" 177 "Invalid" 176 "Invalid" 175 "Invalid" 174 "Invalid" 173 "Invalid" 172 "Invalid" 171 "Invalid" 170 "Invalid" 169 "Invalid" 168 "Invalid" 167 "Invalid" 166 "Invalid" 165 "Invalid" 164 "Invalid" 163 "Invalid" 162 "Invalid" 161 "Invalid" ;
VAL_ 1065 BCU_CellTmp045_RM 255 "Invalid" 254 "Invalid" 253 "Invalid" 252 "Invalid" 251 "Invalid" 250 "Invalid" 249 "Invalid" 248 "Invalid" 247 "Invalid" 246 "Invalid" 245 "Invalid" 244 "Invalid" 243 "Invalid" 242 "Invalid" 241 "Invalid" 240 "Invalid" 239 "Invalid" 238 "Invalid" 237 "Invalid" 236 "Invalid" 235 "Invalid" 234 "Invalid" 233 "Invalid" 232 "Invalid" 231 "Invalid" 230 "Invalid" 229 "Invalid" 228 "Invalid" 227 "Invalid" 226 "Invalid" 225 "Invalid" 224 "Invalid" 223 "Invalid" 222 "Invalid" 221 "Invalid" 220 "Invalid" 219 "Invalid" 218 "Invalid" 217 "Invalid" 216 "Invalid" 215 "Invalid" 214 "Invalid" 213 "Invalid" 212 "Invalid" 211 "Invalid" 210 "Invalid" 209 "Invalid" 208 "Invalid" 207 "Invalid" 206 "Invalid" 205 "Invalid" 204 "Invalid" 203 "Invalid" 202 "Invalid" 201 "Invalid" 200 "Invalid" 199 "Invalid" 198 "Invalid" 197 "Invalid" 196 "Invalid" 195 "Invalid" 194 "Invalid" 193 "Invalid" 192 "Invalid" 191 "Invalid" 190 "Invalid" 189 "Invalid" 188 "Invalid" 187 "Invalid" 186 "Invalid" 185 "Invalid" 184 "Invalid" 183 "Invalid" 182 "Invalid" 181 "Invalid" 180 "Invalid" 179 "Invalid" 178 "Invalid" 177 "Invalid" 176 "Invalid" 175 "Invalid" 174 "Invalid" 173 "Invalid" 172 "Invalid" 171 "Invalid" 170 "Invalid" 169 "Invalid" 168 "Invalid" 167 "Invalid" 166 "Invalid" 165 "Invalid" 164 "Invalid" 163 "Invalid" 162 "Invalid" 161 "Invalid" ;
VAL_ 1065 BCU_CellTmp046_RM 255 "Invalid" 254 "Invalid" 253 "Invalid" 252 "Invalid" 251 "Invalid" 250 "Invalid" 249 "Invalid" 248 "Invalid" 247 "Invalid" 246 "Invalid" 245 "Invalid" 244 "Invalid" 243 "Invalid" 242 "Invalid" 241 "Invalid" 240 "Invalid" 239 "Invalid" 238 "Invalid" 237 "Invalid" 236 "Invalid" 235 "Invalid" 234 "Invalid" 233 "Invalid" 232 "Invalid" 231 "Invalid" 230 "Invalid" 229 "Invalid" 228 "Invalid" 227 "Invalid" 226 "Invalid" 225 "Invalid" 224 "Invalid" 223 "Invalid" 222 "Invalid" 221 "Invalid" 220 "Invalid" 219 "Invalid" 218 "Invalid" 217 "Invalid" 216 "Invalid" 215 "Invalid" 214 "Invalid" 213 "Invalid" 212 "Invalid" 211 "Invalid" 210 "Invalid" 209 "Invalid" 208 "Invalid" 207 "Invalid" 206 "Invalid" 205 "Invalid" 204 "Invalid" 203 "Invalid" 202 "Invalid" 201 "Invalid" 200 "Invalid" 199 "Invalid" 198 "Invalid" 197 "Invalid" 196 "Invalid" 195 "Invalid" 194 "Invalid" 193 "Invalid" 192 "Invalid" 191 "Invalid" 190 "Invalid" 189 "Invalid" 188 "Invalid" 187 "Invalid" 186 "Invalid" 185 "Invalid" 184 "Invalid" 183 "Invalid" 182 "Invalid" 181 "Invalid" 180 "Invalid" 179 "Invalid" 178 "Invalid" 177 "Invalid" 176 "Invalid" 175 "Invalid" 174 "Invalid" 173 "Invalid" 172 "Invalid" 171 "Invalid" 170 "Invalid" 169 "Invalid" 168 "Invalid" 167 "Invalid" 166 "Invalid" 165 "Invalid" 164 "Invalid" 163 "Invalid" 162 "Invalid" 161 "Invalid" ;
VAL_ 1065 BCU_CellTmp047_RM 255 "Invalid" 254 "Invalid" 253 "Invalid" 252 "Invalid" 251 "Invalid" 250 "Invalid" 249 "Invalid" 248 "Invalid" 247 "Invalid" 246 "Invalid" 245 "Invalid" 244 "Invalid" 243 "Invalid" 242 "Invalid" 241 "Invalid" 240 "Invalid" 239 "Invalid" 238 "Invalid" 237 "Invalid" 236 "Invalid" 235 "Invalid" 234 "Invalid" 233 "Invalid" 232 "Invalid" 231 "Invalid" 230 "Invalid" 229 "Invalid" 228 "Invalid" 227 "Invalid" 226 "Invalid" 225 "Invalid" 224 "Invalid" 223 "Invalid" 222 "Invalid" 221 "Invalid" 220 "Invalid" 219 "Invalid" 218 "Invalid" 217 "Invalid" 216 "Invalid" 215 "Invalid" 214 "Invalid" 213 "Invalid" 212 "Invalid" 211 "Invalid" 210 "Invalid" 209 "Invalid" 208 "Invalid" 207 "Invalid" 206 "Invalid" 205 "Invalid" 204 "Invalid" 203 "Invalid" 202 "Invalid" 201 "Invalid" 200 "Invalid" 199 "Invalid" 198 "Invalid" 197 "Invalid" 196 "Invalid" 195 "Invalid" 194 "Invalid" 193 "Invalid" 192 "Invalid" 191 "Invalid" 190 "Invalid" 189 "Invalid" 188 "Invalid" 187 "Invalid" 186 "Invalid" 185 "Invalid" 184 "Invalid" 183 "Invalid" 182 "Invalid" 181 "Invalid" 180 "Invalid" 179 "Invalid" 178 "Invalid" 177 "Invalid" 176 "Invalid" 175 "Invalid" 174 "Invalid" 173 "Invalid" 172 "Invalid" 171 "Invalid" 170 "Invalid" 169 "Invalid" 168 "Invalid" 167 "Invalid" 166 "Invalid" 165 "Invalid" 164 "Invalid" 163 "Invalid" 162 "Invalid" 161 "Invalid" ;
VAL_ 1065 BCU_CellTmp048_RM 255 "Invalid" 254 "Invalid" 253 "Invalid" 252 "Invalid" 251 "Invalid" 250 "Invalid" 249 "Invalid" 248 "Invalid" 247 "Invalid" 246 "Invalid" 245 "Invalid" 244 "Invalid" 243 "Invalid" 242 "Invalid" 241 "Invalid" 240 "Invalid" 239 "Invalid" 238 "Invalid" 237 "Invalid" 236 "Invalid" 235 "Invalid" 234 "Invalid" 233 "Invalid" 232 "Invalid" 231 "Invalid" 230 "Invalid" 229 "Invalid" 228 "Invalid" 227 "Invalid" 226 "Invalid" 225 "Invalid" 224 "Invalid" 223 "Invalid" 222 "Invalid" 221 "Invalid" 220 "Invalid" 219 "Invalid" 218 "Invalid" 217 "Invalid" 216 "Invalid" 215 "Invalid" 214 "Invalid" 213 "Invalid" 212 "Invalid" 211 "Invalid" 210 "Invalid" 209 "Invalid" 208 "Invalid" 207 "Invalid" 206 "Invalid" 205 "Invalid" 204 "Invalid" 203 "Invalid" 202 "Invalid" 201 "Invalid" 200 "Invalid" 199 "Invalid" 198 "Invalid" 197 "Invalid" 196 "Invalid" 195 "Invalid" 194 "Invalid" 193 "Invalid" 192 "Invalid" 191 "Invalid" 190 "Invalid" 189 "Invalid" 188 "Invalid" 187 "Invalid" 186 "Invalid" 185 "Invalid" 184 "Invalid" 183 "Invalid" 182 "Invalid" 181 "Invalid" 180 "Invalid" 179 "Invalid" 178 "Invalid" 177 "Invalid" 176 "Invalid" 175 "Invalid" 174 "Invalid" 173 "Invalid" 172 "Invalid" 171 "Invalid" 170 "Invalid" 169 "Invalid" 168 "Invalid" 167 "Invalid" 166 "Invalid" 165 "Invalid" 164 "Invalid" 163 "Invalid" 162 "Invalid" 161 "Invalid" ;
VAL_ 1065 BCU_CellTmp049_RM 255 "Invalid" 254 "Invalid" 253 "Invalid" 252 "Invalid" 251 "Invalid" 250 "Invalid" 249 "Invalid" 248 "Invalid" 247 "Invalid" 246 "Invalid" 245 "Invalid" 244 "Invalid" 243 "Invalid" 242 "Invalid" 241 "Invalid" 240 "Invalid" 239 "Invalid" 238 "Invalid" 237 "Invalid" 236 "Invalid" 235 "Invalid" 234 "Invalid" 233 "Invalid" 232 "Invalid" 231 "Invalid" 230 "Invalid" 229 "Invalid" 228 "Invalid" 227 "Invalid" 226 "Invalid" 225 "Invalid" 224 "Invalid" 223 "Invalid" 222 "Invalid" 221 "Invalid" 220 "Invalid" 219 "Invalid" 218 "Invalid" 217 "Invalid" 216 "Invalid" 215 "Invalid" 214 "Invalid" 213 "Invalid" 212 "Invalid" 211 "Invalid" 210 "Invalid" 209 "Invalid" 208 "Invalid" 207 "Invalid" 206 "Invalid" 205 "Invalid" 204 "Invalid" 203 "Invalid" 202 "Invalid" 201 "Invalid" 200 "Invalid" 199 "Invalid" 198 "Invalid" 197 "Invalid" 196 "Invalid" 195 "Invalid" 194 "Invalid" 193 "Invalid" 192 "Invalid" 191 "Invalid" 190 "Invalid" 189 "Invalid" 188 "Invalid" 187 "Invalid" 186 "Invalid" 185 "Invalid" 184 "Invalid" 183 "Invalid" 182 "Invalid" 181 "Invalid" 180 "Invalid" 179 "Invalid" 178 "Invalid" 177 "Invalid" 176 "Invalid" 175 "Invalid" 174 "Invalid" 173 "Invalid" 172 "Invalid" 171 "Invalid" 170 "Invalid" 169 "Invalid" 168 "Invalid" 167 "Invalid" 166 "Invalid" 165 "Invalid" 164 "Invalid" 163 "Invalid" 162 "Invalid" 161 "Invalid" ;
VAL_ 1066 BCU_CellTmp050_RM 255 "Invalid" 254 "Invalid" 253 "Invalid" 252 "Invalid" 251 "Invalid" 250 "Invalid" 249 "Invalid" 248 "Invalid" 247 "Invalid" 246 "Invalid" 245 "Invalid" 244 "Invalid" 243 "Invalid" 242 "Invalid" 241 "Invalid" 240 "Invalid" 239 "Invalid" 238 "Invalid" 237 "Invalid" 236 "Invalid" 235 "Invalid" 234 "Invalid" 233 "Invalid" 232 "Invalid" 231 "Invalid" 230 "Invalid" 229 "Invalid" 228 "Invalid" 227 "Invalid" 226 "Invalid" 225 "Invalid" 224 "Invalid" 223 "Invalid" 222 "Invalid" 221 "Invalid" 220 "Invalid" 219 "Invalid" 218 "Invalid" 217 "Invalid" 216 "Invalid" 215 "Invalid" 214 "Invalid" 213 "Invalid" 212 "Invalid" 211 "Invalid" 210 "Invalid" 209 "Invalid" 208 "Invalid" 207 "Invalid" 206 "Invalid" 205 "Invalid" 204 "Invalid" 203 "Invalid" 202 "Invalid" 201 "Invalid" 200 "Invalid" 199 "Invalid" 198 "Invalid" 197 "Invalid" 196 "Invalid" 195 "Invalid" 194 "Invalid" 193 "Invalid" 192 "Invalid" 191 "Invalid" 190 "Invalid" 189 "Invalid" 188 "Invalid" 187 "Invalid" 186 "Invalid" 185 "Invalid" 184 "Invalid" 183 "Invalid" 182 "Invalid" 181 "Invalid" 180 "Invalid" 179 "Invalid" 178 "Invalid" 177 "Invalid" 176 "Invalid" 175 "Invalid" 174 "Invalid" 173 "Invalid" 172 "Invalid" 171 "Invalid" 170 "Invalid" 169 "Invalid" 168 "Invalid" 167 "Invalid" 166 "Invalid" 165 "Invalid" 164 "Invalid" 163 "Invalid" 162 "Invalid" 161 "Invalid" ;
VAL_ 1066 BCU_CellTmp051_RM 255 "Invalid" 254 "Invalid" 253 "Invalid" 252 "Invalid" 251 "Invalid" 250 "Invalid" 249 "Invalid" 248 "Invalid" 247 "Invalid" 246 "Invalid" 245 "Invalid" 244 "Invalid" 243 "Invalid" 242 "Invalid" 241 "Invalid" 240 "Invalid" 239 "Invalid" 238 "Invalid" 237 "Invalid" 236 "Invalid" 235 "Invalid" 234 "Invalid" 233 "Invalid" 232 "Invalid" 231 "Invalid" 230 "Invalid" 229 "Invalid" 228 "Invalid" 227 "Invalid" 226 "Invalid" 225 "Invalid" 224 "Invalid" 223 "Invalid" 222 "Invalid" 221 "Invalid" 220 "Invalid" 219 "Invalid" 218 "Invalid" 217 "Invalid" 216 "Invalid" 215 "Invalid" 214 "Invalid" 213 "Invalid" 212 "Invalid" 211 "Invalid" 210 "Invalid" 209 "Invalid" 208 "Invalid" 207 "Invalid" 206 "Invalid" 205 "Invalid" 204 "Invalid" 203 "Invalid" 202 "Invalid" 201 "Invalid" 200 "Invalid" 199 "Invalid" 198 "Invalid" 197 "Invalid" 196 "Invalid" 195 "Invalid" 194 "Invalid" 193 "Invalid" 192 "Invalid" 191 "Invalid" 190 "Invalid" 189 "Invalid" 188 "Invalid" 187 "Invalid" 186 "Invalid" 185 "Invalid" 184 "Invalid" 183 "Invalid" 182 "Invalid" 181 "Invalid" 180 "Invalid" 179 "Invalid" 178 "Invalid" 177 "Invalid" 176 "Invalid" 175 "Invalid" 174 "Invalid" 173 "Invalid" 172 "Invalid" 171 "Invalid" 170 "Invalid" 169 "Invalid" 168 "Invalid" 167 "Invalid" 166 "Invalid" 165 "Invalid" 164 "Invalid" 163 "Invalid" 162 "Invalid" 161 "Invalid" ;
VAL_ 1066 BCU_CellTmp052_RM 255 "Invalid" 254 "Invalid" 253 "Invalid" 252 "Invalid" 251 "Invalid" 250 "Invalid" 249 "Invalid" 248 "Invalid" 247 "Invalid" 246 "Invalid" 245 "Invalid" 244 "Invalid" 243 "Invalid" 242 "Invalid" 241 "Invalid" 240 "Invalid" 239 "Invalid" 238 "Invalid" 237 "Invalid" 236 "Invalid" 235 "Invalid" 234 "Invalid" 233 "Invalid" 232 "Invalid" 231 "Invalid" 230 "Invalid" 229 "Invalid" 228 "Invalid" 227 "Invalid" 226 "Invalid" 225 "Invalid" 224 "Invalid" 223 "Invalid" 222 "Invalid" 221 "Invalid" 220 "Invalid" 219 "Invalid" 218 "Invalid" 217 "Invalid" 216 "Invalid" 215 "Invalid" 214 "Invalid" 213 "Invalid" 212 "Invalid" 211 "Invalid" 210 "Invalid" 209 "Invalid" 208 "Invalid" 207 "Invalid" 206 "Invalid" 205 "Invalid" 204 "Invalid" 203 "Invalid" 202 "Invalid" 201 "Invalid" 200 "Invalid" 199 "Invalid" 198 "Invalid" 197 "Invalid" 196 "Invalid" 195 "Invalid" 194 "Invalid" 193 "Invalid" 192 "Invalid" 191 "Invalid" 190 "Invalid" 189 "Invalid" 188 "Invalid" 187 "Invalid" 186 "Invalid" 185 "Invalid" 184 "Invalid" 183 "Invalid" 182 "Invalid" 181 "Invalid" 180 "Invalid" 179 "Invalid" 178 "Invalid" 177 "Invalid" 176 "Invalid" 175 "Invalid" 174 "Invalid" 173 "Invalid" 172 "Invalid" 171 "Invalid" 170 "Invalid" 169 "Invalid" 168 "Invalid" 167 "Invalid" 166 "Invalid" 165 "Invalid" 164 "Invalid" 163 "Invalid" 162 "Invalid" 161 "Invalid" ;
VAL_ 1066 BCU_CellTmp053_RM 255 "Invalid" 254 "Invalid" 253 "Invalid" 252 "Invalid" 251 "Invalid" 250 "Invalid" 249 "Invalid" 248 "Invalid" 247 "Invalid" 246 "Invalid" 245 "Invalid" 244 "Invalid" 243 "Invalid" 242 "Invalid" 241 "Invalid" 240 "Invalid" 239 "Invalid" 238 "Invalid" 237 "Invalid" 236 "Invalid" 235 "Invalid" 234 "Invalid" 233 "Invalid" 232 "Invalid" 231 "Invalid" 230 "Invalid" 229 "Invalid" 228 "Invalid" 227 "Invalid" 226 "Invalid" 225 "Invalid" 224 "Invalid" 223 "Invalid" 222 "Invalid" 221 "Invalid" 220 "Invalid" 219 "Invalid" 218 "Invalid" 217 "Invalid" 216 "Invalid" 215 "Invalid" 214 "Invalid" 213 "Invalid" 212 "Invalid" 211 "Invalid" 210 "Invalid" 209 "Invalid" 208 "Invalid" 207 "Invalid" 206 "Invalid" 205 "Invalid" 204 "Invalid" 203 "Invalid" 202 "Invalid" 201 "Invalid" 200 "Invalid" 199 "Invalid" 198 "Invalid" 197 "Invalid" 196 "Invalid" 195 "Invalid" 194 "Invalid" 193 "Invalid" 192 "Invalid" 191 "Invalid" 190 "Invalid" 189 "Invalid" 188 "Invalid" 187 "Invalid" 186 "Invalid" 185 "Invalid" 184 "Invalid" 183 "Invalid" 182 "Invalid" 181 "Invalid" 180 "Invalid" 179 "Invalid" 178 "Invalid" 177 "Invalid" 176 "Invalid" 175 "Invalid" 174 "Invalid" 173 "Invalid" 172 "Invalid" 171 "Invalid" 170 "Invalid" 169 "Invalid" 168 "Invalid" 167 "Invalid" 166 "Invalid" 165 "Invalid" 164 "Invalid" 163 "Invalid" 162 "Invalid" 161 "Invalid" ;
VAL_ 1066 BCU_CellTmp054_RM 255 "Invalid" 254 "Invalid" 253 "Invalid" 252 "Invalid" 251 "Invalid" 250 "Invalid" 249 "Invalid" 248 "Invalid" 247 "Invalid" 246 "Invalid" 245 "Invalid" 244 "Invalid" 243 "Invalid" 242 "Invalid" 241 "Invalid" 240 "Invalid" 239 "Invalid" 238 "Invalid" 237 "Invalid" 236 "Invalid" 235 "Invalid" 234 "Invalid" 233 "Invalid" 232 "Invalid" 231 "Invalid" 230 "Invalid" 229 "Invalid" 228 "Invalid" 227 "Invalid" 226 "Invalid" 225 "Invalid" 224 "Invalid" 223 "Invalid" 222 "Invalid" 221 "Invalid" 220 "Invalid" 219 "Invalid" 218 "Invalid" 217 "Invalid" 216 "Invalid" 215 "Invalid" 214 "Invalid" 213 "Invalid" 212 "Invalid" 211 "Invalid" 210 "Invalid" 209 "Invalid" 208 "Invalid" 207 "Invalid" 206 "Invalid" 205 "Invalid" 204 "Invalid" 203 "Invalid" 202 "Invalid" 201 "Invalid" 200 "Invalid" 199 "Invalid" 198 "Invalid" 197 "Invalid" 196 "Invalid" 195 "Invalid" 194 "Invalid" 193 "Invalid" 192 "Invalid" 191 "Invalid" 190 "Invalid" 189 "Invalid" 188 "Invalid" 187 "Invalid" 186 "Invalid" 185 "Invalid" 184 "Invalid" 183 "Invalid" 182 "Invalid" 181 "Invalid" 180 "Invalid" 179 "Invalid" 178 "Invalid" 177 "Invalid" 176 "Invalid" 175 "Invalid" 174 "Invalid" 173 "Invalid" 172 "Invalid" 171 "Invalid" 170 "Invalid" 169 "Invalid" 168 "Invalid" 167 "Invalid" 166 "Invalid" 165 "Invalid" 164 "Invalid" 163 "Invalid" 162 "Invalid" 161 "Invalid" ;
VAL_ 1066 BCU_CellTmp055_RM 255 "Invalid" 254 "Invalid" 253 "Invalid" 252 "Invalid" 251 "Invalid" 250 "Invalid" 249 "Invalid" 248 "Invalid" 247 "Invalid" 246 "Invalid" 245 "Invalid" 244 "Invalid" 243 "Invalid" 242 "Invalid" 241 "Invalid" 240 "Invalid" 239 "Invalid" 238 "Invalid" 237 "Invalid" 236 "Invalid" 235 "Invalid" 234 "Invalid" 233 "Invalid" 232 "Invalid" 231 "Invalid" 230 "Invalid" 229 "Invalid" 228 "Invalid" 227 "Invalid" 226 "Invalid" 225 "Invalid" 224 "Invalid" 223 "Invalid" 222 "Invalid" 221 "Invalid" 220 "Invalid" 219 "Invalid" 218 "Invalid" 217 "Invalid" 216 "Invalid" 215 "Invalid" 214 "Invalid" 213 "Invalid" 212 "Invalid" 211 "Invalid" 210 "Invalid" 209 "Invalid" 208 "Invalid" 207 "Invalid" 206 "Invalid" 205 "Invalid" 204 "Invalid" 203 "Invalid" 202 "Invalid" 201 "Invalid" 200 "Invalid" 199 "Invalid" 198 "Invalid" 197 "Invalid" 196 "Invalid" 195 "Invalid" 194 "Invalid" 193 "Invalid" 192 "Invalid" 191 "Invalid" 190 "Invalid" 189 "Invalid" 188 "Invalid" 187 "Invalid" 186 "Invalid" 185 "Invalid" 184 "Invalid" 183 "Invalid" 182 "Invalid" 181 "Invalid" 180 "Invalid" 179 "Invalid" 178 "Invalid" 177 "Invalid" 176 "Invalid" 175 "Invalid" 174 "Invalid" 173 "Invalid" 172 "Invalid" 171 "Invalid" 170 "Invalid" 169 "Invalid" 168 "Invalid" 167 "Invalid" 166 "Invalid" 165 "Invalid" 164 "Invalid" 163 "Invalid" 162 "Invalid" 161 "Invalid" ;
VAL_ 1066 BCU_CellTmp056_RM 255 "Invalid" 254 "Invalid" 253 "Invalid" 252 "Invalid" 251 "Invalid" 250 "Invalid" 249 "Invalid" 248 "Invalid" 247 "Invalid" 246 "Invalid" 245 "Invalid" 244 "Invalid" 243 "Invalid" 242 "Invalid" 241 "Invalid" 240 "Invalid" 239 "Invalid" 238 "Invalid" 237 "Invalid" 236 "Invalid" 235 "Invalid" 234 "Invalid" 233 "Invalid" 232 "Invalid" 231 "Invalid" 230 "Invalid" 229 "Invalid" 228 "Invalid" 227 "Invalid" 226 "Invalid" 225 "Invalid" 224 "Invalid" 223 "Invalid" 222 "Invalid" 221 "Invalid" 220 "Invalid" 219 "Invalid" 218 "Invalid" 217 "Invalid" 216 "Invalid" 215 "Invalid" 214 "Invalid" 213 "Invalid" 212 "Invalid" 211 "Invalid" 210 "Invalid" 209 "Invalid" 208 "Invalid" 207 "Invalid" 206 "Invalid" 205 "Invalid" 204 "Invalid" 203 "Invalid" 202 "Invalid" 201 "Invalid" 200 "Invalid" 199 "Invalid" 198 "Invalid" 197 "Invalid" 196 "Invalid" 195 "Invalid" 194 "Invalid" 193 "Invalid" 192 "Invalid" 191 "Invalid" 190 "Invalid" 189 "Invalid" 188 "Invalid" 187 "Invalid" 186 "Invalid" 185 "Invalid" 184 "Invalid" 183 "Invalid" 182 "Invalid" 181 "Invalid" 180 "Invalid" 179 "Invalid" 178 "Invalid" 177 "Invalid" 176 "Invalid" 175 "Invalid" 174 "Invalid" 173 "Invalid" 172 "Invalid" 171 "Invalid" 170 "Invalid" 169 "Invalid" 168 "Invalid" 167 "Invalid" 166 "Invalid" 165 "Invalid" 164 "Invalid" 163 "Invalid" 162 "Invalid" 161 "Invalid" ;
VAL_ 1066 BCU_CellTmp057_RM 255 "Invalid" 254 "Invalid" 253 "Invalid" 252 "Invalid" 251 "Invalid" 250 "Invalid" 249 "Invalid" 248 "Invalid" 247 "Invalid" 246 "Invalid" 245 "Invalid" 244 "Invalid" 243 "Invalid" 242 "Invalid" 241 "Invalid" 240 "Invalid" 239 "Invalid" 238 "Invalid" 237 "Invalid" 236 "Invalid" 235 "Invalid" 234 "Invalid" 233 "Invalid" 232 "Invalid" 231 "Invalid" 230 "Invalid" 229 "Invalid" 228 "Invalid" 227 "Invalid" 226 "Invalid" 225 "Invalid" 224 "Invalid" 223 "Invalid" 222 "Invalid" 221 "Invalid" 220 "Invalid" 219 "Invalid" 218 "Invalid" 217 "Invalid" 216 "Invalid" 215 "Invalid" 214 "Invalid" 213 "Invalid" 212 "Invalid" 211 "Invalid" 210 "Invalid" 209 "Invalid" 208 "Invalid" 207 "Invalid" 206 "Invalid" 205 "Invalid" 204 "Invalid" 203 "Invalid" 202 "Invalid" 201 "Invalid" 200 "Invalid" 199 "Invalid" 198 "Invalid" 197 "Invalid" 196 "Invalid" 195 "Invalid" 194 "Invalid" 193 "Invalid" 192 "Invalid" 191 "Invalid" 190 "Invalid" 189 "Invalid" 188 "Invalid" 187 "Invalid" 186 "Invalid" 185 "Invalid" 184 "Invalid" 183 "Invalid" 182 "Invalid" 181 "Invalid" 180 "Invalid" 179 "Invalid" 178 "Invalid" 177 "Invalid" 176 "Invalid" 175 "Invalid" 174 "Invalid" 173 "Invalid" 172 "Invalid" 171 "Invalid" 170 "Invalid" 169 "Invalid" 168 "Invalid" 167 "Invalid" 166 "Invalid" 165 "Invalid" 164 "Invalid" 163 "Invalid" 162 "Invalid" 161 "Invalid" ;
VAL_ 1067 BCU_CellTmp058_RM 255 "Invalid" 254 "Invalid" 253 "Invalid" 252 "Invalid" 251 "Invalid" 250 "Invalid" 249 "Invalid" 248 "Invalid" 247 "Invalid" 246 "Invalid" 245 "Invalid" 244 "Invalid" 243 "Invalid" 242 "Invalid" 241 "Invalid" 240 "Invalid" 239 "Invalid" 238 "Invalid" 237 "Invalid" 236 "Invalid" 235 "Invalid" 234 "Invalid" 233 "Invalid" 232 "Invalid" 231 "Invalid" 230 "Invalid" 229 "Invalid" 228 "Invalid" 227 "Invalid" 226 "Invalid" 225 "Invalid" 224 "Invalid" 223 "Invalid" 222 "Invalid" 221 "Invalid" 220 "Invalid" 219 "Invalid" 218 "Invalid" 217 "Invalid" 216 "Invalid" 215 "Invalid" 214 "Invalid" 213 "Invalid" 212 "Invalid" 211 "Invalid" 210 "Invalid" 209 "Invalid" 208 "Invalid" 207 "Invalid" 206 "Invalid" 205 "Invalid" 204 "Invalid" 203 "Invalid" 202 "Invalid" 201 "Invalid" 200 "Invalid" 199 "Invalid" 198 "Invalid" 197 "Invalid" 196 "Invalid" 195 "Invalid" 194 "Invalid" 193 "Invalid" 192 "Invalid" 191 "Invalid" 190 "Invalid" 189 "Invalid" 188 "Invalid" 187 "Invalid" 186 "Invalid" 185 "Invalid" 184 "Invalid" 183 "Invalid" 182 "Invalid" 181 "Invalid" 180 "Invalid" 179 "Invalid" 178 "Invalid" 177 "Invalid" 176 "Invalid" 175 "Invalid" 174 "Invalid" 173 "Invalid" 172 "Invalid" 171 "Invalid" 170 "Invalid" 169 "Invalid" 168 "Invalid" 167 "Invalid" 166 "Invalid" 165 "Invalid" 164 "Invalid" 163 "Invalid" 162 "Invalid" 161 "Invalid" ;
VAL_ 1067 BCU_CellTmp059_RM 255 "Invalid" 254 "Invalid" 253 "Invalid" 252 "Invalid" 251 "Invalid" 250 "Invalid" 249 "Invalid" 248 "Invalid" 247 "Invalid" 246 "Invalid" 245 "Invalid" 244 "Invalid" 243 "Invalid" 242 "Invalid" 241 "Invalid" 240 "Invalid" 239 "Invalid" 238 "Invalid" 237 "Invalid" 236 "Invalid" 235 "Invalid" 234 "Invalid" 233 "Invalid" 232 "Invalid" 231 "Invalid" 230 "Invalid" 229 "Invalid" 228 "Invalid" 227 "Invalid" 226 "Invalid" 225 "Invalid" 224 "Invalid" 223 "Invalid" 222 "Invalid" 221 "Invalid" 220 "Invalid" 219 "Invalid" 218 "Invalid" 217 "Invalid" 216 "Invalid" 215 "Invalid" 214 "Invalid" 213 "Invalid" 212 "Invalid" 211 "Invalid" 210 "Invalid" 209 "Invalid" 208 "Invalid" 207 "Invalid" 206 "Invalid" 205 "Invalid" 204 "Invalid" 203 "Invalid" 202 "Invalid" 201 "Invalid" 200 "Invalid" 199 "Invalid" 198 "Invalid" 197 "Invalid" 196 "Invalid" 195 "Invalid" 194 "Invalid" 193 "Invalid" 192 "Invalid" 191 "Invalid" 190 "Invalid" 189 "Invalid" 188 "Invalid" 187 "Invalid" 186 "Invalid" 185 "Invalid" 184 "Invalid" 183 "Invalid" 182 "Invalid" 181 "Invalid" 180 "Invalid" 179 "Invalid" 178 "Invalid" 177 "Invalid" 176 "Invalid" 175 "Invalid" 174 "Invalid" 173 "Invalid" 172 "Invalid" 171 "Invalid" 170 "Invalid" 169 "Invalid" 168 "Invalid" 167 "Invalid" 166 "Invalid" 165 "Invalid" 164 "Invalid" 163 "Invalid" 162 "Invalid" 161 "Invalid" ;
VAL_ 1067 BCU_CellTmp060_RM 255 "Invalid" 254 "Invalid" 253 "Invalid" 252 "Invalid" 251 "Invalid" 250 "Invalid" 249 "Invalid" 248 "Invalid" 247 "Invalid" 246 "Invalid" 245 "Invalid" 244 "Invalid" 243 "Invalid" 242 "Invalid" 241 "Invalid" 240 "Invalid" 239 "Invalid" 238 "Invalid" 237 "Invalid" 236 "Invalid" 235 "Invalid" 234 "Invalid" 233 "Invalid" 232 "Invalid" 231 "Invalid" 230 "Invalid" 229 "Invalid" 228 "Invalid" 227 "Invalid" 226 "Invalid" 225 "Invalid" 224 "Invalid" 223 "Invalid" 222 "Invalid" 221 "Invalid" 220 "Invalid" 219 "Invalid" 218 "Invalid" 217 "Invalid" 216 "Invalid" 215 "Invalid" 214 "Invalid" 213 "Invalid" 212 "Invalid" 211 "Invalid" 210 "Invalid" 209 "Invalid" 208 "Invalid" 207 "Invalid" 206 "Invalid" 205 "Invalid" 204 "Invalid" 203 "Invalid" 202 "Invalid" 201 "Invalid" 200 "Invalid" 199 "Invalid" 198 "Invalid" 197 "Invalid" 196 "Invalid" 195 "Invalid" 194 "Invalid" 193 "Invalid" 192 "Invalid" 191 "Invalid" 190 "Invalid" 189 "Invalid" 188 "Invalid" 187 "Invalid" 186 "Invalid" 185 "Invalid" 184 "Invalid" 183 "Invalid" 182 "Invalid" 181 "Invalid" 180 "Invalid" 179 "Invalid" 178 "Invalid" 177 "Invalid" 176 "Invalid" 175 "Invalid" 174 "Invalid" 173 "Invalid" 172 "Invalid" 171 "Invalid" 170 "Invalid" 169 "Invalid" 168 "Invalid" 167 "Invalid" 166 "Invalid" 165 "Invalid" 164 "Invalid" 163 "Invalid" 162 "Invalid" 161 "Invalid" ;
VAL_ 1067 BCU_CellTmp061_RM 255 "Invalid" 254 "Invalid" 253 "Invalid" 252 "Invalid" 251 "Invalid" 250 "Invalid" 249 "Invalid" 248 "Invalid" 247 "Invalid" 246 "Invalid" 245 "Invalid" 244 "Invalid" 243 "Invalid" 242 "Invalid" 241 "Invalid" 240 "Invalid" 239 "Invalid" 238 "Invalid" 237 "Invalid" 236 "Invalid" 235 "Invalid" 234 "Invalid" 233 "Invalid" 232 "Invalid" 231 "Invalid" 230 "Invalid" 229 "Invalid" 228 "Invalid" 227 "Invalid" 226 "Invalid" 225 "Invalid" 224 "Invalid" 223 "Invalid" 222 "Invalid" 221 "Invalid" 220 "Invalid" 219 "Invalid" 218 "Invalid" 217 "Invalid" 216 "Invalid" 215 "Invalid" 214 "Invalid" 213 "Invalid" 212 "Invalid" 211 "Invalid" 210 "Invalid" 209 "Invalid" 208 "Invalid" 207 "Invalid" 206 "Invalid" 205 "Invalid" 204 "Invalid" 203 "Invalid" 202 "Invalid" 201 "Invalid" 200 "Invalid" 199 "Invalid" 198 "Invalid" 197 "Invalid" 196 "Invalid" 195 "Invalid" 194 "Invalid" 193 "Invalid" 192 "Invalid" 191 "Invalid" 190 "Invalid" 189 "Invalid" 188 "Invalid" 187 "Invalid" 186 "Invalid" 185 "Invalid" 184 "Invalid" 183 "Invalid" 182 "Invalid" 181 "Invalid" 180 "Invalid" 179 "Invalid" 178 "Invalid" 177 "Invalid" 176 "Invalid" 175 "Invalid" 174 "Invalid" 173 "Invalid" 172 "Invalid" 171 "Invalid" 170 "Invalid" 169 "Invalid" 168 "Invalid" 167 "Invalid" 166 "Invalid" 165 "Invalid" 164 "Invalid" 163 "Invalid" 162 "Invalid" 161 "Invalid" ;
VAL_ 1067 BCU_CellTmp062_RM 255 "Invalid" 254 "Invalid" 253 "Invalid" 252 "Invalid" 251 "Invalid" 250 "Invalid" 249 "Invalid" 248 "Invalid" 247 "Invalid" 246 "Invalid" 245 "Invalid" 244 "Invalid" 243 "Invalid" 242 "Invalid" 241 "Invalid" 240 "Invalid" 239 "Invalid" 238 "Invalid" 237 "Invalid" 236 "Invalid" 235 "Invalid" 234 "Invalid" 233 "Invalid" 232 "Invalid" 231 "Invalid" 230 "Invalid" 229 "Invalid" 228 "Invalid" 227 "Invalid" 226 "Invalid" 225 "Invalid" 224 "Invalid" 223 "Invalid" 222 "Invalid" 221 "Invalid" 220 "Invalid" 219 "Invalid" 218 "Invalid" 217 "Invalid" 216 "Invalid" 215 "Invalid" 214 "Invalid" 213 "Invalid" 212 "Invalid" 211 "Invalid" 210 "Invalid" 209 "Invalid" 208 "Invalid" 207 "Invalid" 206 "Invalid" 205 "Invalid" 204 "Invalid" 203 "Invalid" 202 "Invalid" 201 "Invalid" 200 "Invalid" 199 "Invalid" 198 "Invalid" 197 "Invalid" 196 "Invalid" 195 "Invalid" 194 "Invalid" 193 "Invalid" 192 "Invalid" 191 "Invalid" 190 "Invalid" 189 "Invalid" 188 "Invalid" 187 "Invalid" 186 "Invalid" 185 "Invalid" 184 "Invalid" 183 "Invalid" 182 "Invalid" 181 "Invalid" 180 "Invalid" 179 "Invalid" 178 "Invalid" 177 "Invalid" 176 "Invalid" 175 "Invalid" 174 "Invalid" 173 "Invalid" 172 "Invalid" 171 "Invalid" 170 "Invalid" 169 "Invalid" 168 "Invalid" 167 "Invalid" 166 "Invalid" 165 "Invalid" 164 "Invalid" 163 "Invalid" 162 "Invalid" 161 "Invalid" ;
VAL_ 1067 BCU_CellTmp063_RM 255 "Invalid" 254 "Invalid" 253 "Invalid" 252 "Invalid" 251 "Invalid" 250 "Invalid" 249 "Invalid" 248 "Invalid" 247 "Invalid" 246 "Invalid" 245 "Invalid" 244 "Invalid" 243 "Invalid" 242 "Invalid" 241 "Invalid" 240 "Invalid" 239 "Invalid" 238 "Invalid" 237 "Invalid" 236 "Invalid" 235 "Invalid" 234 "Invalid" 233 "Invalid" 232 "Invalid" 231 "Invalid" 230 "Invalid" 229 "Invalid" 228 "Invalid" 227 "Invalid" 226 "Invalid" 225 "Invalid" 224 "Invalid" 223 "Invalid" 222 "Invalid" 221 "Invalid" 220 "Invalid" 219 "Invalid" 218 "Invalid" 217 "Invalid" 216 "Invalid" 215 "Invalid" 214 "Invalid" 213 "Invalid" 212 "Invalid" 211 "Invalid" 210 "Invalid" 209 "Invalid" 208 "Invalid" 207 "Invalid" 206 "Invalid" 205 "Invalid" 204 "Invalid" 203 "Invalid" 202 "Invalid" 201 "Invalid" 200 "Invalid" 199 "Invalid" 198 "Invalid" 197 "Invalid" 196 "Invalid" 195 "Invalid" 194 "Invalid" 193 "Invalid" 192 "Invalid" 191 "Invalid" 190 "Invalid" 189 "Invalid" 188 "Invalid" 187 "Invalid" 186 "Invalid" 185 "Invalid" 184 "Invalid" 183 "Invalid" 182 "Invalid" 181 "Invalid" 180 "Invalid" 179 "Invalid" 178 "Invalid" 177 "Invalid" 176 "Invalid" 175 "Invalid" 174 "Invalid" 173 "Invalid" 172 "Invalid" 171 "Invalid" 170 "Invalid" 169 "Invalid" 168 "Invalid" 167 "Invalid" 166 "Invalid" 165 "Invalid" 164 "Invalid" 163 "Invalid" 162 "Invalid" 161 "Invalid" ;
VAL_ 1067 BCU_CellTmp064_RM 255 "Invalid" 254 "Invalid" 253 "Invalid" 252 "Invalid" 251 "Invalid" 250 "Invalid" 249 "Invalid" 248 "Invalid" 247 "Invalid" 246 "Invalid" 245 "Invalid" 244 "Invalid" 243 "Invalid" 242 "Invalid" 241 "Invalid" 240 "Invalid" 239 "Invalid" 238 "Invalid" 237 "Invalid" 236 "Invalid" 235 "Invalid" 234 "Invalid" 233 "Invalid" 232 "Invalid" 231 "Invalid" 230 "Invalid" 229 "Invalid" 228 "Invalid" 227 "Invalid" 226 "Invalid" 225 "Invalid" 224 "Invalid" 223 "Invalid" 222 "Invalid" 221 "Invalid" 220 "Invalid" 219 "Invalid" 218 "Invalid" 217 "Invalid" 216 "Invalid" 215 "Invalid" 214 "Invalid" 213 "Invalid" 212 "Invalid" 211 "Invalid" 210 "Invalid" 209 "Invalid" 208 "Invalid" 207 "Invalid" 206 "Invalid" 205 "Invalid" 204 "Invalid" 203 "Invalid" 202 "Invalid" 201 "Invalid" 200 "Invalid" 199 "Invalid" 198 "Invalid" 197 "Invalid" 196 "Invalid" 195 "Invalid" 194 "Invalid" 193 "Invalid" 192 "Invalid" 191 "Invalid" 190 "Invalid" 189 "Invalid" 188 "Invalid" 187 "Invalid" 186 "Invalid" 185 "Invalid" 184 "Invalid" 183 "Invalid" 182 "Invalid" 181 "Invalid" 180 "Invalid" 179 "Invalid" 178 "Invalid" 177 "Invalid" 176 "Invalid" 175 "Invalid" 174 "Invalid" 173 "Invalid" 172 "Invalid" 171 "Invalid" 170 "Invalid" 169 "Invalid" 168 "Invalid" 167 "Invalid" 166 "Invalid" 165 "Invalid" 164 "Invalid" 163 "Invalid" 162 "Invalid" 161 "Invalid" ;
VAL_ 1067 BCU_CellTmp065_RM 255 "Invalid" 254 "Invalid" 253 "Invalid" 252 "Invalid" 251 "Invalid" 250 "Invalid" 249 "Invalid" 248 "Invalid" 247 "Invalid" 246 "Invalid" 245 "Invalid" 244 "Invalid" 243 "Invalid" 242 "Invalid" 241 "Invalid" 240 "Invalid" 239 "Invalid" 238 "Invalid" 237 "Invalid" 236 "Invalid" 235 "Invalid" 234 "Invalid" 233 "Invalid" 232 "Invalid" 231 "Invalid" 230 "Invalid" 229 "Invalid" 228 "Invalid" 227 "Invalid" 226 "Invalid" 225 "Invalid" 224 "Invalid" 223 "Invalid" 222 "Invalid" 221 "Invalid" 220 "Invalid" 219 "Invalid" 218 "Invalid" 217 "Invalid" 216 "Invalid" 215 "Invalid" 214 "Invalid" 213 "Invalid" 212 "Invalid" 211 "Invalid" 210 "Invalid" 209 "Invalid" 208 "Invalid" 207 "Invalid" 206 "Invalid" 205 "Invalid" 204 "Invalid" 203 "Invalid" 202 "Invalid" 201 "Invalid" 200 "Invalid" 199 "Invalid" 198 "Invalid" 197 "Invalid" 196 "Invalid" 195 "Invalid" 194 "Invalid" 193 "Invalid" 192 "Invalid" 191 "Invalid" 190 "Invalid" 189 "Invalid" 188 "Invalid" 187 "Invalid" 186 "Invalid" 185 "Invalid" 184 "Invalid" 183 "Invalid" 182 "Invalid" 181 "Invalid" 180 "Invalid" 179 "Invalid" 178 "Invalid" 177 "Invalid" 176 "Invalid" 175 "Invalid" 174 "Invalid" 173 "Invalid" 172 "Invalid" 171 "Invalid" 170 "Invalid" 169 "Invalid" 168 "Invalid" 167 "Invalid" 166 "Invalid" 165 "Invalid" 164 "Invalid" 163 "Invalid" 162 "Invalid" 161 "Invalid" ;
VAL_ 1068 BCU_CellTmp066_RM 255 "Invalid" 254 "Invalid" 253 "Invalid" 252 "Invalid" 251 "Invalid" 250 "Invalid" 249 "Invalid" 248 "Invalid" 247 "Invalid" 246 "Invalid" 245 "Invalid" 244 "Invalid" 243 "Invalid" 242 "Invalid" 241 "Invalid" 240 "Invalid" 239 "Invalid" 238 "Invalid" 237 "Invalid" 236 "Invalid" 235 "Invalid" 234 "Invalid" 233 "Invalid" 232 "Invalid" 231 "Invalid" 230 "Invalid" 229 "Invalid" 228 "Invalid" 227 "Invalid" 226 "Invalid" 225 "Invalid" 224 "Invalid" 223 "Invalid" 222 "Invalid" 221 "Invalid" 220 "Invalid" 219 "Invalid" 218 "Invalid" 217 "Invalid" 216 "Invalid" 215 "Invalid" 214 "Invalid" 213 "Invalid" 212 "Invalid" 211 "Invalid" 210 "Invalid" 209 "Invalid" 208 "Invalid" 207 "Invalid" 206 "Invalid" 205 "Invalid" 204 "Invalid" 203 "Invalid" 202 "Invalid" 201 "Invalid" 200 "Invalid" 199 "Invalid" 198 "Invalid" 197 "Invalid" 196 "Invalid" 195 "Invalid" 194 "Invalid" 193 "Invalid" 192 "Invalid" 191 "Invalid" 190 "Invalid" 189 "Invalid" 188 "Invalid" 187 "Invalid" 186 "Invalid" 185 "Invalid" 184 "Invalid" 183 "Invalid" 182 "Invalid" 181 "Invalid" 180 "Invalid" 179 "Invalid" 178 "Invalid" 177 "Invalid" 176 "Invalid" 175 "Invalid" 174 "Invalid" 173 "Invalid" 172 "Invalid" 171 "Invalid" 170 "Invalid" 169 "Invalid" 168 "Invalid" 167 "Invalid" 166 "Invalid" 165 "Invalid" 164 "Invalid" 163 "Invalid" 162 "Invalid" 161 "Invalid" ;
VAL_ 1068 BCU_MaxModlTmp_RM 255 "Invalid" 254 "Invalid" 253 "Invalid" 252 "Invalid" 251 "Invalid" 250 "Invalid" 249 "Invalid" 248 "Invalid" 247 "Invalid" 246 "Invalid" 245 "Invalid" 244 "Invalid" 243 "Invalid" 242 "Invalid" 241 "Invalid" 240 "Invalid" 239 "Invalid" 238 "Invalid" 237 "Invalid" 236 "Invalid" 235 "Invalid" 234 "Invalid" 233 "Invalid" 232 "Invalid" 231 "Invalid" 230 "Invalid" 229 "Invalid" 228 "Invalid" 227 "Invalid" 226 "Invalid" 225 "Invalid" 224 "Invalid" 223 "Invalid" 222 "Invalid" 221 "Invalid" 220 "Invalid" 219 "Invalid" 218 "Invalid" 217 "Invalid" 216 "Invalid" 215 "Invalid" 214 "Invalid" 213 "Invalid" 212 "Invalid" 211 "Invalid" 210 "Invalid" 209 "Invalid" 208 "Invalid" 207 "Invalid" 206 "Invalid" 205 "Invalid" 204 "Invalid" 203 "Invalid" 202 "Invalid" 201 "Invalid" 200 "Invalid" 199 "Invalid" 198 "Invalid" 197 "Invalid" 196 "Invalid" 195 "Invalid" 194 "Invalid" 193 "Invalid" 192 "Invalid" 191 "Invalid" 190 "Invalid" 189 "Invalid" 188 "Invalid" 187 "Invalid" 186 "Invalid" 185 "Invalid" 184 "Invalid" 183 "Invalid" 182 "Invalid" 181 "Invalid" 180 "Invalid" 179 "Invalid" 178 "Invalid" 177 "Invalid" 176 "Invalid" 175 "Invalid" 174 "Invalid" 173 "Invalid" 172 "Invalid" 171 "Invalid" 170 "Invalid" 169 "Invalid" 168 "Invalid" 167 "Invalid" 166 "Invalid" 165 "Invalid" 164 "Invalid" 163 "Invalid" 162 "Invalid" 161 "Invalid" ;
VAL_ 1068 BCU_MinModlTmp_RM 255 "Invalid" 254 "Invalid" 253 "Invalid" 252 "Invalid" 251 "Invalid" 250 "Invalid" 249 "Invalid" 248 "Invalid" 247 "Invalid" 246 "Invalid" 245 "Invalid" 244 "Invalid" 243 "Invalid" 242 "Invalid" 241 "Invalid" 240 "Invalid" 239 "Invalid" 238 "Invalid" 237 "Invalid" 236 "Invalid" 235 "Invalid" 234 "Invalid" 233 "Invalid" 232 "Invalid" 231 "Invalid" 230 "Invalid" 229 "Invalid" 228 "Invalid" 227 "Invalid" 226 "Invalid" 225 "Invalid" 224 "Invalid" 223 "Invalid" 222 "Invalid" 221 "Invalid" 220 "Invalid" 219 "Invalid" 218 "Invalid" 217 "Invalid" 216 "Invalid" 215 "Invalid" 214 "Invalid" 213 "Invalid" 212 "Invalid" 211 "Invalid" 210 "Invalid" 209 "Invalid" 208 "Invalid" 207 "Invalid" 206 "Invalid" 205 "Invalid" 204 "Invalid" 203 "Invalid" 202 "Invalid" 201 "Invalid" 200 "Invalid" 199 "Invalid" 198 "Invalid" 197 "Invalid" 196 "Invalid" 195 "Invalid" 194 "Invalid" 193 "Invalid" 192 "Invalid" 191 "Invalid" 190 "Invalid" 189 "Invalid" 188 "Invalid" 187 "Invalid" 186 "Invalid" 185 "Invalid" 184 "Invalid" 183 "Invalid" 182 "Invalid" 181 "Invalid" 180 "Invalid" 179 "Invalid" 178 "Invalid" 177 "Invalid" 176 "Invalid" 175 "Invalid" 174 "Invalid" 173 "Invalid" 172 "Invalid" 171 "Invalid" 170 "Invalid" 169 "Invalid" 168 "Invalid" 167 "Invalid" 166 "Invalid" 165 "Invalid" 164 "Invalid" 163 "Invalid" 162 "Invalid" 161 "Invalid" ;
VAL_ 1068 BCU_MinModlTmpNr_RM 127 "Invalid" 126 "Invalid" 125 "Invalid" 124 "Invalid" 123 "Invalid" 122 "Invalid" 121 "Invalid" ;
VAL_ 1069 BCU_CellVlt097_RM 2047 "Invalid" 2046 "Invalid" 2045 "Invalid" 2044 "Invalid" 2043 "Invalid" 2042 "Invalid" 2041 "Invalid" 2040 "Invalid" 2039 "Invalid" 2038 "Invalid" 2037 "Invalid" 2036 "Invalid" 2035 "Invalid" 2034 "Invalid" 2033 "Invalid" 2032 "Invalid" 2031 "Invalid" 2030 "Invalid" 2029 "Invalid" 2028 "Invalid" 2027 "Invalid" 2026 "Invalid" 2025 "Invalid" 2024 "Invalid" 2023 "Invalid" 2022 "Invalid" 2021 "Invalid" 2020 "Invalid" 2019 "Invalid" 2018 "Invalid" 2017 "Invalid" 2016 "Invalid" 2015 "Invalid" 2014 "Invalid" 2013 "Invalid" 2012 "Invalid" 2011 "Invalid" 2010 "Invalid" 2009 "Invalid" 2008 "Invalid" 2007 "Invalid" 2006 "Invalid" 2005 "Invalid" 2004 "Invalid" 2003 "Invalid" 2002 "Invalid" 2001 "Invalid" 2000 "Invalid" 1999 "Invalid" 1998 "Invalid" 1997 "Invalid" 1996 "Invalid" 1995 "Invalid" 1994 "Invalid" 1993 "Invalid" 1992 "Invalid" 1991 "Invalid" 1990 "Invalid" 1989 "Invalid" 1988 "Invalid" 1987 "Invalid" 1986 "Invalid" 1985 "Invalid" 1984 "Invalid" 1983 "Invalid" 1982 "Invalid" 1981 "Invalid" 1980 "Invalid" 1979 "Invalid" 1978 "Invalid" 1977 "Invalid" 1976 "Invalid" 1975 "Invalid" 1974 "Invalid" 1973 "Invalid" 1972 "Invalid" 1971 "Invalid" 1970 "Invalid" 1969 "Invalid" 1968 "Invalid" 1967 "Invalid" 1966 "Invalid" 1965 "Invalid" 1964 "Invalid" 1963 "Invalid" 1962 "Invalid" 1961 "Invalid" 1960 "Invalid" 1959 "Invalid" 1958 "Invalid" 1957 "Invalid" 1956 "Invalid" 1955 "Invalid" 1954 "Invalid" 1953 "Invalid" 1952 "Invalid" 1951 "Invalid" 1950 "Invalid" 1949 "Invalid" 1948 "Invalid" 1947 "Invalid" 1946 "Invalid" 1945 "Invalid" 1944 "Invalid" 1943 "Invalid" 1942 "Invalid" 1941 "Invalid" 1940 "Invalid" 1939 "Invalid" 1938 "Invalid" 1937 "Invalid" 1936 "Invalid" 1935 "Invalid" 1934 "Invalid" 1933 "Invalid" 1932 "Invalid" 1931 "Invalid" 1930 "Invalid" 1929 "Invalid" 1928 "Invalid" 1927 "Invalid" 1926 "Invalid" 1925 "Invalid" 1924 "Invalid" 1923 "Invalid" 1922 "Invalid" 1921 "Invalid" 1920 "Invalid" 1919 "Invalid" 1918 "Invalid" 1917 "Invalid" 1916 "Invalid" 1915 "Invalid" 1914 "Invalid" 1913 "Invalid" 1912 "Invalid" 1911 "Invalid" 1910 "Invalid" 1909 "Invalid" 1908 "Invalid" 1907 "Invalid" 1906 "Invalid" 1905 "Invalid" 1904 "Invalid" 1903 "Invalid" 1902 "Invalid" 1901 "Invalid" 1900 "Invalid" 1899 "Invalid" 1898 "Invalid" 1897 "Invalid" 1896 "Invalid" 1895 "Invalid" 1894 "Invalid" 1893 "Invalid" 1892 "Invalid" 1891 "Invalid" 1890 "Invalid" 1889 "Invalid" 1888 "Invalid" 1887 "Invalid" 1886 "Invalid" 1885 "Invalid" 1884 "Invalid" 1883 "Invalid" 1882 "Invalid" 1881 "Invalid" 1880 "Invalid" 1879 "Invalid" 1878 "Invalid" 1877 "Invalid" 1876 "Invalid" 1875 "Invalid" 1874 "Invalid" 1873 "Invalid" 1872 "Invalid" 1871 "Invalid" 1870 "Invalid" 1869 "Invalid" 1868 "Invalid" 1867 "Invalid" 1866 "Invalid" 1865 "Invalid" 1864 "Invalid" 1863 "Invalid" 1862 "Invalid" 1861 "Invalid" 1860 "Invalid" 1859 "Invalid" 1858 "Invalid" 1857 "Invalid" 1856 "Invalid" 1855 "Invalid" 1854 "Invalid" 1853 "Invalid" 1852 "Invalid" 1851 "Invalid" 1850 "Invalid" 1849 "Invalid" 1848 "Invalid" 1847 "Invalid" 1846 "Invalid" 1845 "Invalid" 1844 "Invalid" 1843 "Invalid" 1842 "Invalid" 1841 "Invalid" 1840 "Invalid" 1839 "Invalid" 1838 "Invalid" 1837 "Invalid" 1836 "Invalid" 1835 "Invalid" 1834 "Invalid" 1833 "Invalid" 1832 "Invalid" 1831 "Invalid" 1830 "Invalid" 1829 "Invalid" 1828 "Invalid" 1827 "Invalid" 1826 "Invalid" 1825 "Invalid" 1824 "Invalid" 1823 "Invalid" 1822 "Invalid" 1821 "Invalid" 1820 "Invalid" 1819 "Invalid" 1818 "Invalid" 1817 "Invalid" 1816 "Invalid" 1815 "Invalid" 1814 "Invalid" 1813 "Invalid" 1812 "Invalid" 1811 "Invalid" 1810 "Invalid" 1809 "Invalid" 1808 "Invalid" 1807 "Invalid" 1806 "Invalid" 1805 "Invalid" 1804 "Invalid" 1803 "Invalid" 1802 "Invalid" 1801 "Invalid" ;
VAL_ 1069 BCU_CellVlt098_RM 2047 "Invalid" 2046 "Invalid" 2045 "Invalid" 2044 "Invalid" 2043 "Invalid" 2042 "Invalid" 2041 "Invalid" 2040 "Invalid" 2039 "Invalid" 2038 "Invalid" 2037 "Invalid" 2036 "Invalid" 2035 "Invalid" 2034 "Invalid" 2033 "Invalid" 2032 "Invalid" 2031 "Invalid" 2030 "Invalid" 2029 "Invalid" 2028 "Invalid" 2027 "Invalid" 2026 "Invalid" 2025 "Invalid" 2024 "Invalid" 2023 "Invalid" 2022 "Invalid" 2021 "Invalid" 2020 "Invalid" 2019 "Invalid" 2018 "Invalid" 2017 "Invalid" 2016 "Invalid" 2015 "Invalid" 2014 "Invalid" 2013 "Invalid" 2012 "Invalid" 2011 "Invalid" 2010 "Invalid" 2009 "Invalid" 2008 "Invalid" 2007 "Invalid" 2006 "Invalid" 2005 "Invalid" 2004 "Invalid" 2003 "Invalid" 2002 "Invalid" 2001 "Invalid" 2000 "Invalid" 1999 "Invalid" 1998 "Invalid" 1997 "Invalid" 1996 "Invalid" 1995 "Invalid" 1994 "Invalid" 1993 "Invalid" 1992 "Invalid" 1991 "Invalid" 1990 "Invalid" 1989 "Invalid" 1988 "Invalid" 1987 "Invalid" 1986 "Invalid" 1985 "Invalid" 1984 "Invalid" 1983 "Invalid" 1982 "Invalid" 1981 "Invalid" 1980 "Invalid" 1979 "Invalid" 1978 "Invalid" 1977 "Invalid" 1976 "Invalid" 1975 "Invalid" 1974 "Invalid" 1973 "Invalid" 1972 "Invalid" 1971 "Invalid" 1970 "Invalid" 1969 "Invalid" 1968 "Invalid" 1967 "Invalid" 1966 "Invalid" 1965 "Invalid" 1964 "Invalid" 1963 "Invalid" 1962 "Invalid" 1961 "Invalid" 1960 "Invalid" 1959 "Invalid" 1958 "Invalid" 1957 "Invalid" 1956 "Invalid" 1955 "Invalid" 1954 "Invalid" 1953 "Invalid" 1952 "Invalid" 1951 "Invalid" 1950 "Invalid" 1949 "Invalid" 1948 "Invalid" 1947 "Invalid" 1946 "Invalid" 1945 "Invalid" 1944 "Invalid" 1943 "Invalid" 1942 "Invalid" 1941 "Invalid" 1940 "Invalid" 1939 "Invalid" 1938 "Invalid" 1937 "Invalid" 1936 "Invalid" 1935 "Invalid" 1934 "Invalid" 1933 "Invalid" 1932 "Invalid" 1931 "Invalid" 1930 "Invalid" 1929 "Invalid" 1928 "Invalid" 1927 "Invalid" 1926 "Invalid" 1925 "Invalid" 1924 "Invalid" 1923 "Invalid" 1922 "Invalid" 1921 "Invalid" 1920 "Invalid" 1919 "Invalid" 1918 "Invalid" 1917 "Invalid" 1916 "Invalid" 1915 "Invalid" 1914 "Invalid" 1913 "Invalid" 1912 "Invalid" 1911 "Invalid" 1910 "Invalid" 1909 "Invalid" 1908 "Invalid" 1907 "Invalid" 1906 "Invalid" 1905 "Invalid" 1904 "Invalid" 1903 "Invalid" 1902 "Invalid" 1901 "Invalid" 1900 "Invalid" 1899 "Invalid" 1898 "Invalid" 1897 "Invalid" 1896 "Invalid" 1895 "Invalid" 1894 "Invalid" 1893 "Invalid" 1892 "Invalid" 1891 "Invalid" 1890 "Invalid" 1889 "Invalid" 1888 "Invalid" 1887 "Invalid" 1886 "Invalid" 1885 "Invalid" 1884 "Invalid" 1883 "Invalid" 1882 "Invalid" 1881 "Invalid" 1880 "Invalid" 1879 "Invalid" 1878 "Invalid" 1877 "Invalid" 1876 "Invalid" 1875 "Invalid" 1874 "Invalid" 1873 "Invalid" 1872 "Invalid" 1871 "Invalid" 1870 "Invalid" 1869 "Invalid" 1868 "Invalid" 1867 "Invalid" 1866 "Invalid" 1865 "Invalid" 1864 "Invalid" 1863 "Invalid" 1862 "Invalid" 1861 "Invalid" 1860 "Invalid" 1859 "Invalid" 1858 "Invalid" 1857 "Invalid" 1856 "Invalid" 1855 "Invalid" 1854 "Invalid" 1853 "Invalid" 1852 "Invalid" 1851 "Invalid" 1850 "Invalid" 1849 "Invalid" 1848 "Invalid" 1847 "Invalid" 1846 "Invalid" 1845 "Invalid" 1844 "Invalid" 1843 "Invalid" 1842 "Invalid" 1841 "Invalid" 1840 "Invalid" 1839 "Invalid" 1838 "Invalid" 1837 "Invalid" 1836 "Invalid" 1835 "Invalid" 1834 "Invalid" 1833 "Invalid" 1832 "Invalid" 1831 "Invalid" 1830 "Invalid" 1829 "Invalid" 1828 "Invalid" 1827 "Invalid" 1826 "Invalid" 1825 "Invalid" 1824 "Invalid" 1823 "Invalid" 1822 "Invalid" 1821 "Invalid" 1820 "Invalid" 1819 "Invalid" 1818 "Invalid" 1817 "Invalid" 1816 "Invalid" 1815 "Invalid" 1814 "Invalid" 1813 "Invalid" 1812 "Invalid" 1811 "Invalid" 1810 "Invalid" 1809 "Invalid" 1808 "Invalid" 1807 "Invalid" 1806 "Invalid" 1805 "Invalid" 1804 "Invalid" 1803 "Invalid" 1802 "Invalid" 1801 "Invalid" ;
VAL_ 1069 BCU_CellVlt099_RM 2047 "Invalid" 2046 "Invalid" 2045 "Invalid" 2044 "Invalid" 2043 "Invalid" 2042 "Invalid" 2041 "Invalid" 2040 "Invalid" 2039 "Invalid" 2038 "Invalid" 2037 "Invalid" 2036 "Invalid" 2035 "Invalid" 2034 "Invalid" 2033 "Invalid" 2032 "Invalid" 2031 "Invalid" 2030 "Invalid" 2029 "Invalid" 2028 "Invalid" 2027 "Invalid" 2026 "Invalid" 2025 "Invalid" 2024 "Invalid" 2023 "Invalid" 2022 "Invalid" 2021 "Invalid" 2020 "Invalid" 2019 "Invalid" 2018 "Invalid" 2017 "Invalid" 2016 "Invalid" 2015 "Invalid" 2014 "Invalid" 2013 "Invalid" 2012 "Invalid" 2011 "Invalid" 2010 "Invalid" 2009 "Invalid" 2008 "Invalid" 2007 "Invalid" 2006 "Invalid" 2005 "Invalid" 2004 "Invalid" 2003 "Invalid" 2002 "Invalid" 2001 "Invalid" 2000 "Invalid" 1999 "Invalid" 1998 "Invalid" 1997 "Invalid" 1996 "Invalid" 1995 "Invalid" 1994 "Invalid" 1993 "Invalid" 1992 "Invalid" 1991 "Invalid" 1990 "Invalid" 1989 "Invalid" 1988 "Invalid" 1987 "Invalid" 1986 "Invalid" 1985 "Invalid" 1984 "Invalid" 1983 "Invalid" 1982 "Invalid" 1981 "Invalid" 1980 "Invalid" 1979 "Invalid" 1978 "Invalid" 1977 "Invalid" 1976 "Invalid" 1975 "Invalid" 1974 "Invalid" 1973 "Invalid" 1972 "Invalid" 1971 "Invalid" 1970 "Invalid" 1969 "Invalid" 1968 "Invalid" 1967 "Invalid" 1966 "Invalid" 1965 "Invalid" 1964 "Invalid" 1963 "Invalid" 1962 "Invalid" 1961 "Invalid" 1960 "Invalid" 1959 "Invalid" 1958 "Invalid" 1957 "Invalid" 1956 "Invalid" 1955 "Invalid" 1954 "Invalid" 1953 "Invalid" 1952 "Invalid" 1951 "Invalid" 1950 "Invalid" 1949 "Invalid" 1948 "Invalid" 1947 "Invalid" 1946 "Invalid" 1945 "Invalid" 1944 "Invalid" 1943 "Invalid" 1942 "Invalid" 1941 "Invalid" 1940 "Invalid" 1939 "Invalid" 1938 "Invalid" 1937 "Invalid" 1936 "Invalid" 1935 "Invalid" 1934 "Invalid" 1933 "Invalid" 1932 "Invalid" 1931 "Invalid" 1930 "Invalid" 1929 "Invalid" 1928 "Invalid" 1927 "Invalid" 1926 "Invalid" 1925 "Invalid" 1924 "Invalid" 1923 "Invalid" 1922 "Invalid" 1921 "Invalid" 1920 "Invalid" 1919 "Invalid" 1918 "Invalid" 1917 "Invalid" 1916 "Invalid" 1915 "Invalid" 1914 "Invalid" 1913 "Invalid" 1912 "Invalid" 1911 "Invalid" 1910 "Invalid" 1909 "Invalid" 1908 "Invalid" 1907 "Invalid" 1906 "Invalid" 1905 "Invalid" 1904 "Invalid" 1903 "Invalid" 1902 "Invalid" 1901 "Invalid" 1900 "Invalid" 1899 "Invalid" 1898 "Invalid" 1897 "Invalid" 1896 "Invalid" 1895 "Invalid" 1894 "Invalid" 1893 "Invalid" 1892 "Invalid" 1891 "Invalid" 1890 "Invalid" 1889 "Invalid" 1888 "Invalid" 1887 "Invalid" 1886 "Invalid" 1885 "Invalid" 1884 "Invalid" 1883 "Invalid" 1882 "Invalid" 1881 "Invalid" 1880 "Invalid" 1879 "Invalid" 1878 "Invalid" 1877 "Invalid" 1876 "Invalid" 1875 "Invalid" 1874 "Invalid" 1873 "Invalid" 1872 "Invalid" 1871 "Invalid" 1870 "Invalid" 1869 "Invalid" 1868 "Invalid" 1867 "Invalid" 1866 "Invalid" 1865 "Invalid" 1864 "Invalid" 1863 "Invalid" 1862 "Invalid" 1861 "Invalid" 1860 "Invalid" 1859 "Invalid" 1858 "Invalid" 1857 "Invalid" 1856 "Invalid" 1855 "Invalid" 1854 "Invalid" 1853 "Invalid" 1852 "Invalid" 1851 "Invalid" 1850 "Invalid" 1849 "Invalid" 1848 "Invalid" 1847 "Invalid" 1846 "Invalid" 1845 "Invalid" 1844 "Invalid" 1843 "Invalid" 1842 "Invalid" 1841 "Invalid" 1840 "Invalid" 1839 "Invalid" 1838 "Invalid" 1837 "Invalid" 1836 "Invalid" 1835 "Invalid" 1834 "Invalid" 1833 "Invalid" 1832 "Invalid" 1831 "Invalid" 1830 "Invalid" 1829 "Invalid" 1828 "Invalid" 1827 "Invalid" 1826 "Invalid" 1825 "Invalid" 1824 "Invalid" 1823 "Invalid" 1822 "Invalid" 1821 "Invalid" 1820 "Invalid" 1819 "Invalid" 1818 "Invalid" 1817 "Invalid" 1816 "Invalid" 1815 "Invalid" 1814 "Invalid" 1813 "Invalid" 1812 "Invalid" 1811 "Invalid" 1810 "Invalid" 1809 "Invalid" 1808 "Invalid" 1807 "Invalid" 1806 "Invalid" 1805 "Invalid" 1804 "Invalid" 1803 "Invalid" 1802 "Invalid" 1801 "Invalid" ;
VAL_ 1069 BCU_CellVlt100_RM 2047 "Invalid" 2046 "Invalid" 2045 "Invalid" 2044 "Invalid" 2043 "Invalid" 2042 "Invalid" 2041 "Invalid" 2040 "Invalid" 2039 "Invalid" 2038 "Invalid" 2037 "Invalid" 2036 "Invalid" 2035 "Invalid" 2034 "Invalid" 2033 "Invalid" 2032 "Invalid" 2031 "Invalid" 2030 "Invalid" 2029 "Invalid" 2028 "Invalid" 2027 "Invalid" 2026 "Invalid" 2025 "Invalid" 2024 "Invalid" 2023 "Invalid" 2022 "Invalid" 2021 "Invalid" 2020 "Invalid" 2019 "Invalid" 2018 "Invalid" 2017 "Invalid" 2016 "Invalid" 2015 "Invalid" 2014 "Invalid" 2013 "Invalid" 2012 "Invalid" 2011 "Invalid" 2010 "Invalid" 2009 "Invalid" 2008 "Invalid" 2007 "Invalid" 2006 "Invalid" 2005 "Invalid" 2004 "Invalid" 2003 "Invalid" 2002 "Invalid" 2001 "Invalid" 2000 "Invalid" 1999 "Invalid" 1998 "Invalid" 1997 "Invalid" 1996 "Invalid" 1995 "Invalid" 1994 "Invalid" 1993 "Invalid" 1992 "Invalid" 1991 "Invalid" 1990 "Invalid" 1989 "Invalid" 1988 "Invalid" 1987 "Invalid" 1986 "Invalid" 1985 "Invalid" 1984 "Invalid" 1983 "Invalid" 1982 "Invalid" 1981 "Invalid" 1980 "Invalid" 1979 "Invalid" 1978 "Invalid" 1977 "Invalid" 1976 "Invalid" 1975 "Invalid" 1974 "Invalid" 1973 "Invalid" 1972 "Invalid" 1971 "Invalid" 1970 "Invalid" 1969 "Invalid" 1968 "Invalid" 1967 "Invalid" 1966 "Invalid" 1965 "Invalid" 1964 "Invalid" 1963 "Invalid" 1962 "Invalid" 1961 "Invalid" 1960 "Invalid" 1959 "Invalid" 1958 "Invalid" 1957 "Invalid" 1956 "Invalid" 1955 "Invalid" 1954 "Invalid" 1953 "Invalid" 1952 "Invalid" 1951 "Invalid" 1950 "Invalid" 1949 "Invalid" 1948 "Invalid" 1947 "Invalid" 1946 "Invalid" 1945 "Invalid" 1944 "Invalid" 1943 "Invalid" 1942 "Invalid" 1941 "Invalid" 1940 "Invalid" 1939 "Invalid" 1938 "Invalid" 1937 "Invalid" 1936 "Invalid" 1935 "Invalid" 1934 "Invalid" 1933 "Invalid" 1932 "Invalid" 1931 "Invalid" 1930 "Invalid" 1929 "Invalid" 1928 "Invalid" 1927 "Invalid" 1926 "Invalid" 1925 "Invalid" 1924 "Invalid" 1923 "Invalid" 1922 "Invalid" 1921 "Invalid" 1920 "Invalid" 1919 "Invalid" 1918 "Invalid" 1917 "Invalid" 1916 "Invalid" 1915 "Invalid" 1914 "Invalid" 1913 "Invalid" 1912 "Invalid" 1911 "Invalid" 1910 "Invalid" 1909 "Invalid" 1908 "Invalid" 1907 "Invalid" 1906 "Invalid" 1905 "Invalid" 1904 "Invalid" 1903 "Invalid" 1902 "Invalid" 1901 "Invalid" 1900 "Invalid" 1899 "Invalid" 1898 "Invalid" 1897 "Invalid" 1896 "Invalid" 1895 "Invalid" 1894 "Invalid" 1893 "Invalid" 1892 "Invalid" 1891 "Invalid" 1890 "Invalid" 1889 "Invalid" 1888 "Invalid" 1887 "Invalid" 1886 "Invalid" 1885 "Invalid" 1884 "Invalid" 1883 "Invalid" 1882 "Invalid" 1881 "Invalid" 1880 "Invalid" 1879 "Invalid" 1878 "Invalid" 1877 "Invalid" 1876 "Invalid" 1875 "Invalid" 1874 "Invalid" 1873 "Invalid" 1872 "Invalid" 1871 "Invalid" 1870 "Invalid" 1869 "Invalid" 1868 "Invalid" 1867 "Invalid" 1866 "Invalid" 1865 "Invalid" 1864 "Invalid" 1863 "Invalid" 1862 "Invalid" 1861 "Invalid" 1860 "Invalid" 1859 "Invalid" 1858 "Invalid" 1857 "Invalid" 1856 "Invalid" 1855 "Invalid" 1854 "Invalid" 1853 "Invalid" 1852 "Invalid" 1851 "Invalid" 1850 "Invalid" 1849 "Invalid" 1848 "Invalid" 1847 "Invalid" 1846 "Invalid" 1845 "Invalid" 1844 "Invalid" 1843 "Invalid" 1842 "Invalid" 1841 "Invalid" 1840 "Invalid" 1839 "Invalid" 1838 "Invalid" 1837 "Invalid" 1836 "Invalid" 1835 "Invalid" 1834 "Invalid" 1833 "Invalid" 1832 "Invalid" 1831 "Invalid" 1830 "Invalid" 1829 "Invalid" 1828 "Invalid" 1827 "Invalid" 1826 "Invalid" 1825 "Invalid" 1824 "Invalid" 1823 "Invalid" 1822 "Invalid" 1821 "Invalid" 1820 "Invalid" 1819 "Invalid" 1818 "Invalid" 1817 "Invalid" 1816 "Invalid" 1815 "Invalid" 1814 "Invalid" 1813 "Invalid" 1812 "Invalid" 1811 "Invalid" 1810 "Invalid" 1809 "Invalid" 1808 "Invalid" 1807 "Invalid" 1806 "Invalid" 1805 "Invalid" 1804 "Invalid" 1803 "Invalid" 1802 "Invalid" 1801 "Invalid" ;
VAL_ 1069 BCU_CellVlt0101_RM 2047 "Invalid" 2046 "Invalid" 2045 "Invalid" 2044 "Invalid" 2043 "Invalid" 2042 "Invalid" 2041 "Invalid" 2040 "Invalid" 2039 "Invalid" 2038 "Invalid" 2037 "Invalid" 2036 "Invalid" 2035 "Invalid" 2034 "Invalid" 2033 "Invalid" 2032 "Invalid" 2031 "Invalid" 2030 "Invalid" 2029 "Invalid" 2028 "Invalid" 2027 "Invalid" 2026 "Invalid" 2025 "Invalid" 2024 "Invalid" 2023 "Invalid" 2022 "Invalid" 2021 "Invalid" 2020 "Invalid" 2019 "Invalid" 2018 "Invalid" 2017 "Invalid" 2016 "Invalid" 2015 "Invalid" 2014 "Invalid" 2013 "Invalid" 2012 "Invalid" 2011 "Invalid" 2010 "Invalid" 2009 "Invalid" 2008 "Invalid" 2007 "Invalid" 2006 "Invalid" 2005 "Invalid" 2004 "Invalid" 2003 "Invalid" 2002 "Invalid" 2001 "Invalid" 2000 "Invalid" 1999 "Invalid" 1998 "Invalid" 1997 "Invalid" 1996 "Invalid" 1995 "Invalid" 1994 "Invalid" 1993 "Invalid" 1992 "Invalid" 1991 "Invalid" 1990 "Invalid" 1989 "Invalid" 1988 "Invalid" 1987 "Invalid" 1986 "Invalid" 1985 "Invalid" 1984 "Invalid" 1983 "Invalid" 1982 "Invalid" 1981 "Invalid" 1980 "Invalid" 1979 "Invalid" 1978 "Invalid" 1977 "Invalid" 1976 "Invalid" 1975 "Invalid" 1974 "Invalid" 1973 "Invalid" 1972 "Invalid" 1971 "Invalid" 1970 "Invalid" 1969 "Invalid" 1968 "Invalid" 1967 "Invalid" 1966 "Invalid" 1965 "Invalid" 1964 "Invalid" 1963 "Invalid" 1962 "Invalid" 1961 "Invalid" 1960 "Invalid" 1959 "Invalid" 1958 "Invalid" 1957 "Invalid" 1956 "Invalid" 1955 "Invalid" 1954 "Invalid" 1953 "Invalid" 1952 "Invalid" 1951 "Invalid" 1950 "Invalid" 1949 "Invalid" 1948 "Invalid" 1947 "Invalid" 1946 "Invalid" 1945 "Invalid" 1944 "Invalid" 1943 "Invalid" 1942 "Invalid" 1941 "Invalid" 1940 "Invalid" 1939 "Invalid" 1938 "Invalid" 1937 "Invalid" 1936 "Invalid" 1935 "Invalid" 1934 "Invalid" 1933 "Invalid" 1932 "Invalid" 1931 "Invalid" 1930 "Invalid" 1929 "Invalid" 1928 "Invalid" 1927 "Invalid" 1926 "Invalid" 1925 "Invalid" 1924 "Invalid" 1923 "Invalid" 1922 "Invalid" 1921 "Invalid" 1920 "Invalid" 1919 "Invalid" 1918 "Invalid" 1917 "Invalid" 1916 "Invalid" 1915 "Invalid" 1914 "Invalid" 1913 "Invalid" 1912 "Invalid" 1911 "Invalid" 1910 "Invalid" 1909 "Invalid" 1908 "Invalid" 1907 "Invalid" 1906 "Invalid" 1905 "Invalid" 1904 "Invalid" 1903 "Invalid" 1902 "Invalid" 1901 "Invalid" 1900 "Invalid" 1899 "Invalid" 1898 "Invalid" 1897 "Invalid" 1896 "Invalid" 1895 "Invalid" 1894 "Invalid" 1893 "Invalid" 1892 "Invalid" 1891 "Invalid" 1890 "Invalid" 1889 "Invalid" 1888 "Invalid" 1887 "Invalid" 1886 "Invalid" 1885 "Invalid" 1884 "Invalid" 1883 "Invalid" 1882 "Invalid" 1881 "Invalid" 1880 "Invalid" 1879 "Invalid" 1878 "Invalid" 1877 "Invalid" 1876 "Invalid" 1875 "Invalid" 1874 "Invalid" 1873 "Invalid" 1872 "Invalid" 1871 "Invalid" 1870 "Invalid" 1869 "Invalid" 1868 "Invalid" 1867 "Invalid" 1866 "Invalid" 1865 "Invalid" 1864 "Invalid" 1863 "Invalid" 1862 "Invalid" 1861 "Invalid" 1860 "Invalid" 1859 "Invalid" 1858 "Invalid" 1857 "Invalid" 1856 "Invalid" 1855 "Invalid" 1854 "Invalid" 1853 "Invalid" 1852 "Invalid" 1851 "Invalid" 1850 "Invalid" 1849 "Invalid" 1848 "Invalid" 1847 "Invalid" 1846 "Invalid" 1845 "Invalid" 1844 "Invalid" 1843 "Invalid" 1842 "Invalid" 1841 "Invalid" 1840 "Invalid" 1839 "Invalid" 1838 "Invalid" 1837 "Invalid" 1836 "Invalid" 1835 "Invalid" 1834 "Invalid" 1833 "Invalid" 1832 "Invalid" 1831 "Invalid" 1830 "Invalid" 1829 "Invalid" 1828 "Invalid" 1827 "Invalid" 1826 "Invalid" 1825 "Invalid" 1824 "Invalid" 1823 "Invalid" 1822 "Invalid" 1821 "Invalid" 1820 "Invalid" 1819 "Invalid" 1818 "Invalid" 1817 "Invalid" 1816 "Invalid" 1815 "Invalid" 1814 "Invalid" 1813 "Invalid" 1812 "Invalid" 1811 "Invalid" 1810 "Invalid" 1809 "Invalid" 1808 "Invalid" 1807 "Invalid" 1806 "Invalid" 1805 "Invalid" 1804 "Invalid" 1803 "Invalid" 1802 "Invalid" 1801 "Invalid" ;
VAL_ 1069 BCU_BalnFlg099_RM 1 "Balance Closed" 0 "Balance Open" ;
VAL_ 1069 BCU_BalnFlg100_RM 1 "Balance Closed" 0 "Balance Open" ;
VAL_ 1069 BCU_BalnFlg101_RM 1 "Balance Closed" 0 "Balance Open" ;
VAL_ 1069 BCU_BalnFlg102_RM 1 "Balance Closed" 0 "Balance Open" ;
VAL_ 1069 BCU_BalnFlg103_RM 1 "Balance Closed" 0 "Balance Open" ;
VAL_ 1069 BCU_BalnFlg104_RM 1 "Balance Closed" 0 "Balance Open" ;
VAL_ 1069 BCU_BalnFlg105_RM 1 "Balance Closed" 0 "Balance Open" ;
VAL_ 1070 BCU_CellVlt102_RM 2047 "Invalid" 2046 "Invalid" 2045 "Invalid" 2044 "Invalid" 2043 "Invalid" 2042 "Invalid" 2041 "Invalid" 2040 "Invalid" 2039 "Invalid" 2038 "Invalid" 2037 "Invalid" 2036 "Invalid" 2035 "Invalid" 2034 "Invalid" 2033 "Invalid" 2032 "Invalid" 2031 "Invalid" 2030 "Invalid" 2029 "Invalid" 2028 "Invalid" 2027 "Invalid" 2026 "Invalid" 2025 "Invalid" 2024 "Invalid" 2023 "Invalid" 2022 "Invalid" 2021 "Invalid" 2020 "Invalid" 2019 "Invalid" 2018 "Invalid" 2017 "Invalid" 2016 "Invalid" 2015 "Invalid" 2014 "Invalid" 2013 "Invalid" 2012 "Invalid" 2011 "Invalid" 2010 "Invalid" 2009 "Invalid" 2008 "Invalid" 2007 "Invalid" 2006 "Invalid" 2005 "Invalid" 2004 "Invalid" 2003 "Invalid" 2002 "Invalid" 2001 "Invalid" 2000 "Invalid" 1999 "Invalid" 1998 "Invalid" 1997 "Invalid" 1996 "Invalid" 1995 "Invalid" 1994 "Invalid" 1993 "Invalid" 1992 "Invalid" 1991 "Invalid" 1990 "Invalid" 1989 "Invalid" 1988 "Invalid" 1987 "Invalid" 1986 "Invalid" 1985 "Invalid" 1984 "Invalid" 1983 "Invalid" 1982 "Invalid" 1981 "Invalid" 1980 "Invalid" 1979 "Invalid" 1978 "Invalid" 1977 "Invalid" 1976 "Invalid" 1975 "Invalid" 1974 "Invalid" 1973 "Invalid" 1972 "Invalid" 1971 "Invalid" 1970 "Invalid" 1969 "Invalid" 1968 "Invalid" 1967 "Invalid" 1966 "Invalid" 1965 "Invalid" 1964 "Invalid" 1963 "Invalid" 1962 "Invalid" 1961 "Invalid" 1960 "Invalid" 1959 "Invalid" 1958 "Invalid" 1957 "Invalid" 1956 "Invalid" 1955 "Invalid" 1954 "Invalid" 1953 "Invalid" 1952 "Invalid" 1951 "Invalid" 1950 "Invalid" 1949 "Invalid" 1948 "Invalid" 1947 "Invalid" 1946 "Invalid" 1945 "Invalid" 1944 "Invalid" 1943 "Invalid" 1942 "Invalid" 1941 "Invalid" 1940 "Invalid" 1939 "Invalid" 1938 "Invalid" 1937 "Invalid" 1936 "Invalid" 1935 "Invalid" 1934 "Invalid" 1933 "Invalid" 1932 "Invalid" 1931 "Invalid" 1930 "Invalid" 1929 "Invalid" 1928 "Invalid" 1927 "Invalid" 1926 "Invalid" 1925 "Invalid" 1924 "Invalid" 1923 "Invalid" 1922 "Invalid" 1921 "Invalid" 1920 "Invalid" 1919 "Invalid" 1918 "Invalid" 1917 "Invalid" 1916 "Invalid" 1915 "Invalid" 1914 "Invalid" 1913 "Invalid" 1912 "Invalid" 1911 "Invalid" 1910 "Invalid" 1909 "Invalid" 1908 "Invalid" 1907 "Invalid" 1906 "Invalid" 1905 "Invalid" 1904 "Invalid" 1903 "Invalid" 1902 "Invalid" 1901 "Invalid" 1900 "Invalid" 1899 "Invalid" 1898 "Invalid" 1897 "Invalid" 1896 "Invalid" 1895 "Invalid" 1894 "Invalid" 1893 "Invalid" 1892 "Invalid" 1891 "Invalid" 1890 "Invalid" 1889 "Invalid" 1888 "Invalid" 1887 "Invalid" 1886 "Invalid" 1885 "Invalid" 1884 "Invalid" 1883 "Invalid" 1882 "Invalid" 1881 "Invalid" 1880 "Invalid" 1879 "Invalid" 1878 "Invalid" 1877 "Invalid" 1876 "Invalid" 1875 "Invalid" 1874 "Invalid" 1873 "Invalid" 1872 "Invalid" 1871 "Invalid" 1870 "Invalid" 1869 "Invalid" 1868 "Invalid" 1867 "Invalid" 1866 "Invalid" 1865 "Invalid" 1864 "Invalid" 1863 "Invalid" 1862 "Invalid" 1861 "Invalid" 1860 "Invalid" 1859 "Invalid" 1858 "Invalid" 1857 "Invalid" 1856 "Invalid" 1855 "Invalid" 1854 "Invalid" 1853 "Invalid" 1852 "Invalid" 1851 "Invalid" 1850 "Invalid" 1849 "Invalid" 1848 "Invalid" 1847 "Invalid" 1846 "Invalid" 1845 "Invalid" 1844 "Invalid" 1843 "Invalid" 1842 "Invalid" 1841 "Invalid" 1840 "Invalid" 1839 "Invalid" 1838 "Invalid" 1837 "Invalid" 1836 "Invalid" 1835 "Invalid" 1834 "Invalid" 1833 "Invalid" 1832 "Invalid" 1831 "Invalid" 1830 "Invalid" 1829 "Invalid" 1828 "Invalid" 1827 "Invalid" 1826 "Invalid" 1825 "Invalid" 1824 "Invalid" 1823 "Invalid" 1822 "Invalid" 1821 "Invalid" 1820 "Invalid" 1819 "Invalid" 1818 "Invalid" 1817 "Invalid" 1816 "Invalid" 1815 "Invalid" 1814 "Invalid" 1813 "Invalid" 1812 "Invalid" 1811 "Invalid" 1810 "Invalid" 1809 "Invalid" 1808 "Invalid" 1807 "Invalid" 1806 "Invalid" 1805 "Invalid" 1804 "Invalid" 1803 "Invalid" 1802 "Invalid" 1801 "Invalid" ;
VAL_ 1070 BCU_CellVlt103_RM 2047 "Invalid" 2046 "Invalid" 2045 "Invalid" 2044 "Invalid" 2043 "Invalid" 2042 "Invalid" 2041 "Invalid" 2040 "Invalid" 2039 "Invalid" 2038 "Invalid" 2037 "Invalid" 2036 "Invalid" 2035 "Invalid" 2034 "Invalid" 2033 "Invalid" 2032 "Invalid" 2031 "Invalid" 2030 "Invalid" 2029 "Invalid" 2028 "Invalid" 2027 "Invalid" 2026 "Invalid" 2025 "Invalid" 2024 "Invalid" 2023 "Invalid" 2022 "Invalid" 2021 "Invalid" 2020 "Invalid" 2019 "Invalid" 2018 "Invalid" 2017 "Invalid" 2016 "Invalid" 2015 "Invalid" 2014 "Invalid" 2013 "Invalid" 2012 "Invalid" 2011 "Invalid" 2010 "Invalid" 2009 "Invalid" 2008 "Invalid" 2007 "Invalid" 2006 "Invalid" 2005 "Invalid" 2004 "Invalid" 2003 "Invalid" 2002 "Invalid" 2001 "Invalid" 2000 "Invalid" 1999 "Invalid" 1998 "Invalid" 1997 "Invalid" 1996 "Invalid" 1995 "Invalid" 1994 "Invalid" 1993 "Invalid" 1992 "Invalid" 1991 "Invalid" 1990 "Invalid" 1989 "Invalid" 1988 "Invalid" 1987 "Invalid" 1986 "Invalid" 1985 "Invalid" 1984 "Invalid" 1983 "Invalid" 1982 "Invalid" 1981 "Invalid" 1980 "Invalid" 1979 "Invalid" 1978 "Invalid" 1977 "Invalid" 1976 "Invalid" 1975 "Invalid" 1974 "Invalid" 1973 "Invalid" 1972 "Invalid" 1971 "Invalid" 1970 "Invalid" 1969 "Invalid" 1968 "Invalid" 1967 "Invalid" 1966 "Invalid" 1965 "Invalid" 1964 "Invalid" 1963 "Invalid" 1962 "Invalid" 1961 "Invalid" 1960 "Invalid" 1959 "Invalid" 1958 "Invalid" 1957 "Invalid" 1956 "Invalid" 1955 "Invalid" 1954 "Invalid" 1953 "Invalid" 1952 "Invalid" 1951 "Invalid" 1950 "Invalid" 1949 "Invalid" 1948 "Invalid" 1947 "Invalid" 1946 "Invalid" 1945 "Invalid" 1944 "Invalid" 1943 "Invalid" 1942 "Invalid" 1941 "Invalid" 1940 "Invalid" 1939 "Invalid" 1938 "Invalid" 1937 "Invalid" 1936 "Invalid" 1935 "Invalid" 1934 "Invalid" 1933 "Invalid" 1932 "Invalid" 1931 "Invalid" 1930 "Invalid" 1929 "Invalid" 1928 "Invalid" 1927 "Invalid" 1926 "Invalid" 1925 "Invalid" 1924 "Invalid" 1923 "Invalid" 1922 "Invalid" 1921 "Invalid" 1920 "Invalid" 1919 "Invalid" 1918 "Invalid" 1917 "Invalid" 1916 "Invalid" 1915 "Invalid" 1914 "Invalid" 1913 "Invalid" 1912 "Invalid" 1911 "Invalid" 1910 "Invalid" 1909 "Invalid" 1908 "Invalid" 1907 "Invalid" 1906 "Invalid" 1905 "Invalid" 1904 "Invalid" 1903 "Invalid" 1902 "Invalid" 1901 "Invalid" 1900 "Invalid" 1899 "Invalid" 1898 "Invalid" 1897 "Invalid" 1896 "Invalid" 1895 "Invalid" 1894 "Invalid" 1893 "Invalid" 1892 "Invalid" 1891 "Invalid" 1890 "Invalid" 1889 "Invalid" 1888 "Invalid" 1887 "Invalid" 1886 "Invalid" 1885 "Invalid" 1884 "Invalid" 1883 "Invalid" 1882 "Invalid" 1881 "Invalid" 1880 "Invalid" 1879 "Invalid" 1878 "Invalid" 1877 "Invalid" 1876 "Invalid" 1875 "Invalid" 1874 "Invalid" 1873 "Invalid" 1872 "Invalid" 1871 "Invalid" 1870 "Invalid" 1869 "Invalid" 1868 "Invalid" 1867 "Invalid" 1866 "Invalid" 1865 "Invalid" 1864 "Invalid" 1863 "Invalid" 1862 "Invalid" 1861 "Invalid" 1860 "Invalid" 1859 "Invalid" 1858 "Invalid" 1857 "Invalid" 1856 "Invalid" 1855 "Invalid" 1854 "Invalid" 1853 "Invalid" 1852 "Invalid" 1851 "Invalid" 1850 "Invalid" 1849 "Invalid" 1848 "Invalid" 1847 "Invalid" 1846 "Invalid" 1845 "Invalid" 1844 "Invalid" 1843 "Invalid" 1842 "Invalid" 1841 "Invalid" 1840 "Invalid" 1839 "Invalid" 1838 "Invalid" 1837 "Invalid" 1836 "Invalid" 1835 "Invalid" 1834 "Invalid" 1833 "Invalid" 1832 "Invalid" 1831 "Invalid" 1830 "Invalid" 1829 "Invalid" 1828 "Invalid" 1827 "Invalid" 1826 "Invalid" 1825 "Invalid" 1824 "Invalid" 1823 "Invalid" 1822 "Invalid" 1821 "Invalid" 1820 "Invalid" 1819 "Invalid" 1818 "Invalid" 1817 "Invalid" 1816 "Invalid" 1815 "Invalid" 1814 "Invalid" 1813 "Invalid" 1812 "Invalid" 1811 "Invalid" 1810 "Invalid" 1809 "Invalid" 1808 "Invalid" 1807 "Invalid" 1806 "Invalid" 1805 "Invalid" 1804 "Invalid" 1803 "Invalid" 1802 "Invalid" 1801 "Invalid" ;
VAL_ 1070 BCU_CellVlt104_RM 2047 "Invalid" 2046 "Invalid" 2045 "Invalid" 2044 "Invalid" 2043 "Invalid" 2042 "Invalid" 2041 "Invalid" 2040 "Invalid" 2039 "Invalid" 2038 "Invalid" 2037 "Invalid" 2036 "Invalid" 2035 "Invalid" 2034 "Invalid" 2033 "Invalid" 2032 "Invalid" 2031 "Invalid" 2030 "Invalid" 2029 "Invalid" 2028 "Invalid" 2027 "Invalid" 2026 "Invalid" 2025 "Invalid" 2024 "Invalid" 2023 "Invalid" 2022 "Invalid" 2021 "Invalid" 2020 "Invalid" 2019 "Invalid" 2018 "Invalid" 2017 "Invalid" 2016 "Invalid" 2015 "Invalid" 2014 "Invalid" 2013 "Invalid" 2012 "Invalid" 2011 "Invalid" 2010 "Invalid" 2009 "Invalid" 2008 "Invalid" 2007 "Invalid" 2006 "Invalid" 2005 "Invalid" 2004 "Invalid" 2003 "Invalid" 2002 "Invalid" 2001 "Invalid" 2000 "Invalid" 1999 "Invalid" 1998 "Invalid" 1997 "Invalid" 1996 "Invalid" 1995 "Invalid" 1994 "Invalid" 1993 "Invalid" 1992 "Invalid" 1991 "Invalid" 1990 "Invalid" 1989 "Invalid" 1988 "Invalid" 1987 "Invalid" 1986 "Invalid" 1985 "Invalid" 1984 "Invalid" 1983 "Invalid" 1982 "Invalid" 1981 "Invalid" 1980 "Invalid" 1979 "Invalid" 1978 "Invalid" 1977 "Invalid" 1976 "Invalid" 1975 "Invalid" 1974 "Invalid" 1973 "Invalid" 1972 "Invalid" 1971 "Invalid" 1970 "Invalid" 1969 "Invalid" 1968 "Invalid" 1967 "Invalid" 1966 "Invalid" 1965 "Invalid" 1964 "Invalid" 1963 "Invalid" 1962 "Invalid" 1961 "Invalid" 1960 "Invalid" 1959 "Invalid" 1958 "Invalid" 1957 "Invalid" 1956 "Invalid" 1955 "Invalid" 1954 "Invalid" 1953 "Invalid" 1952 "Invalid" 1951 "Invalid" 1950 "Invalid" 1949 "Invalid" 1948 "Invalid" 1947 "Invalid" 1946 "Invalid" 1945 "Invalid" 1944 "Invalid" 1943 "Invalid" 1942 "Invalid" 1941 "Invalid" 1940 "Invalid" 1939 "Invalid" 1938 "Invalid" 1937 "Invalid" 1936 "Invalid" 1935 "Invalid" 1934 "Invalid" 1933 "Invalid" 1932 "Invalid" 1931 "Invalid" 1930 "Invalid" 1929 "Invalid" 1928 "Invalid" 1927 "Invalid" 1926 "Invalid" 1925 "Invalid" 1924 "Invalid" 1923 "Invalid" 1922 "Invalid" 1921 "Invalid" 1920 "Invalid" 1919 "Invalid" 1918 "Invalid" 1917 "Invalid" 1916 "Invalid" 1915 "Invalid" 1914 "Invalid" 1913 "Invalid" 1912 "Invalid" 1911 "Invalid" 1910 "Invalid" 1909 "Invalid" 1908 "Invalid" 1907 "Invalid" 1906 "Invalid" 1905 "Invalid" 1904 "Invalid" 1903 "Invalid" 1902 "Invalid" 1901 "Invalid" 1900 "Invalid" 1899 "Invalid" 1898 "Invalid" 1897 "Invalid" 1896 "Invalid" 1895 "Invalid" 1894 "Invalid" 1893 "Invalid" 1892 "Invalid" 1891 "Invalid" 1890 "Invalid" 1889 "Invalid" 1888 "Invalid" 1887 "Invalid" 1886 "Invalid" 1885 "Invalid" 1884 "Invalid" 1883 "Invalid" 1882 "Invalid" 1881 "Invalid" 1880 "Invalid" 1879 "Invalid" 1878 "Invalid" 1877 "Invalid" 1876 "Invalid" 1875 "Invalid" 1874 "Invalid" 1873 "Invalid" 1872 "Invalid" 1871 "Invalid" 1870 "Invalid" 1869 "Invalid" 1868 "Invalid" 1867 "Invalid" 1866 "Invalid" 1865 "Invalid" 1864 "Invalid" 1863 "Invalid" 1862 "Invalid" 1861 "Invalid" 1860 "Invalid" 1859 "Invalid" 1858 "Invalid" 1857 "Invalid" 1856 "Invalid" 1855 "Invalid" 1854 "Invalid" 1853 "Invalid" 1852 "Invalid" 1851 "Invalid" 1850 "Invalid" 1849 "Invalid" 1848 "Invalid" 1847 "Invalid" 1846 "Invalid" 1845 "Invalid" 1844 "Invalid" 1843 "Invalid" 1842 "Invalid" 1841 "Invalid" 1840 "Invalid" 1839 "Invalid" 1838 "Invalid" 1837 "Invalid" 1836 "Invalid" 1835 "Invalid" 1834 "Invalid" 1833 "Invalid" 1832 "Invalid" 1831 "Invalid" 1830 "Invalid" 1829 "Invalid" 1828 "Invalid" 1827 "Invalid" 1826 "Invalid" 1825 "Invalid" 1824 "Invalid" 1823 "Invalid" 1822 "Invalid" 1821 "Invalid" 1820 "Invalid" 1819 "Invalid" 1818 "Invalid" 1817 "Invalid" 1816 "Invalid" 1815 "Invalid" 1814 "Invalid" 1813 "Invalid" 1812 "Invalid" 1811 "Invalid" 1810 "Invalid" 1809 "Invalid" 1808 "Invalid" 1807 "Invalid" 1806 "Invalid" 1805 "Invalid" 1804 "Invalid" 1803 "Invalid" 1802 "Invalid" 1801 "Invalid" ;
VAL_ 1070 BCU_CellVlt105_RM 2047 "Invalid" 2046 "Invalid" 2045 "Invalid" 2044 "Invalid" 2043 "Invalid" 2042 "Invalid" 2041 "Invalid" 2040 "Invalid" 2039 "Invalid" 2038 "Invalid" 2037 "Invalid" 2036 "Invalid" 2035 "Invalid" 2034 "Invalid" 2033 "Invalid" 2032 "Invalid" 2031 "Invalid" 2030 "Invalid" 2029 "Invalid" 2028 "Invalid" 2027 "Invalid" 2026 "Invalid" 2025 "Invalid" 2024 "Invalid" 2023 "Invalid" 2022 "Invalid" 2021 "Invalid" 2020 "Invalid" 2019 "Invalid" 2018 "Invalid" 2017 "Invalid" 2016 "Invalid" 2015 "Invalid" 2014 "Invalid" 2013 "Invalid" 2012 "Invalid" 2011 "Invalid" 2010 "Invalid" 2009 "Invalid" 2008 "Invalid" 2007 "Invalid" 2006 "Invalid" 2005 "Invalid" 2004 "Invalid" 2003 "Invalid" 2002 "Invalid" 2001 "Invalid" 2000 "Invalid" 1999 "Invalid" 1998 "Invalid" 1997 "Invalid" 1996 "Invalid" 1995 "Invalid" 1994 "Invalid" 1993 "Invalid" 1992 "Invalid" 1991 "Invalid" 1990 "Invalid" 1989 "Invalid" 1988 "Invalid" 1987 "Invalid" 1986 "Invalid" 1985 "Invalid" 1984 "Invalid" 1983 "Invalid" 1982 "Invalid" 1981 "Invalid" 1980 "Invalid" 1979 "Invalid" 1978 "Invalid" 1977 "Invalid" 1976 "Invalid" 1975 "Invalid" 1974 "Invalid" 1973 "Invalid" 1972 "Invalid" 1971 "Invalid" 1970 "Invalid" 1969 "Invalid" 1968 "Invalid" 1967 "Invalid" 1966 "Invalid" 1965 "Invalid" 1964 "Invalid" 1963 "Invalid" 1962 "Invalid" 1961 "Invalid" 1960 "Invalid" 1959 "Invalid" 1958 "Invalid" 1957 "Invalid" 1956 "Invalid" 1955 "Invalid" 1954 "Invalid" 1953 "Invalid" 1952 "Invalid" 1951 "Invalid" 1950 "Invalid" 1949 "Invalid" 1948 "Invalid" 1947 "Invalid" 1946 "Invalid" 1945 "Invalid" 1944 "Invalid" 1943 "Invalid" 1942 "Invalid" 1941 "Invalid" 1940 "Invalid" 1939 "Invalid" 1938 "Invalid" 1937 "Invalid" 1936 "Invalid" 1935 "Invalid" 1934 "Invalid" 1933 "Invalid" 1932 "Invalid" 1931 "Invalid" 1930 "Invalid" 1929 "Invalid" 1928 "Invalid" 1927 "Invalid" 1926 "Invalid" 1925 "Invalid" 1924 "Invalid" 1923 "Invalid" 1922 "Invalid" 1921 "Invalid" 1920 "Invalid" 1919 "Invalid" 1918 "Invalid" 1917 "Invalid" 1916 "Invalid" 1915 "Invalid" 1914 "Invalid" 1913 "Invalid" 1912 "Invalid" 1911 "Invalid" 1910 "Invalid" 1909 "Invalid" 1908 "Invalid" 1907 "Invalid" 1906 "Invalid" 1905 "Invalid" 1904 "Invalid" 1903 "Invalid" 1902 "Invalid" 1901 "Invalid" 1900 "Invalid" 1899 "Invalid" 1898 "Invalid" 1897 "Invalid" 1896 "Invalid" 1895 "Invalid" 1894 "Invalid" 1893 "Invalid" 1892 "Invalid" 1891 "Invalid" 1890 "Invalid" 1889 "Invalid" 1888 "Invalid" 1887 "Invalid" 1886 "Invalid" 1885 "Invalid" 1884 "Invalid" 1883 "Invalid" 1882 "Invalid" 1881 "Invalid" 1880 "Invalid" 1879 "Invalid" 1878 "Invalid" 1877 "Invalid" 1876 "Invalid" 1875 "Invalid" 1874 "Invalid" 1873 "Invalid" 1872 "Invalid" 1871 "Invalid" 1870 "Invalid" 1869 "Invalid" 1868 "Invalid" 1867 "Invalid" 1866 "Invalid" 1865 "Invalid" 1864 "Invalid" 1863 "Invalid" 1862 "Invalid" 1861 "Invalid" 1860 "Invalid" 1859 "Invalid" 1858 "Invalid" 1857 "Invalid" 1856 "Invalid" 1855 "Invalid" 1854 "Invalid" 1853 "Invalid" 1852 "Invalid" 1851 "Invalid" 1850 "Invalid" 1849 "Invalid" 1848 "Invalid" 1847 "Invalid" 1846 "Invalid" 1845 "Invalid" 1844 "Invalid" 1843 "Invalid" 1842 "Invalid" 1841 "Invalid" 1840 "Invalid" 1839 "Invalid" 1838 "Invalid" 1837 "Invalid" 1836 "Invalid" 1835 "Invalid" 1834 "Invalid" 1833 "Invalid" 1832 "Invalid" 1831 "Invalid" 1830 "Invalid" 1829 "Invalid" 1828 "Invalid" 1827 "Invalid" 1826 "Invalid" 1825 "Invalid" 1824 "Invalid" 1823 "Invalid" 1822 "Invalid" 1821 "Invalid" 1820 "Invalid" 1819 "Invalid" 1818 "Invalid" 1817 "Invalid" 1816 "Invalid" 1815 "Invalid" 1814 "Invalid" 1813 "Invalid" 1812 "Invalid" 1811 "Invalid" 1810 "Invalid" 1809 "Invalid" 1808 "Invalid" 1807 "Invalid" 1806 "Invalid" 1805 "Invalid" 1804 "Invalid" 1803 "Invalid" 1802 "Invalid" 1801 "Invalid" ;
